VERSION ""

NS_ :

BS_:

BU_: HS_TESTER CPM AHU MFD IPC DSP _delete

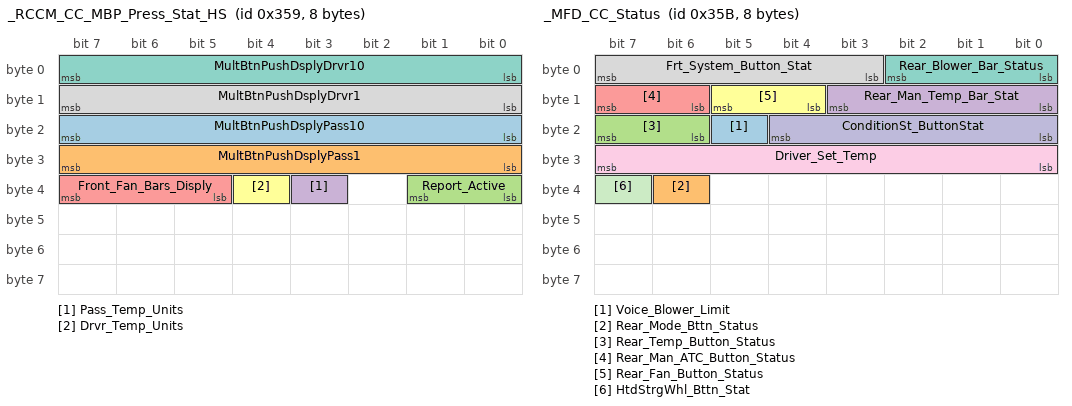
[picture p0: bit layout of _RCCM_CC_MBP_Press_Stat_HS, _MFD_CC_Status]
BO_ 857 _RCCM_CC_MBP_Press_Stat_HS: 8 IPC
 SG_ MultBtnPushDsplyPass10 : 23|8@0+ (1,0) [0|255] ""  MFD
 SG_ MultBtnPushDsplyPass1 : 31|8@0+ (1,0) [0|255] ""  MFD
 SG_ Report_Active : 33|2@0+ (1,0) [0|0] ""  MFD
 SG_ Pass_Temp_Units : 35|1@0+ (1,0) [0|0] ""  MFD
 SG_ Front_Fan_Bars_Disply : 39|3@0+ (1,0) [0|0] ""  MFD
 SG_ Drvr_Temp_Units : 36|1@0+ (1,0) [0|0] ""  MFD
 SG_ MultBtnPushDsplyDrvr10 : 7|8@0+ (1,0) [0|255] ""  MFD
 SG_ MultBtnPushDsplyDrvr1 : 15|8@0+ (1,0) [0|255] ""  MFD

BO_ 859 _MFD_CC_Status: 8 CPM
 SG_ Voice_Blower_Limit : 21|1@0+ (1,0) [0|0] "" Vector__XXX
 SG_ Rear_Mode_Bttn_Status : 38|1@0+ (1,0) [0|0] "unitless"  IPC
 SG_ Rear_Temp_Button_Status : 23|2@0+ (1,0) [0|0] "" Vector__XXX
 SG_ Rear_Man_Temp_Bar_Stat : 11|4@0+ (1,0) [0|0] "" Vector__XXX
 SG_ Rear_Man_ATC_Button_Status : 15|2@0+ (1,0) [0|0] "" Vector__XXX
 SG_ Rear_Fan_Button_Status : 13|2@0+ (1,0) [0|0] "" Vector__XXX
 SG_ Rear_Blower_Bar_Status : 2|3@0+ (1,0) [0|7] "" Vector__XXX
 SG_ Frt_System_Button_Stat : 7|5@0+ (1,0) [0|0] ""  IPC
 SG_ Driver_Set_Temp : 31|8@0+ (0.5,0) [16|90] "Degrees"  IPC
 SG_ ConditionSt_ButtonStat : 20|5@0+ (1,0) [0|0] "SED" Vector__XXX
 SG_ HtdStrgWhl_Bttn_Stat : 39|1@0+ (1,0) [0|0] "" Vector__XXX

BO_ 858 _IPC_CC_Request: 8 IPC
 SG_ Left_Front_Temp_Setpt : 7|8@0+ (1,0) [0|0] "Mixed"  MFD
 SG_ Front_Blower_Request : 15|5@0+ (1,0) [0|31] ""  MFD

BO_ 293 _ClmtCtrlSeatSetStat_v2_HS: 8 IPC
 SG_ ClmtCtrlSeat_SetStat_Psgr : 15|8@0+ (1,0) [0|254] "" Vector__XXX
 SG_ ClmtCtrlSeat_SetStat_Dvr : 7|8@0+ (1,0) [0|254] "" Vector__XXX

BO_ 1068 _Battery_Mgmt_2: 8 IPC
 SG_ BSBattSOC_UB : 56|1@0+ (1,0) [0|0] "" Vector__XXX
 SG_ BSBattSOC : 63|7@0+ (1,0) [0|127] "%" Vector__XXX
 SG_ Shed_T_Eng_Off_B_UB : 31|1@0+ (1,0) [0|1] "SED" Vector__XXX
 SG_ Shed_Drain_Eng_Off_B_UB : 22|1@0+ (1,0) [0|1] "SED" Vector__XXX
 SG_ PwPckTqRdy_B_Dsply_UB : 20|1@0+ (1,0) [0|1] "SED" Vector__XXX
 SG_ BattTracWarnLamp_B_Rq_UB : 15|1@0+ (1,0) [0|1] "SED" Vector__XXX
 SG_ BattTracWarnLamp_B_Rq : 1|1@0+ (1,0) [0|0] "SED" Vector__XXX
 SG_ BattTracSrvcRqd_B_Rq_UB : 14|1@0+ (1,0) [0|1] "SED" Vector__XXX
 SG_ BattTracSrvcRqd_B_Rq : 0|1@0+ (1,0) [0|0] "SED" Vector__XXX
 SG_ BattTracSoc_Pc_Dsply_UB : 52|1@0+ (1,0) [0|1] "SED" Vector__XXX
 SG_ BattTracSoc_Pc_Dsply : 39|8@0+ (0.5,0) [0|127.5] "%" Vector__XXX
 SG_ HtrnWarnLamp_B_Dsply_UB : 28|1@0+ (1,0) [0|1] "SED" Vector__XXX
 SG_ HtrnWarnLamp_B_Dsply : 19|1@0+ (1,0) [0|0] "SED" Vector__XXX
 SG_ HtrnSrvcRqd_B_Dsply_UB : 29|1@0+ (1,0) [0|1] "SED" Vector__XXX
 SG_ HtrnSrvcRqd_B_Dsply : 30|1@0+ (1,0) [0|0] "SED" Vector__XXX
 SG_ HtrnOvrTeLamp_B_Dsply_UB : 26|1@0+ (1,0) [0|1] "SED" Vector__XXX
 SG_ HtrnOvrTeLamp_B_Dsply : 27|1@0+ (1,0) [0|0] "SED" Vector__XXX
 SG_ PwPckTqRdy_B_Dsply : 21|1@0+ (1,0) [0|0] "SED" Vector__XXX
 SG_ Shed_T_Eng_Off_B : 17|1@0+ (1,0) [0|0] ""  MFD
 SG_ Shed_Level_Req : 55|3@0+ (1,0) [0|0] "SED"  MFD
 SG_ Shed_Drain_Eng_Off_B : 16|1@0+ (1,0) [0|0] ""  MFD
 SG_ Batt_Lo_SoC_B : 25|1@0+ (1,0) [0|0] "SED"  MFD
 SG_ Batt_Crit_SoC_B : 24|1@0+ (1,0) [0|0] "SED"  MFD
 SG_ VehDynamicsSOS : 51|1@0+ (1,0) [0|1] "SED" Vector__XXX
 SG_ VehDynamicsSOS_UB : 50|1@0+ (1,0) [0|1] "SED" Vector__XXX
 SG_ ObjectEntrapped_UB : 2|1@0+ (1,0) [0|1] "SED" Vector__XXX
 SG_ Batt_Lo_SoC_B_UB : 13|1@0+ (1,0) [0|1] "SED" Vector__XXX
 SG_ ObjectEntrapped : 3|1@0+ (1,0) [0|1] "SED" Vector__XXX
 SG_ Shed_Level_Req_UB : 18|1@0+ (1,0) [0|1] "SED" Vector__XXX
 SG_ PwSysULoFalt_D_Stat_UB : 23|1@0+ (1,0) [0|1] "SED" Vector__XXX
 SG_ PwSysULoFalt_D_Stat : 11|4@0+ (1,0) [0|15] "SED" Vector__XXX
 SG_ CcStat_D_Actl_UB : 4|1@0+ (1,0) [0|1] "SED" Vector__XXX
 SG_ CcStat_D_Actl : 7|3@0+ (1,0) [0|7] "SED" Vector__XXX
 SG_ Batt_Crit_SoC_B_UB : 12|1@0+ (1,0) [0|1] "SED" Vector__XXX
 SG_ TrlrAidEnbl_D_Stat_UB : 49|1@0+ (1,0) [0|0] "" Vector__XXX
 SG_ TrlrAidMsgTxt_D_Rq_UB : 48|1@0+ (1,0) [0|0] "" Vector__XXX
 SG_ TrlrAidEnbl_D_Stat : 42|3@0+ (1,0) [0|0] "SED" Vector__XXX
 SG_ TrlrAidMsgTxt_D_Rq : 47|5@0+ (1,0) [0|0] "SED" Vector__XXX

BO_ 1931 TesterPhysicalResDSP: 8 DSP
 SG_ TesterPhysicalResDSP : 7|64@0+ (1,0) [0|1.84467440737096E+019] "unitless"  IPC

BO_ 757 ACU_Send_Signals_13: 8 AHU
 SG_ ACU_AutoStoreResult_St : 1|2@0+ (1,0) [0|0] "unitless"  MFD
 SG_ ACU_DirectTune_St : 3|2@0+ (1,0) [0|0] "unitless"  CPM,MFD,IPC
 SG_ ACU_RadioSeekMode2_St : 15|5@0+ (1,0) [0|0] "unitless"  MFD,IPC
 SG_ ACU_CurrTUBand_St : 7|4@0+ (1,0) [0|0] "unitless"  CPM,MFD,DSP,IPC

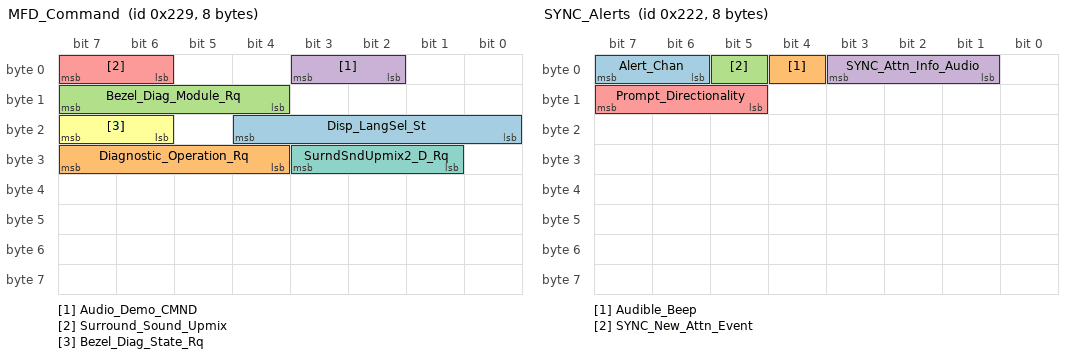
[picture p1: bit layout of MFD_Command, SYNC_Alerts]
BO_ 553 MFD_Command: 8 MFD
 SG_ Disp_LangSel_St : 20|5@0+ (1,0) [0|0] "unitless"  CPM,IPC
 SG_ Diagnostic_Operation_Rq : 31|4@0+ (1,0) [0|0] ""  DSP,AHU
 SG_ Bezel_Diag_Module_Rq : 15|4@0+ (1,0) [0|0] ""  DSP,AHU
 SG_ Audio_Demo_CMND : 3|2@0+ (1,0) [0|0] ""  DSP,AHU
 SG_ Surround_Sound_Upmix : 7|2@0+ (1,0) [0|0] ""  DSP
 SG_ Bezel_Diag_State_Rq : 23|2@0+ (1,0) [0|0] ""  DSP,AHU
 SG_ SurndSndUpmix2_D_Rq : 27|3@0+ (1,0) [0|0] ""  DSP

BO_ 257 MFD_Request_Signals1: 8 MFD
 SG_ MFD_SetTagMode : 39|2@0+ (1,0) [0|0] ""  AHU
 SG_ MFD_SetRBDSMode : 47|2@0+ (1,0) [0|0] ""  AHU
 SG_ MFD_SetHDModeRq : 31|2@0+ (1,0) [0|0] ""  AHU
 SG_ MFD_GetTagInfo : 7|4@0+ (1,0) [0|0] ""  AHU

BO_ 546 SYNC_Alerts: 8 CPM
 SG_ Alert_Chan : 7|2@0+ (1,0) [0|0] ""  DSP,AHU
 SG_ Audible_Beep : 4|1@0+ (1,0) [0|0] ""  DSP,AHU
 SG_ SYNC_New_Attn_Event : 5|1@0+ (1,0) [0|0] "SED"  DSP,AHU
 SG_ SYNC_Attn_Info_Audio : 3|3@0+ (1,0) [0|0] "SED"  DSP,AHU
 SG_ Prompt_Directionality : 15|3@0+ (1,0) [0|0] ""  DSP,AHU

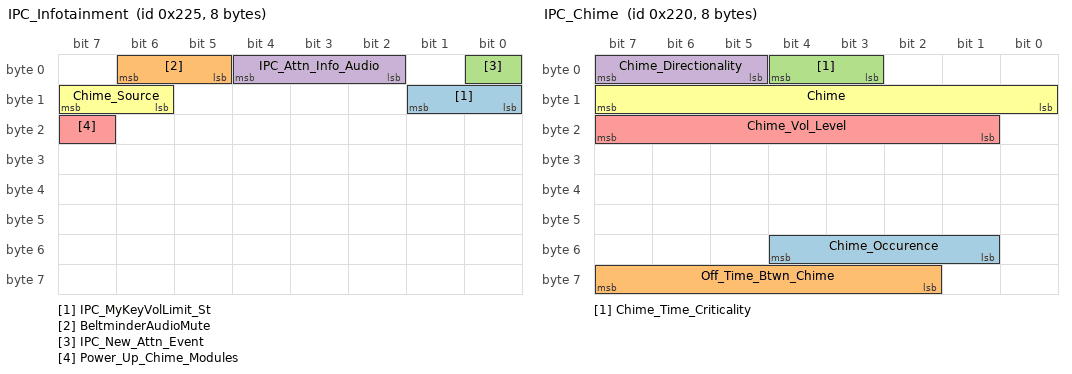
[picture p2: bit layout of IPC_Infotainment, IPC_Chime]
BO_ 549 IPC_Infotainment: 8 IPC
 SG_ IPC_MyKeyVolLimit_St : 9|2@0+ (1,0) [0|0] ""  DSP,AHU
 SG_ BeltminderAudioMute : 6|2@0+ (1,0) [0|0] "unitless"  DSP,AHU
 SG_ IPC_New_Attn_Event : 0|1@0+ (1,0) [0|0] ""  DSP,AHU
 SG_ IPC_Attn_Info_Audio : 4|3@0+ (1,0) [0|0] "SED"  DSP,AHU
 SG_ Power_Up_Chime_Modules : 23|1@0+ (1,0) [0|0] "unitless"  DSP,AHU
 SG_ Chime_Source : 15|2@0+ (1,0) [0|0] "unitless"  DSP,AHU

BO_ 544 IPC_Chime: 8 IPC
 SG_ Chime_Occurence : 52|4@0+ (1,0) [0|0] "unitless"  AHU,DSP
 SG_ Off_Time_Btwn_Chime : 63|6@0+ (1,0) [0|52] "unitless"  AHU,DSP
 SG_ Chime_Time_Criticality : 4|2@0+ (1,0) [0|0] "unitless"  AHU,DSP
 SG_ Chime_Directionality : 7|3@0+ (1,0) [0|0] "unitless"  AHU,DSP
 SG_ Chime_Vol_Level : 23|7@0+ (1,0) [0|127] "unitless"  AHU,DSP
 SG_ Chime : 15|8@0+ (1,0) [0|255] "unitless"  AHU,DSP

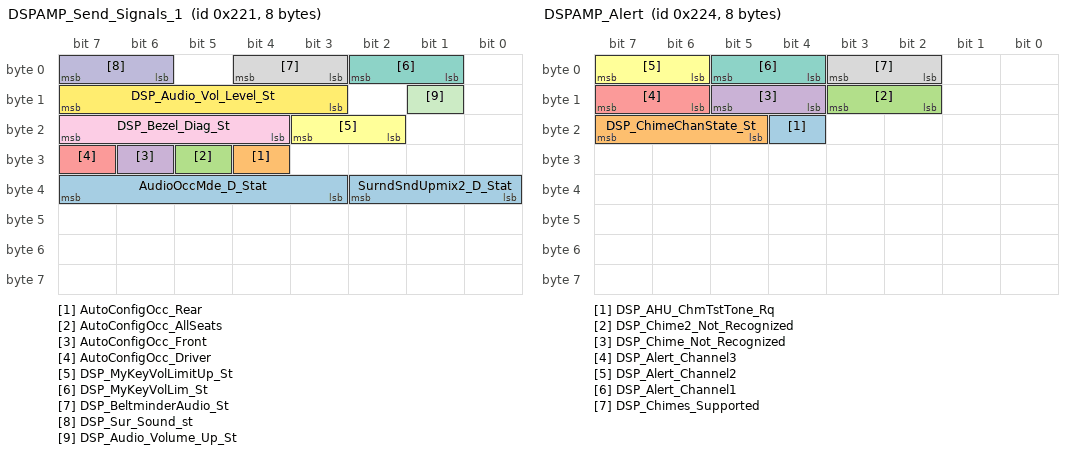
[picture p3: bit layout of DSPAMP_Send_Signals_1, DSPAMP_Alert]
BO_ 545 DSPAMP_Send_Signals_1: 8 DSP
 SG_ AudioOccMde_D_Stat : 39|5@0+ (1,0) [0|0] "" Vector__XXX
 SG_ AutoConfigOcc_Rear : 28|1@0+ (1,0) [0|0] "" Vector__XXX
 SG_ AutoConfigOcc_AllSeats : 29|1@0+ (1,0) [0|0] "" Vector__XXX
 SG_ AutoConfigOcc_Front : 30|1@0+ (1,0) [0|0] "" Vector__XXX
 SG_ AutoConfigOcc_Driver : 31|1@0+ (1,0) [0|0] "" Vector__XXX
 SG_ DSP_MyKeyVolLimitUp_St : 19|2@0+ (1,0) [0|0] ""  MFD
 SG_ DSP_MyKeyVolLim_St : 2|2@0+ (1,0) [0|0] ""  MFD
 SG_ DSP_BeltminderAudio_St : 4|2@0+ (1,0) [0|0] ""  MFD
 SG_ DSP_Bezel_Diag_St : 23|4@0+ (1,0) [0|0] ""  MFD
 SG_ DSP_Sur_Sound_st : 7|2@0+ (1,0) [0|0] ""  MFD
 SG_ DSP_Audio_Volume_Up_St : 9|1@0+ (1,0) [0|0] ""  MFD
 SG_ DSP_Audio_Vol_Level_St : 15|5@0+ (1,0) [0|31] "percent"  MFD
 SG_ SurndSndUpmix2_D_Stat : 34|3@0+ (1,0) [0|0] "" Vector__XXX

BO_ 552 DSPAMP_Send_Signals: 8 DSP
 SG_ DSP_Midrange_St : 51|4@0+ (1,-7) [-7|8] ""  MFD
 SG_ DSP_VoiceFBVolume_Up : 35|1@0+ (1,0) [0|0] ""  MFD
 SG_ DSP_VoiceFBVolume_St : 63|5@0+ (1,0) [0|30] ""  MFD
 SG_ DSP_Treble_St : 55|4@0+ (1,-7) [-7|8] ""  MFD
 SG_ DSP_TAVolume_Up : 34|1@0+ (1,0) [0|0] ""  MFD
 SG_ DSP_TAVolume_St : 44|5@0+ (1,0) [0|30] ""  MFD
 SG_ DSP_PhoneVolume_Up : 25|1@0+ (1,0) [0|0] ""  MFD
 SG_ DSP_PhoneVolume_St : 33|5@0+ (1,0) [0|30] ""  MFD
 SG_ DSP_NavCmdVolume_Up : 7|1@0+ (1,0) [0|0] ""  MFD
 SG_ DSP_NavCmdVolume_St : 24|5@0+ (1,0) [0|30] ""  MFD
 SG_ DSP_Fader_St : 20|4@0+ (1,-7) [-7|8] ""  MFD
 SG_ DSP_DSPProgram_St : 15|3@0+ (1,0) [0|0] ""  MFD
 SG_ DSP_DSP_St : 16|5@0+ (1,0) [0|0] ""  MFD
 SG_ DSP_Bass_St : 12|4@0+ (1,-7) [-7|8] ""  MFD
 SG_ DSP_Balance_St : 8|4@0+ (1,-7) [-7|8] ""  MFD
 SG_ DSP_AVC_St : 6|3@0+ (1,0) [0|0] ""  MFD
 SG_ DSP_Shaker_St : 1|1@0+ (1,0) [0|0] ""  MFD
 SG_ Audio_Demo_Status : 0|1@0+ (1,0) [0|0] ""  MFD

BO_ 548 DSPAMP_Alert: 8 DSP
 SG_ DSP_AHU_ChmTstTone_Rq : 20|1@0+ (1,0) [0|0] ""  AHU
 SG_ DSP_ChimeChanState_St : 23|3@0+ (1,0) [0|0] ""  AHU
 SG_ DSP_Chime2_Not_Recognized : 11|2@0+ (1,0) [0|0] "unitless"  IPC
 SG_ DSP_Chime_Not_Recognized : 13|2@0+ (1,0) [0|0] "unitless"  IPC
 SG_ DSP_Alert_Channel3 : 15|2@0+ (1,0) [0|0] "unitless"  IPC
 SG_ DSP_Alert_Channel2 : 7|2@0+ (1,0) [0|0] "unitless"  IPC,AHU
 SG_ DSP_Alert_Channel1 : 5|2@0+ (1,0) [0|0] ""  AHU
 SG_ DSP_Chimes_Supported : 3|2@0+ (1,0) [0|0] "unitless"  AHU,IPC

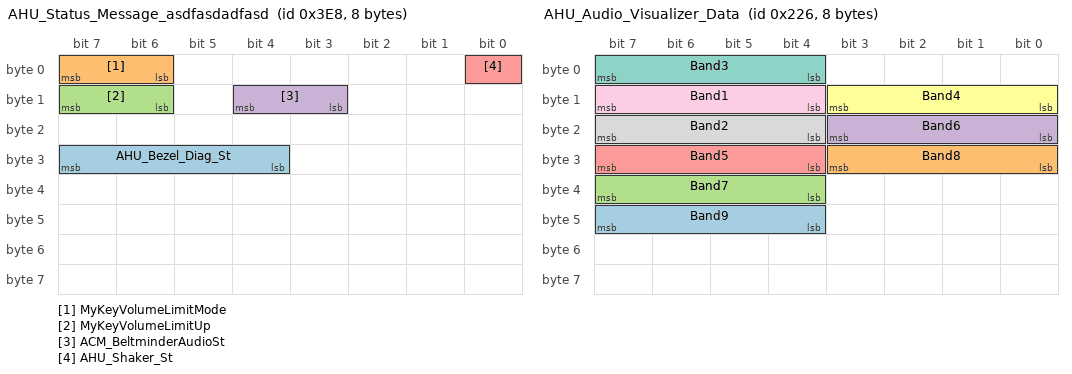
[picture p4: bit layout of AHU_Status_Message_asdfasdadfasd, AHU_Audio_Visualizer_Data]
BO_ 1000 AHU_Status_Message_asdfasdadfasd: 8 AHU
 SG_ AHU_Bezel_Diag_St : 31|4@0+ (1,0) [0|0] ""  MFD
 SG_ MyKeyVolumeLimitMode : 7|2@0+ (1,0) [0|0] ""  MFD
 SG_ MyKeyVolumeLimitUp : 15|2@0+ (1,0) [0|0] ""  MFD
 SG_ ACM_BeltminderAudioSt : 12|2@0+ (1,0) [0|0] ""  MFD
 SG_ AHU_Shaker_St : 0|1@0+ (1,0) [0|0] ""  MFD

BO_ 1478 DSP_AutoSar_Network_Mgmt: 8 DSP
 SG_ DSP_AutoSar_Network_Mgmt : 7|64@0+ (1,0) [0|1.8446744074E+019] "unitless" Vector__XXX

BO_ 1506 APIM_AutoSar_Network_Mgmt: 8 CPM
 SG_ APIM_AutoSar_Network_Mgmt : 7|64@0+ (1,0) [0|1.8446744074E+019] "unitless" Vector__XXX

BO_ 1034 _GGCC_Config_Mgmt_ID_1: 8 IPC
 SG_ VehicleGGCCData : 7|64@0+ (1,0) [0|1.84467E+019] "mixed"  CPM,AHU

BO_ 405 LBClient1_Request_Signals: 8 IPC
 SG_ LBC1_StartItemInd : 55|16@0+ (1,0) [0|65535] "unitless" Vector__XXX
 SG_ LBC1_SetListServ : 47|8@0+ (1,0) [0|255] "unitless" Vector__XXX
 SG_ LBC1_Opcode : 39|2@0+ (1,0) [0|3] "unitless" Vector__XXX
 SG_ LBC1_NbrOfItems : 37|6@0+ (1,0) [0|63] "unitless" Vector__XXX
 SG_ LBC1_ItemIndex : 23|16@0+ (1,0) [0|65535] "unitless" Vector__XXX
 SG_ LBC1_ActiveListID : 7|16@0+ (1,0) [0|65535] "unitless" Vector__XXX

BO_ 550 AHU_Audio_Visualizer_Data: 8 AHU
 SG_ Band9 : 47|4@0+ (1,0) [0|0] "" Vector__XXX
 SG_ Band8 : 27|4@0+ (1,0) [0|0] "" Vector__XXX
 SG_ Band7 : 39|4@0+ (1,0) [0|0] "" Vector__XXX
 SG_ Band6 : 19|4@0+ (1,0) [0|0] "" Vector__XXX
 SG_ Band5 : 31|4@0+ (1,0) [0|0] "" Vector__XXX
 SG_ Band4 : 11|4@0+ (1,0) [0|0] "" Vector__XXX
 SG_ Band3 : 7|4@0+ (1,0) [0|0] "" Vector__XXX
 SG_ Band2 : 23|4@0+ (1,0) [0|0] "" Vector__XXX
 SG_ Band1 : 15|4@0+ (1,0) [0|0] "" Vector__XXX

BO_ 755 ACU_Send_Signals_11: 8 AHU
 SG_ ACU_AudioMixRatio_St : 4|5@0+ (1,0) [0|20] "decibel"  MFD

BO_ 692 AUDIO_RDISP_WORD_Tx: 8 AHU
 SG_ AUDIO_RDISP_WORD_Tx : 7|64@0+ (1,0) [0|1.84467440737096E+019] "unitless"  MFD

BO_ 700 AUDIO_RDISP_WORD_Rx: 8 MFD
 SG_ AUDIO_RDISP_WORD_Rx : 7|64@0+ (1,0) [0|1.84467440737096E+019] "unitless"  AHU

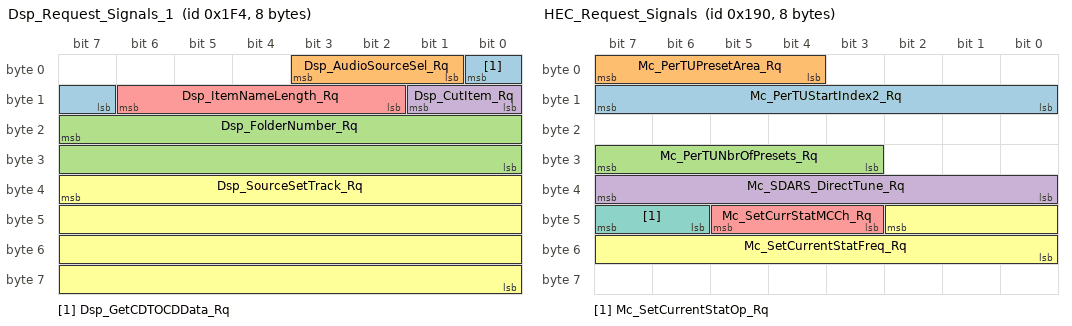
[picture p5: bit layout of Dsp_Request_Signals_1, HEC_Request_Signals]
BO_ 500 Dsp_Request_Signals_1: 8 MFD
 SG_ Dsp_GetCDTOCDData_Rq : 0|2@0+ (1,0) [0|0] ""  AHU
 SG_ Dsp_AudioSourceSel_Rq : 3|3@0+ (1,0) [0|0] ""  AHU
 SG_ Dsp_FolderNumber_Rq : 23|16@0+ (1,0) [0|65535] ""  AHU
 SG_ Dsp_CutItem_Rq : 9|2@0+ (1,0) [0|0] ""  AHU
 SG_ Dsp_ItemNameLength_Rq : 14|5@0+ (1,0) [0|20] ""  AHU
 SG_ Dsp_SourceSetTrack_Rq : 39|32@0+ (1,0) [0|4294967295] ""  AHU

BO_ 501 Dsp_Request_Signals_2: 8 MFD
 SG_ Dsp_FreezeFMSL_Rq : 57|2@0+ (1,0) [0|0] ""  AHU
 SG_ Dsp_SetCurrFMSLPr_Rq : 15|8@0+ (1,0) [0|254] ""  AHU
 SG_ Dsp_SetRadSeekMode_Rq : 61|4@0+ (1,0) [0|0] ""  AHU
 SG_ Dsp_SetCurrPreset2_Rq : 4|5@0+ (1,0) [0|30] ""  AHU

BO_ 503 Dsp_Request_Signals_4: 8 MFD
 SG_ Dsp_AudioSourceSel3_Rq : 55|3@0+ (1,0) [0|0] ""  AHU
 SG_ Dsp_PlayFrstTrInFldr_Rq : 39|16@0+ (1,0) [0|65535] ""  AHU

BO_ 698 CONMP_RDISP_WORD_Rx: 8 MFD
 SG_ CONMP_RDISP_WORD_Rx : 7|64@0+ (1,0) [0|1.84467440737096E+019] "unitless" Vector__XXX

BO_ 702 PHONE_MC_WORD_Rx: 8 IPC
 SG_ PHONE_MC_WORD_Rx : 7|64@0+ (1,0) [0|1.84467440737096E+019] "unitless" Vector__XXX

BO_ 699 PHONE_RDSP_WORD_Rx: 8 MFD
 SG_ PHONE_RDSP_WORD_Rx : 7|64@0+ (1,0) [0|1.84467440737096E+019] "unitless"  CPM

BO_ 691 PHONE_RDSP_WORD_Tx: 8 CPM
 SG_ PHONE_RDSP_WORD_Tx : 7|64@0+ (1,0) [0|1.84467440737096E+019] "unitless"  MFD

BO_ 689 AUDIO_MC_WORD_Tx: 8 AHU
 SG_ AUDIO_MC_WORD_Tx : 7|64@0+ (1,0) [0|1.84467440737096E+019] "unitless"  IPC

BO_ 401 MFD_Request_Signals4: 8 MFD
 SG_ Disp_VehUnitTripCoUsrSel : 3|2@0+ (1,0) [0|0] "unitless"  IPC
 SG_ Disp_VehUnitTempUsrSel : 5|2@0+ (1,0) [0|0] "unitless"  IPC
 SG_ Disp_LangSel_Rq : 15|5@0+ (1,0) [0|0] "unitless"  IPC

BO_ 400 HEC_Request_Signals: 8 IPC
 SG_ Mc_PerTUStartIndex2_Rq : 15|8@0+ (1,0) [0|255] "unitless" Vector__XXX
 SG_ Mc_PerTUPresetArea_Rq : 7|4@0+ (1,0) [0|0] "unitless" Vector__XXX
 SG_ Mc_PerTUNbrOfPresets_Rq : 31|5@0+ (1,0) [0|30] "unitless" Vector__XXX
 SG_ Mc_SDARS_DirectTune_Rq : 39|8@0+ (1,0) [0|255] "unitless"  AHU
 SG_ Mc_SetCurrStatMCCh_Rq : 45|3@0+ (1,0) [0|0] "unitless"  AHU
 SG_ Mc_SetCurrentStatFreq_Rq : 42|11@0+ (1,0) [0|1557] "unitless"  AHU
 SG_ Mc_SetCurrentStatOp_Rq : 47|2@0+ (1,0) [0|0] "unitless"  AHU

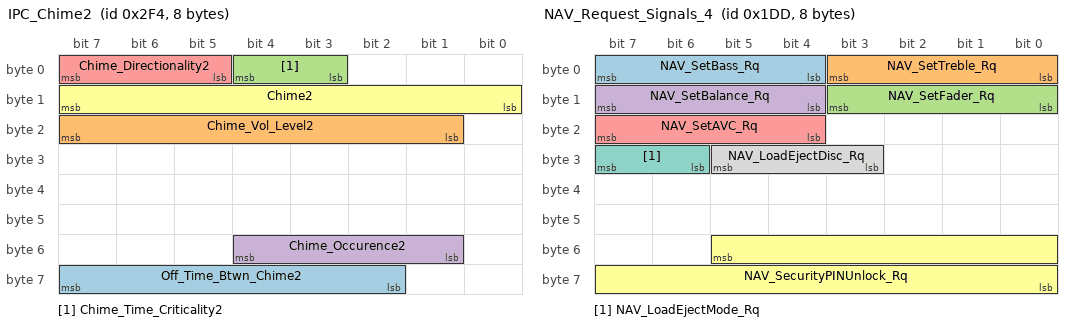
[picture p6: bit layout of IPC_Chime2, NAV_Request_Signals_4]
BO_ 756 IPC_Chime2: 8 IPC
 SG_ Off_Time_Btwn_Chime2 : 63|6@0+ (1,0) [0|52] "unitless"  AHU,DSP
 SG_ Chime_Vol_Level2 : 23|7@0+ (1,0) [0|127] "unitless"  DSP,AHU
 SG_ Chime_Time_Criticality2 : 4|2@0+ (1,0) [0|0] "unitless"  AHU,DSP
 SG_ Chime_Occurence2 : 52|4@0+ (1,0) [0|0] "unitless"  AHU,DSP
 SG_ Chime_Directionality2 : 7|3@0+ (1,0) [0|0] "unitless"  AHU,DSP
 SG_ Chime2 : 15|8@0+ (1,0) [0|255] "unitless"  AHU,DSP

BO_ 1425 IPC_AutoSar_Network_Mgmt: 8 IPC
 SG_ IPC_AutoSar_Network_Mgmt : 7|64@0+ (1,0) [0|1.8446744074E+019] "unitless" Vector__XXX

BO_ 477 NAV_Request_Signals_4: 8 MFD
 SG_ NAV_SetBass_Rq : 7|4@0+ (1,-7) [-7|8] ""  AHU,DSP
 SG_ NAV_SetTreble_Rq : 3|4@0+ (1,-7) [-7|8] ""  AHU,DSP
 SG_ NAV_SetFader_Rq : 11|4@0+ (1,-7) [-7|8] ""  AHU,DSP
 SG_ NAV_SetBalance_Rq : 15|4@0+ (1,-7) [-7|8] ""  AHU,DSP
 SG_ NAV_SetAVC_Rq : 23|4@0+ (1,0) [0|15] ""  AHU,DSP
 SG_ NAV_SecurityPINUnlock_Rq : 53|14@0+ (1,0) [0|16383] ""  AHU
 SG_ NAV_LoadEjectMode_Rq : 31|2@0+ (1,0) [0|0] ""  AHU
 SG_ NAV_LoadEjectDisc_Rq : 29|3@0+ (1,0) [0|0] ""  AHU

BO_ 476 NAV_Request_Signals_3: 8 MFD
 SG_ NAV_SetDSPProgram_Rq : 13|3@0+ (1,0) [0|0] ""  AHU,DSP
 SG_ NAV_SkipCatalouge_Rq : 7|2@0+ (1,0) [0|0] ""  AHU
 SG_ NAV_SetOperationMode_Rq : 26|3@0+ (1,0) [0|0] ""  AHU
 SG_ Nav_SetAudioMixRatio_Rq : 31|5@0+ (1,0) [0|20] "decibel"  AHU

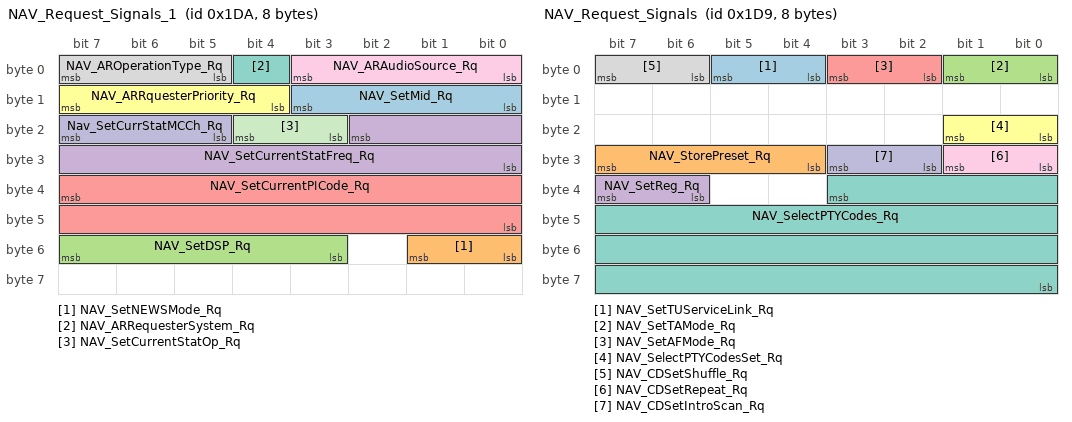
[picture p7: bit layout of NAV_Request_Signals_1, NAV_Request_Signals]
BO_ 474 NAV_Request_Signals_1: 8 MFD
 SG_ NAV_SetMid_Rq : 11|4@0+ (1,-7) [-7|8] ""  AHU,DSP
 SG_ NAV_SetNEWSMode_Rq : 49|2@0+ (1,0) [0|0] ""  AHU
 SG_ NAV_SetDSP_Rq : 55|5@0+ (1,0) [0|0] ""  AHU
 SG_ NAV_SetCurrentStatFreq_Rq : 18|11@0+ (1,0) [0|1557] ""  AHU
 SG_ NAV_SetCurrentPICode_Rq : 39|16@0+ (1,0) [0|65535] ""  AHU
 SG_ NAV_ARRquesterPriority_Rq : 15|4@0+ (1,0) [0|0] ""  DSP,AHU
 SG_ NAV_ARRequesterSystem_Rq : 4|1@0+ (1,0) [0|0] ""  DSP,AHU
 SG_ NAV_AROperationType_Rq : 7|3@0+ (1,0) [0|0] ""  DSP,AHU
 SG_ NAV_ARAudioSource_Rq : 3|4@0+ (1,0) [0|0] ""  DSP,AHU
 SG_ Nav_SetCurrStatMCCh_Rq : 23|3@0+ (1,0) [0|0] ""  AHU
 SG_ NAV_SetCurrentStatOp_Rq : 20|2@0+ (1,0) [0|0] ""  AHU

BO_ 473 NAV_Request_Signals: 8 MFD
 SG_ NAV_SetTUServiceLink_Rq : 5|2@0+ (1,0) [0|0] ""  AHU
 SG_ NAV_StorePreset_Rq : 31|4@0+ (1,0) [0|0] ""  AHU
 SG_ NAV_SetTAMode_Rq : 1|2@0+ (1,0) [0|0] ""  AHU
 SG_ NAV_SetReg_Rq : 39|2@0+ (1,0) [0|0] ""  AHU
 SG_ NAV_SetAFMode_Rq : 3|2@0+ (1,0) [0|0] ""  AHU
 SG_ NAV_SelectPTYCodesSet_Rq : 17|2@0+ (1,0) [0|0] ""  AHU
 SG_ NAV_SelectPTYCodes_Rq : 35|28@0+ (1,0) [0|268435455] ""  AHU
 SG_ NAV_CDSetShuffle_Rq : 7|2@0+ (1,0) [0|0] ""  AHU
 SG_ NAV_CDSetRepeat_Rq : 25|2@0+ (1,0) [0|0] ""  AHU
 SG_ NAV_CDSetIntroScan_Rq : 27|2@0+ (1,0) [0|0] ""  AHU

BO_ 479 DISP_Request_Signals: 8 MFD
 SG_ DISP_SetVol_Source_Rq : 19|4@0+ (1,0) [0|0] ""  DSP,AHU
 SG_ DISP_SetVol_Level_Rq : 13|6@0+ (1,0) [0|63] ""  DSP,AHU
 SG_ DISP_SetVolume_Rq : 5|6@0+ (1,-30) [-30|30] ""  AHU,DSP

BO_ 726 ACU_Send_Signals_8: 8 AHU
 SG_ ACU_AFJump_St : 51|2@0+ (1,0) [0|0] ""  MFD
 SG_ ACU_NEWSMode_St : 55|2@0+ (1,0) [0|0] ""  MFD
 SG_ ACU_SelectedPTYCodes_St : 4|29@0+ (1,0) [0|536870911] ""  MFD
 SG_ ACU_TAMode_St : 53|2@0+ (1,0) [0|0] ""  MFD

BO_ 727 ACU_Send_Signals_2: 8 AHU
 SG_ ACU_LoadEjectDisc_St : 2|3@0+ (1,0) [0|0] ""  MFD
 SG_ ACU_LoadEjectMode_St : 7|4@0+ (1,0) [0|0] ""  MFD

BO_ 119 BrakeSnData_3_HS3: 8 IPC
 SG_ BpedDrvAppl_D_Actl_UB : 55|1@0+ (1,0) [0|1] "SED" Vector__XXX
 SG_ BpedDrvAppl_D_Actl : 21|2@0+ (1,0) [0|0] "SED" Vector__XXX
 SG_ HsaStat_D_Actl_UB : 48|1@0+ (1,0) [0|1] "SED" Vector__XXX
 SG_ HsaStat_D_Actl : 51|3@0+ (1,0) [0|7] "SED" Vector__XXX
 SG_ EPAS_Failure : 53|2@0+ (1,0) [0|3] "SED" Vector__XXX
 SG_ EPAS_Failure_UB : 5|1@0+ (1,0) [0|1] "SED" Vector__XXX
 SG_ SAPPStatusCoding_UB : 54|1@0+ (1,0) [0|1] "SED"  MFD
 SG_ SAPPStatusCoding : 63|8@0+ (1,0) [0|255] "unitless"  MFD
 SG_ CcOvrrdActv_B_Actl_UB : 40|1@0+ (1,0) [0|1] "SED" Vector__XXX
 SG_ CcOvrrdActv_B_Actl : 41|1@0+ (1,0) [0|1] "SED" Vector__XXX
 SG_ EngPullUpPullDown_D_Rq_UB : 42|1@0+ (1,0) [0|1] "SED" Vector__XXX
 SG_ EngPullUpPullDown_D_Rq : 46|4@0+ (1,0) [0|15] "SED" Vector__XXX
 SG_ VehYawComp_W_Actl_UB : 6|1@0+ (1,0) [0|1] "SED" Vector__XXX
 SG_ Veh_V_DsplyCcSet : 39|8@0+ (1,0) [0|253] "Unitless" Vector__XXX
 SG_ VehYawComp_W_Actl : 3|12@0+ (0.03663,-75) [-75|74.92659] "deg/s" Vector__XXX
 SG_ VehYaw_W_Rq : 19|12@0+ (0.03663,-75) [-75|74.92659] "deg/s" Vector__XXX
 SG_ Veh_V_DsplyCcSet_UB : 4|1@0+ (1,0) [0|1] "SED" Vector__XXX
 SG_ VehYaw_W_Rq_UB : 7|1@0+ (1,0) [0|1] "SED" Vector__XXX

BO_ 2015 TesterFunctionalReq_H3: 8 AHU
 SG_ TesterFunctionalReq : 7|64@0+ (1,0) [0|0] ""  AHU,CPM,DSP,MFD,IPC

BO_ 1839 TesterPhysicalResACM: 8 AHU
 SG_ TesterPhysicalResACM : 7|64@0+ (1,0) [0|1.84467440737096E+019] "unitless"  MFD

BO_ 1831 TesterPhysicalReqACM: 8 MFD
 SG_ TesterPhysicalReqACM : 7|64@0+ (1,0) [0|1.84467440737096E+019] "unitless"  AHU

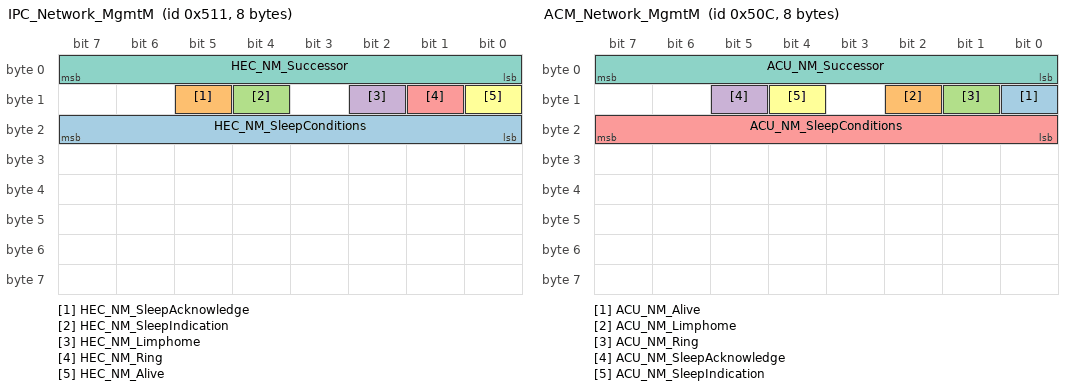
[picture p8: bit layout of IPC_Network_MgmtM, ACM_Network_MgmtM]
BO_ 1297 IPC_Network_MgmtM: 8 IPC
 SG_ HEC_NM_SleepConditions : 23|8@0+ (1,0) [0|0] "" Vector__XXX
 SG_ HEC_NM_SleepAcknowledge : 13|1@0+ (1,0) [0|0] "" Vector__XXX
 SG_ HEC_NM_SleepIndication : 12|1@0+ (1,0) [0|0] "" Vector__XXX
 SG_ HEC_NM_Limphome : 10|1@0+ (1,0) [0|0] "" Vector__XXX
 SG_ HEC_NM_Ring : 9|1@0+ (1,0) [0|0] "" Vector__XXX
 SG_ HEC_NM_Alive : 8|1@0+ (1,0) [0|0] "" Vector__XXX
 SG_ HEC_NM_Successor : 7|8@0+ (1,0) [0|0] "" Vector__XXX

BO_ 1292 ACM_Network_MgmtM: 8 AHU
 SG_ ACU_NM_Alive : 8|1@0+ (1,0) [0|0] "" Vector__XXX
 SG_ ACU_NM_Limphome : 10|1@0+ (1,0) [0|0] "" Vector__XXX
 SG_ ACU_NM_Ring : 9|1@0+ (1,0) [0|0] "" Vector__XXX
 SG_ ACU_NM_SleepAcknowledge : 13|1@0+ (1,0) [0|0] "" Vector__XXX
 SG_ ACU_NM_SleepConditions : 23|8@0+ (1,0) [0|0] "" Vector__XXX
 SG_ ACU_NM_SleepIndication : 12|1@0+ (1,0) [0|0] "" Vector__XXX
 SG_ ACU_NM_Successor : 7|8@0+ (1,0) [0|0] "" Vector__XXX

BO_ 1241 EATC_MCM: 8 IPC
 SG_ EATC_TempRangeOffset : 31|8@0+ (0.5,0) [0|127] "degC"  MFD
 SG_ EATC_TempRangeStart : 23|8@0+ (0.5,0) [0|127] "degC"  MFD
 SG_ EATC_BlowerSpeedMAX : 15|4@0+ (1,0) [0|14] ""  MFD
 SG_ EATC_BlowerSpeedMIN : 3|4@0+ (1,0) [0|14] ""  MFD

BO_ 1239 HEC_MCM: 8 IPC
 SG_ HEC_NbrOfItems_St : 27|5@0+ (1,0) [0|31] "" Vector__XXX
 SG_ HEC_ItemNameLength_St : 17|6@0+ (1,0) [0|63] "" Vector__XXX
 SG_ HEC_CutItem_St : 19|2@0+ (1,0) [0|0] "" Vector__XXX
 SG_ HEC_VehicleConfig : 23|2@0+ (1,0) [0|0] ""  MFD

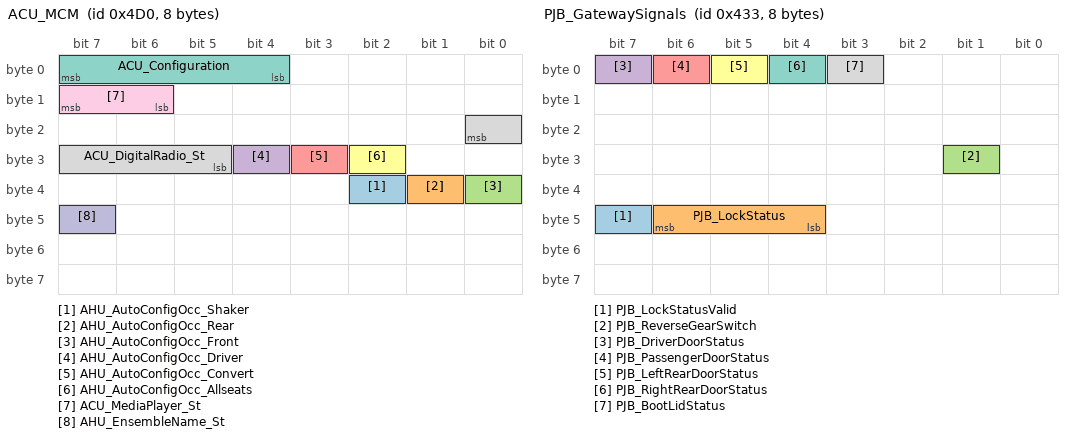
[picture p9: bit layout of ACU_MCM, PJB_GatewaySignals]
BO_ 1232 ACU_MCM: 8 AHU
 SG_ AHU_AutoConfigOcc_Shaker : 34|1@0+ (1,0) [0|0] ""  MFD
 SG_ AHU_AutoConfigOcc_Rear : 33|1@0+ (1,0) [0|0] ""  MFD
 SG_ AHU_AutoConfigOcc_Front : 32|1@0+ (1,0) [0|0] ""  MFD
 SG_ AHU_AutoConfigOcc_Driver : 28|1@0+ (1,0) [0|0] ""  MFD
 SG_ AHU_AutoConfigOcc_Convert : 27|1@0+ (1,0) [0|0] ""  MFD
 SG_ AHU_AutoConfigOcc_Allseats : 26|1@0+ (1,0) [0|0] ""  MFD
 SG_ ACU_Configuration : 7|4@0+ (1,0) [0|0] ""  MFD,IPC
 SG_ ACU_DigitalRadio_St : 16|4@0+ (1,0) [0|0] ""  MFD
 SG_ ACU_MediaPlayer_St : 15|2@0+ (1,0) [0|0] ""  MFD,IPC
 SG_ AHU_EnsembleName_St : 47|1@0+ (1,0) [0|0] ""  MFD

BO_ 1075 PJB_GatewaySignals: 8 IPC
 SG_ PJB_LockStatusValid : 47|1@0+ (1,0) [0|0] ""  MFD
 SG_ PJB_LockStatus : 46|3@0+ (1,0) [0|0] ""  MFD
 SG_ PJB_ReverseGearSwitch : 25|1@0+ (1,0) [0|0] "" Vector__XXX
 SG_ PJB_DriverDoorStatus : 7|1@0+ (1,0) [0|0] ""  CPM,MFD
 SG_ PJB_PassengerDoorStatus : 6|1@0+ (1,0) [0|0] ""  MFD
 SG_ PJB_LeftRearDoorStatus : 5|1@0+ (1,0) [0|0] ""  MFD
 SG_ PJB_RightRearDoorStatus : 4|1@0+ (1,0) [0|0] ""  MFD
 SG_ PJB_BootLidStatus : 3|1@0+ (1,0) [0|0] ""  MFD

BO_ 1029 VehicleInfo: 8 IPC
 SG_ VehicleInfoSignal : 7|64@0+ (1,0) [0|0] ""  MFD,AHU

BO_ 1024 CarConfig: 8 IPC
 SG_ CarConfigSignal : 7|64@0+ (1,0) [0|0] ""  AHU,MFD

BO_ 739 HMI_Send_Signals_7: 8 MFD
 SG_ HMI_HMIMode_St : 2|3@0+ (1,0) [0|0] "unitless"  AHU,DSP,IPC

BO_ 736 VRM_Send_Signals_3: 8 CPM
 SG_ TextMessage_Rsp : 31|2@0+ (1,0) [0|0] "unitless"  IPC
 SG_ VRM_CallDuration_St : 7|16@0+ (1,0) [0|65534] "second"  MFD,IPC
 SG_ BTInCallOptions_St : 28|3@0+ (1,0) [0|0] "unitless"  IPC

BO_ 732 ACU_Send_Signals_7: 8 AHU
 SG_ ACU_FunctionStatus_St : 7|3@0+ (1,0) [0|0] "SED"  CPM,IPC,MFD
 SG_ ACU_CurrFMSLPreset_St : 15|8@0+ (1,0) [0|255] ""  IPC,MFD
 SG_ ACU_CurrPreset2_St : 4|5@0+ (1,0) [0|31] "unitless"  CPM,IPC,MFD
 SG_ ACU_StorePreset_St : 23|5@0+ (1,0) [0|31] ""  IPC,MFD

BO_ 731 ACU_Send_Signals_6: 8 AHU
 SG_ ACU_NumberofTracks_St : 55|16@0+ (1,0) [0|65535] "unitless"  CPM,IPC,MFD
 SG_ ACU_TotalPlayTime_St : 7|16@0+ (1,-100) [-100|65434] "second"  IPC,MFD
 SG_ ACU_TrackPlaytime_St : 23|16@0+ (1,-100) [-100|65434] "second"  IPC,MFD

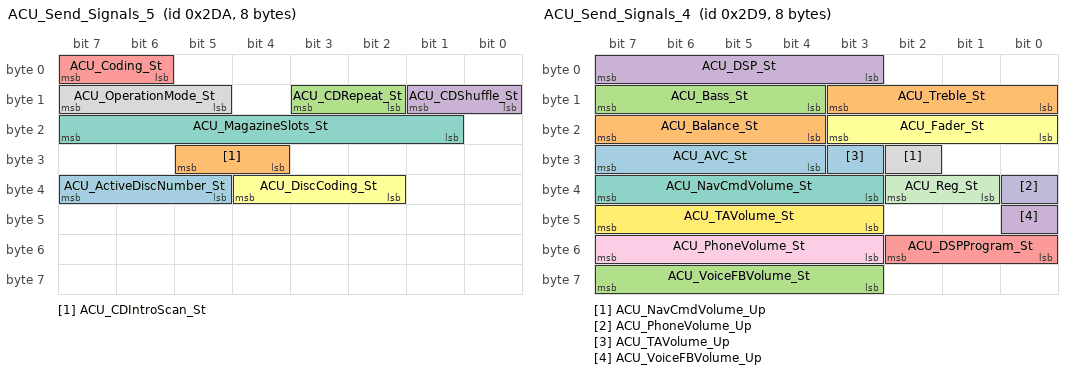
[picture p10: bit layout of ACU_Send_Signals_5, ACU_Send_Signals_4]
BO_ 730 ACU_Send_Signals_5: 8 AHU
 SG_ ACU_ActiveDiscNumber_St : 39|3@0+ (1,0) [0|6] "unitless"  IPC,MFD
 SG_ ACU_CDIntroScan_St : 29|2@0+ (1,0) [0|0] "unitless"  IPC,MFD
 SG_ ACU_CDRepeat_St : 11|2@0+ (1,0) [0|0] "unitless"  CPM,IPC,MFD
 SG_ ACU_CDShuffle_St : 9|2@0+ (1,0) [0|0] "unitless"  CPM,IPC,MFD
 SG_ ACU_Coding_St : 7|2@0+ (1,0) [0|0] "unitless"  CPM,MFD,IPC
 SG_ ACU_DiscCoding_St : 36|3@0+ (1,0) [0|0] "unitless"  CPM,MFD,IPC
 SG_ ACU_MagazineSlots_St : 23|7@0+ (1,0) [0|127] "unitless"  IPC,MFD
 SG_ ACU_OperationMode_St : 15|3@0+ (1,0) [0|0] "unitless"  CPM,IPC,MFD

BO_ 729 ACU_Send_Signals_4: 8 AHU
 SG_ ACU_AVC_St : 31|4@0+ (1,0) [0|7] ""  MFD
 SG_ ACU_Balance_St : 23|4@0+ (1,-7) [-7|8] ""  MFD
 SG_ ACU_Bass_St : 15|4@0+ (1,-7) [-7|8] ""  MFD
 SG_ ACU_DSP_St : 7|5@0+ (1,0) [0|0] ""  MFD
 SG_ ACU_DSPProgram_St : 50|3@0+ (1,0) [0|0] ""  MFD
 SG_ ACU_Fader_St : 19|4@0+ (1,-7) [-7|8] ""  MFD
 SG_ ACU_NavCmdVolume_St : 39|5@0+ (1,0) [0|30] ""  IPC,MFD
 SG_ ACU_NavCmdVolume_Up : 26|1@0+ (1,0) [0|0] ""  IPC,MFD
 SG_ ACU_PhoneVolume_St : 55|5@0+ (1,0) [0|30] ""  CPM,IPC,MFD
 SG_ ACU_PhoneVolume_Up : 32|1@0+ (1,0) [0|0] ""  CPM,IPC,MFD
 SG_ ACU_Reg_St : 34|2@0+ (1,0) [0|0] ""  MFD
 SG_ ACU_TAVolume_St : 47|5@0+ (1,0) [0|30] ""  IPC,MFD
 SG_ ACU_TAVolume_Up : 27|1@0+ (1,0) [0|0] ""  IPC,MFD
 SG_ ACU_Treble_St : 11|4@0+ (1,-7) [-7|8] ""  MFD
 SG_ ACU_VoiceFBVolume_St : 63|5@0+ (1,0) [0|30] ""  IPC,MFD
 SG_ ACU_VoiceFBVolume_Up : 40|1@0+ (1,0) [0|0] ""  IPC,MFD

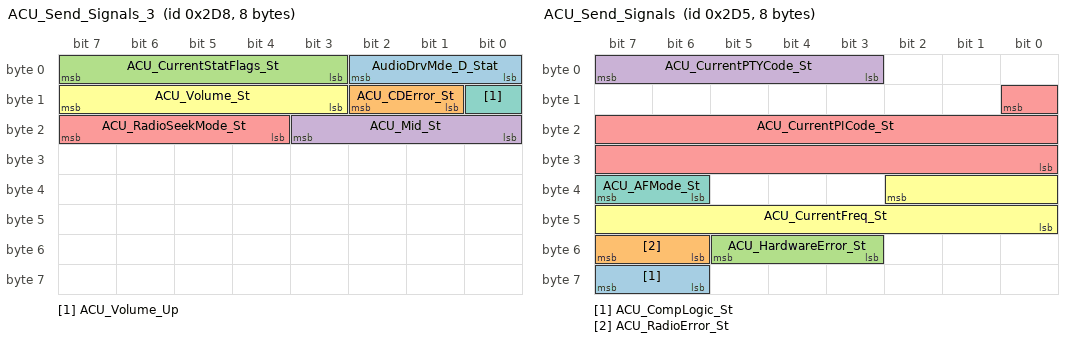
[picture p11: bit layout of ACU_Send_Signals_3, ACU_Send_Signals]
BO_ 728 ACU_Send_Signals_3: 8 AHU
 SG_ AudioDrvMde_D_Stat : 2|3@0+ (1,0) [0|7] "SED"  IPC
 SG_ ACU_CDError_St : 10|2@0+ (1,0) [0|0] ""  CPM,IPC,MFD
 SG_ ACU_CurrentStatFlags_St : 7|5@0+ (1,0) [0|31] "unitless"  MFD,IPC
 SG_ ACU_Mid_St : 19|4@0+ (1,-7) [-7|8] ""  MFD
 SG_ ACU_RadioSeekMode_St : 23|4@0+ (1,0) [0|0] ""  IPC,MFD
 SG_ ACU_Volume_St : 15|5@0+ (1,0) [0|30] "unitless"  MFD,IPC
 SG_ ACU_Volume_Up : 8|1@0+ (1,0) [0|0] "unitless"  MFD,IPC

BO_ 725 ACU_Send_Signals: 8 AHU
 SG_ ACU_CompLogic_St : 63|2@0+ (1,0) [0|0] "" Vector__XXX
 SG_ ACU_RadioError_St : 55|2@0+ (1,0) [0|0] ""  CPM,MFD,IPC
 SG_ ACU_HardwareError_St : 53|3@0+ (1,0) [0|0] ""  MFD,IPC
 SG_ ACU_CurrentPTYCode_St : 7|5@0+ (1,0) [0|31] "unitless"  MFD,IPC
 SG_ ACU_CurrentPICode_St : 8|17@0+ (1,0) [0|65535] ""  MFD
 SG_ ACU_CurrentFreq_St : 34|11@0+ (1,0) [0|1557] "unitless"  CPM,DSP,MFD,IPC
 SG_ ACU_AFMode_St : 39|2@0+ (1,0) [0|0] ""  MFD

BO_ 661 EATC_HeatersRequest: 8 IPC
 SG_ EATC_DISPupdate_Defrost : 61|1@0+ (1,0) [0|0] ""  MFD
 SG_ EATC_DISPupdate_MAXAC : 62|1@0+ (1,0) [0|0] ""  MFD
 SG_ EATC_MAXACMode : 63|1@0+ (1,0) [0|0] ""  MFD
 SG_ EATC_DISPupdate_AutoMode : 43|1@0+ (1,0) [0|0] ""  MFD
 SG_ EATC_DISPupdate_ACMode : 45|1@0+ (1,0) [0|0] ""  MFD
 SG_ EATC_DISPupdate_AirMode : 46|1@0+ (1,0) [0|0] ""  MFD
 SG_ EATC_DISPupdate_BlowerSpd : 47|1@0+ (1,0) [0|0] ""  MFD
 SG_ EATC_DISPupdate_TempCoDr : 8|1@0+ (1,0) [0|0] ""  MFD
 SG_ EATC_DISPupdate_TempDr : 9|1@0+ (1,0) [0|0] ""  MFD
 SG_ EATC_DISPupdate_SysMode : 3|1@0+ (1,0) [0|0] ""  MFD
 SG_ EATC_BlowerSpeed : 39|4@0+ (1,0) [0|14] ""  MFD
 SG_ EATC_HeatingStatus : 35|3@0+ (1,0) [0|0] ""  MFD
 SG_ EATC_TempCoDriverSet : 31|8@0+ (0.5,0) [0|127] "degC"  MFD
 SG_ EATC_TempDriverSet : 23|8@0+ (0.5,0) [0|127] "degC"  MFD
 SG_ EATC_SystemMode : 15|1@0+ (1,0) [0|0] ""  MFD
 SG_ EATC_ECOMode : 14|1@0+ (1,0) [0|0] ""  MFD
 SG_ EATC_AirToScreenMode : 13|1@0+ (1,0) [0|0] ""  MFD
 SG_ EATC_AirToPanelMode : 12|1@0+ (1,0) [0|0] ""  MFD
 SG_ EATC_AirToFloorMode : 11|1@0+ (1,0) [0|0] ""  MFD
 SG_ EATC_MonoMode : 10|1@0+ (1,0) [0|0] ""  MFD
 SG_ EATC_AutoMode : 2|1@0+ (1,0) [0|0] ""  MFD
 SG_ EATC_DefrostMode : 1|1@0+ (1,0) [0|0] ""  MFD
 SG_ EATC_RecircMode : 0|1@0+ (1,0) [0|0] ""  MFD
 SG_ EATC_DISPupdate_MonoMode : 44|1@0+ (1,0) [0|0] ""  MFD

BO_ 649 HEC_BezDimm: 8 IPC
 SG_ Ill_BEZ_HLA : 33|10@0+ (1,0) [0|1023] ""  MFD
 SG_ Ill_BEZ_NAV : 17|10@0+ (1,0) [0|1023] ""  MFD
 SG_ Ill_BEZ_ACU : 1|10@0+ (1,0) [0|1023] ""  MFD

BO_ 498 HEC_Request_Signals_3: 8 IPC
 SG_ HEC_ARRquesterPriority_Rq : 11|4@0+ (1,0) [0|0] "unitless"  AHU
 SG_ HEC_AROperationType_Rq : 7|3@0+ (1,0) [0|0] "unitless"  AHU
 SG_ HEC_ARRequesterSystem_Rq : 4|1@0+ (1,0) [0|0] "unitless"  AHU
 SG_ HEC_ARAudioSource_Rq : 3|4@0+ (1,0) [0|0] "unitless"  AHU

BO_ 490 HMI_Request_Signals_2: 8 MFD
 SG_ HMI_SkipTrack_Rq : 35|2@0+ (1,0) [0|0] ""  AHU

BO_ 489 ACU_Send_Signals_1: 8 AHU
 SG_ ACU_CurrentPSName_St : 7|64@0+ (1,0) [0|1.8446744074E+019] "unitless"  MFD,IPC

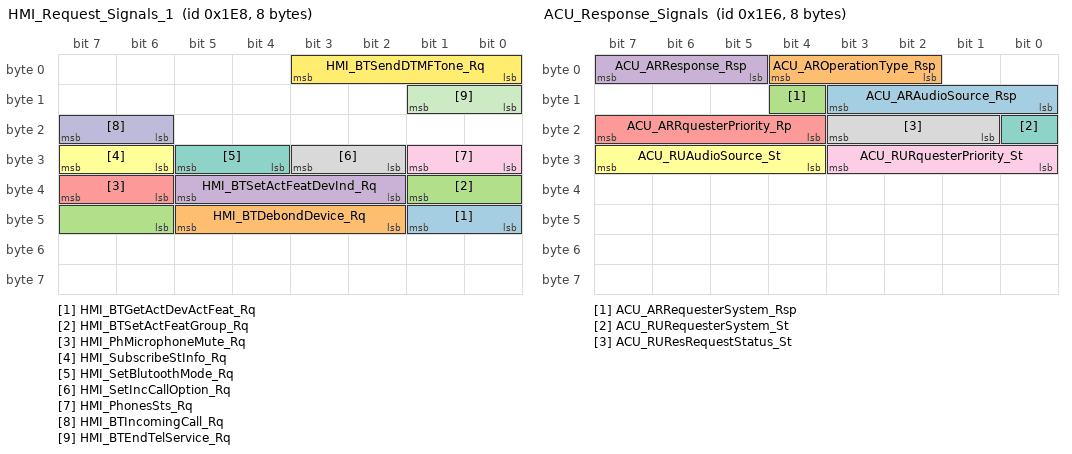
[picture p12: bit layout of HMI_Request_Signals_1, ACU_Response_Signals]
BO_ 488 HMI_Request_Signals_1: 8 MFD
 SG_ HMI_BTGetActDevActFeat_Rq : 41|2@0+ (1,0) [0|0] "" Vector__XXX
 SG_ HMI_BTDebondDevice_Rq : 45|4@0+ (1,0) [0|0] "" Vector__XXX
 SG_ HMI_BTSetActFeatGroup_Rq : 33|4@0+ (1,0) [0|0] "" Vector__XXX
 SG_ HMI_BTSetActFeatDevInd_Rq : 37|4@0+ (1,0) [0|0] "" Vector__XXX
 SG_ HMI_PhMicrophoneMute_Rq : 39|2@0+ (1,0) [0|0] "" Vector__XXX
 SG_ HMI_SubscribeStInfo_Rq : 31|2@0+ (1,0) [0|0] "" Vector__XXX
 SG_ HMI_SetBlutoothMode_Rq : 29|2@0+ (1,0) [0|0] "" Vector__XXX
 SG_ HMI_SetIncCallOption_Rq : 27|2@0+ (1,0) [0|0] "" Vector__XXX
 SG_ HMI_PhonesSts_Rq : 25|2@0+ (1,0) [0|0] "" Vector__XXX
 SG_ HMI_BTIncomingCall_Rq : 23|2@0+ (1,0) [0|0] "" Vector__XXX
 SG_ HMI_BTEndTelService_Rq : 9|2@0+ (1,0) [0|0] "" Vector__XXX
 SG_ HMI_BTSendDTMFTone_Rq : 3|4@0+ (1,0) [0|0] "" Vector__XXX

BO_ 486 ACU_Response_Signals: 8 AHU
 SG_ ACU_ARAudioSource_Rsp : 11|4@0+ (1,0) [0|0] "unitless"  CPM,MFD,DSP,IPC
 SG_ ACU_AROperationType_Rsp : 4|3@0+ (1,0) [0|0] "unitless"  CPM,MFD,DSP,IPC
 SG_ ACU_ARRequesterSystem_Rsp : 12|1@0+ (1,0) [0|0] "unitless"  CPM,MFD,DSP,IPC
 SG_ ACU_ARResponse_Rsp : 7|3@0+ (1,0) [0|0] "unitless"  CPM,MFD,DSP,IPC
 SG_ ACU_ARRquesterPriority_Rp : 23|4@0+ (1,0) [0|0] "unitless"  CPM,MFD,DSP,IPC
 SG_ ACU_RUAudioSource_St : 31|4@0+ (1,0) [0|0] "unitless"  CPM,DSP,MFD,IPC
 SG_ ACU_RURequesterSystem_St : 16|1@0+ (1,0) [0|0] "unitless"  CPM,DSP,MFD,IPC
 SG_ ACU_RUResRequestStatus_St : 19|3@0+ (1,0) [0|0] "unitless"  CPM,DSP,MFD,IPC
 SG_ ACU_RURquesterPriority_St : 27|4@0+ (1,0) [0|0] "unitless"  CPM,DSP,MFD,IPC

BO_ 469 VRM_Request_Signals: 8 CPM
 SG_ VRM_ARRquesterPriority_Rq : 15|4@0+ (1,0) [0|0] ""  AHU
 SG_ VRM_AROperationType_Rq : 7|3@0+ (1,0) [0|0] ""  AHU
 SG_ VRM_ARRequesterSystem_Rq : 4|1@0+ (1,0) [0|0] ""  AHU
 SG_ VRM_ARAudioSource_Rq : 3|4@0+ (1,0) [0|0] ""  AHU

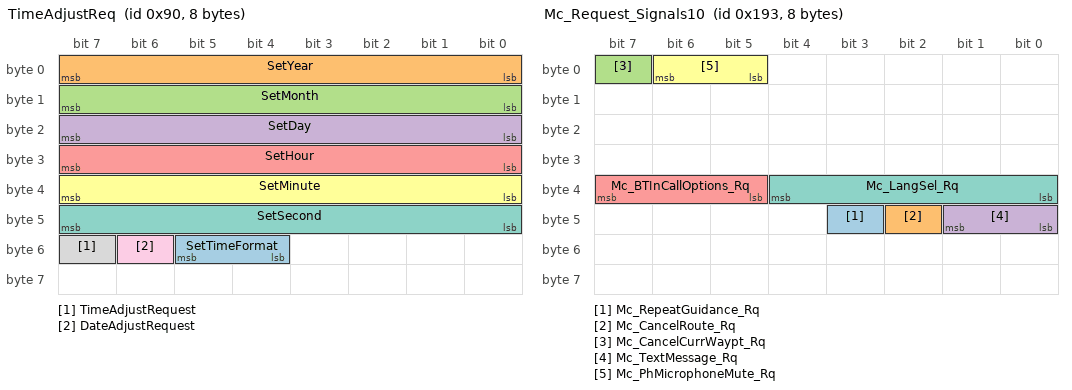
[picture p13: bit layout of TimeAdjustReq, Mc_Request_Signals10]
BO_ 144 TimeAdjustReq: 8 MFD
 SG_ SetTimeFormat : 53|2@0+ (1,0) [0|0] "unitless"  IPC
 SG_ SetYear : 7|8@0+ (1,2000) [2000|2254] "year"  IPC
 SG_ SetMonth : 15|8@0+ (1,0) [0|12] "month"  IPC
 SG_ SetDay : 23|8@0+ (1,0) [0|31] "day"  IPC
 SG_ SetHour : 31|8@0+ (1,0) [0|23] "hour"  IPC
 SG_ SetMinute : 39|8@0+ (1,0) [0|59] "minute"  IPC
 SG_ SetSecond : 47|8@0+ (1,0) [0|59] "second"  IPC
 SG_ TimeAdjustRequest : 55|1@0+ (1,0) [0|0] "unitless"  IPC
 SG_ DateAdjustRequest : 54|1@0+ (1,0) [0|0] "unitless"  IPC

BO_ 128 HEC_DateTime: 8 IPC
 SG_ HEC_Second : 47|8@0+ (1,0) [0|59] "second"  MFD
 SG_ HEC_Minute : 39|8@0+ (1,0) [0|59] "minute"  MFD
 SG_ HEC_Hour : 31|8@0+ (1,0) [0|23] "hour"  MFD
 SG_ HEC_Day : 23|8@0+ (1,0) [0|31] "day"  MFD
 SG_ HEC_Month : 15|8@0+ (1,0) [0|12] "month"  MFD
 SG_ HEC_Year : 7|8@0+ (1,2000) [2000|2254] "year"  MFD

BO_ 403 Mc_Request_Signals10: 8 IPC
 SG_ Mc_RepeatGuidance_Rq : 43|1@0+ (1,0) [0|0] "unitless" Vector__XXX
 SG_ Mc_CancelRoute_Rq : 42|1@0+ (1,0) [0|0] "unitless" Vector__XXX
 SG_ Mc_CancelCurrWaypt_Rq : 7|1@0+ (1,0) [0|0] "unitless" Vector__XXX
 SG_ Mc_TextMessage_Rq : 41|2@0+ (1,0) [0|0] "unitless" Vector__XXX
 SG_ Mc_BTInCallOptions_Rq : 39|3@0+ (1,0) [0|0] "unitless" Vector__XXX
 SG_ Mc_PhMicrophoneMute_Rq : 6|2@0+ (1,0) [0|0] "unitless" Vector__XXX
 SG_ Mc_LangSel_Rq : 36|5@0+ (1,0) [0|0] "unitless"  MFD

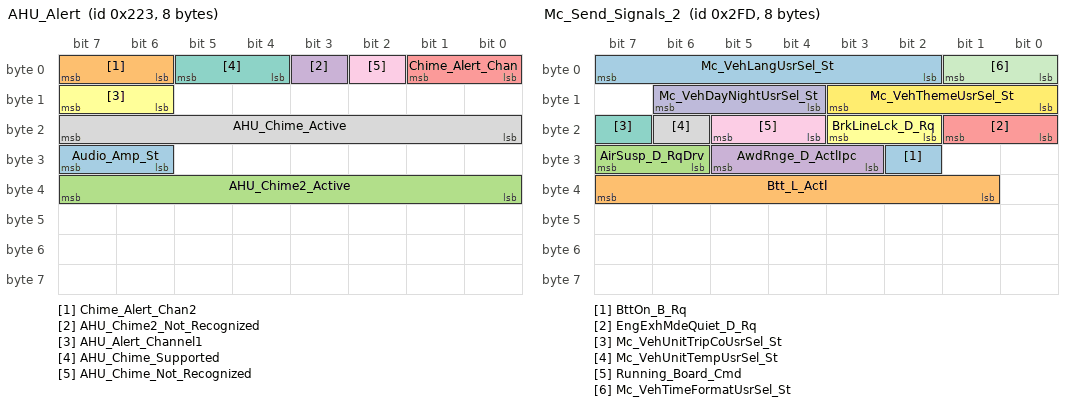
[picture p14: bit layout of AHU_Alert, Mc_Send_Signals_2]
BO_ 547 AHU_Alert: 8 AHU
 SG_ Audio_Amp_St : 31|2@0+ (1,0) [0|0] "" Vector__XXX
 SG_ Chime_Alert_Chan2 : 7|2@0+ (1,0) [0|0] "unitless"  DSP
 SG_ AHU_Chime2_Active : 39|8@0+ (1,0) [0|255] "unitless"  DSP,IPC
 SG_ AHU_Chime2_Not_Recognized : 3|1@0+ (1,0) [0|0] "unitless"  IPC
 SG_ Chime_Alert_Chan : 1|2@0+ (1,0) [0|0] "unitless"  DSP
 SG_ AHU_Alert_Channel1 : 15|2@0+ (1,0) [0|0] "unitless"  CPM
 SG_ AHU_Chime_Supported : 5|2@0+ (1,0) [0|0] "unitless"  IPC
 SG_ AHU_Chime_Active : 23|8@0+ (1,0) [0|255] "unitless"  DSP,IPC
 SG_ AHU_Chime_Not_Recognized : 2|1@0+ (1,0) [0|0] "unitless"  IPC

BO_ 765 Mc_Send_Signals_2: 8 IPC
 SG_ BttOn_B_Rq : 26|1@0+ (1,0) [0|1] "SED" Vector__XXX
 SG_ Btt_L_Actl : 39|7@0+ (0.1,0) [0|12.5] "meter" Vector__XXX
 SG_ AirSusp_D_RqDrv : 31|2@0+ (1,0) [0|3] "SED" Vector__XXX
 SG_ AwdRnge_D_ActlIpc : 29|3@0+ (1,0) [0|7] "SED" Vector__XXX
 SG_ EngExhMdeQuiet_D_Rq : 17|2@0+ (1,0) [0|3] "SED" Vector__XXX
 SG_ BrkLineLck_D_Rq : 19|2@0+ (1,0) [0|3] "SED" Vector__XXX
 SG_ Mc_VehUnitTripCoUsrSel_St : 23|1@0+ (1,0) [0|0] "unitless"  MFD
 SG_ Mc_VehUnitTempUsrSel_St : 22|1@0+ (1,0) [0|0] "unitless"  MFD
 SG_ Running_Board_Cmd : 21|2@0+ (1,0) [0|3] "SED" Vector__XXX
 SG_ Mc_VehDayNightUsrSel_St : 14|3@0+ (1,0) [0|0] "unitless"  AHU,MFD
 SG_ Mc_VehTimeFormatUsrSel_St : 1|2@0+ (1,0) [0|0] "unitless"  MFD
 SG_ Mc_VehThemeUsrSel_St : 11|4@0+ (1,0) [0|0] "unitless"  MFD
 SG_ Mc_VehLangUsrSel_St : 7|6@0+ (1,0) [0|0] "unitless"  MFD

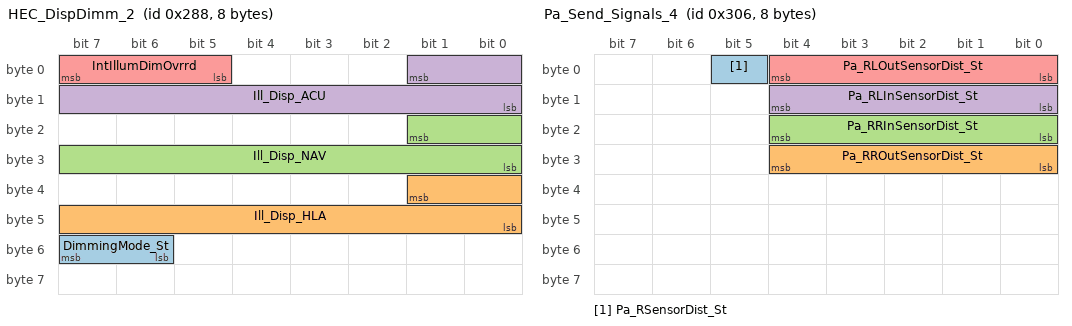
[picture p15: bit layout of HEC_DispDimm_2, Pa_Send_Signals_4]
BO_ 648 HEC_DispDimm_2: 8 IPC
 SG_ DimmingMode_St : 55|2@0+ (1,0) [0|0] ""  MFD
 SG_ Ill_Disp_HLA : 33|10@0+ (1,0) [0|1023] ""  MFD
 SG_ Ill_Disp_NAV : 17|10@0+ (1,0) [0|1023] ""  MFD
 SG_ Ill_Disp_ACU : 1|10@0+ (1,0) [0|1023] ""  MFD
 SG_ IntIllumDimOvrrd : 7|3@0+ (1,0) [0|0] ""  MFD

BO_ 774 Pa_Send_Signals_4: 8 IPC
 SG_ Pa_RSensorDist_St : 5|1@0+ (1,0) [0|0] ""  MFD
 SG_ Pa_RROutSensorDist_St : 28|5@0+ (1,0) [0|31] ""  MFD
 SG_ Pa_RRInSensorDist_St : 20|5@0+ (1,0) [0|31] ""  MFD
 SG_ Pa_RLInSensorDist_St : 12|5@0+ (1,0) [0|31] ""  MFD
 SG_ Pa_RLOutSensorDist_St : 4|5@0+ (1,0) [0|31] ""  MFD

BO_ 775 Pa_Send_Signals_3: 8 IPC
 SG_ SAPP_Status_St : 7|8@0+ (1,0) [0|0] ""  MFD

BO_ 48 GW_Send_Signal_1: 8 IPC
 SG_ WheelSpeedReL : 22|15@0+ (0.01,0) [0|327.66] "rad/s" Vector__XXX
 SG_ WheelSpeedReR : 6|15@0+ (0.01,0) [0|327.66] "rad/s" Vector__XXX

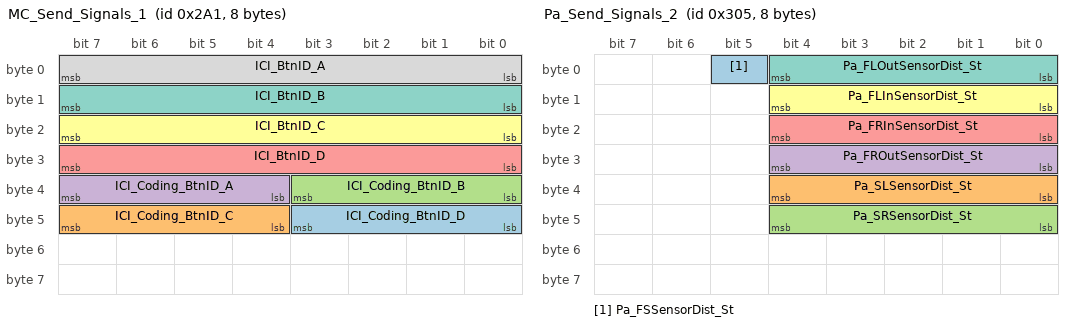
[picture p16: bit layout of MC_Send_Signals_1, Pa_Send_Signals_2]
BO_ 673 MC_Send_Signals_1: 8 IPC
 SG_ ICI_Coding_BtnID_D : 43|4@0+ (1,0) [0|0] "SED"  MFD
 SG_ ICI_Coding_BtnID_C : 47|4@0+ (1,0) [0|0] "SED"  MFD
 SG_ ICI_Coding_BtnID_B : 35|4@0+ (1,0) [0|0] "SED"  MFD
 SG_ ICI_Coding_BtnID_A : 39|4@0+ (1,0) [0|0] "SED"  MFD
 SG_ ICI_BtnID_D : 31|8@0+ (1,0) [0|255] "unitless"  MFD
 SG_ ICI_BtnID_C : 23|8@0+ (1,0) [0|255] "unitless"  MFD
 SG_ ICI_BtnID_B : 15|8@0+ (1,0) [0|255] "unitless"  MFD
 SG_ ICI_BtnID_A : 7|8@0+ (1,0) [0|255] "unitless"  MFD

BO_ 483 Dsp_Request_Signals_9: 8 MFD
 SG_ Dsp_PACCamSelect_Rq : 11|4@0+ (1,0) [0|0] ""  IPC
 SG_ Dsp_PACDistanceBars_Rq : 13|2@0+ (1,0) [0|0] ""  IPC
 SG_ Dsp_PACGuidelines_Rq : 2|3@0+ (1,0) [0|0] ""  IPC
 SG_ Dsp_PACTowBarZoom_Rq : 15|2@0+ (1,0) [0|0] ""  IPC
 SG_ Dsp_PACSystemAct_Rq : 7|2@0+ (1,0) [0|0] ""  IPC

BO_ 777 TRM_Send_Signals_1: 8 IPC
 SG_ TrailerConnection_St : 7|2@0+ (1,0) [0|0] ""  MFD

BO_ 773 Pa_Send_Signals_2: 8 IPC
 SG_ Pa_FSSensorDist_St : 5|1@0+ (1,0) [0|0] ""  MFD
 SG_ Pa_SLSensorDist_St : 36|5@0+ (1,0) [0|31] ""  MFD
 SG_ Pa_SRSensorDist_St : 44|5@0+ (1,0) [0|31] ""  MFD
 SG_ Pa_FROutSensorDist_St : 28|5@0+ (1,0) [0|31] ""  MFD
 SG_ Pa_FRInSensorDist_St : 20|5@0+ (1,0) [0|31] ""  MFD
 SG_ Pa_FLInSensorDist_St : 12|5@0+ (1,0) [0|31] ""  MFD
 SG_ Pa_FLOutSensorDist_St : 4|5@0+ (1,0) [0|31] ""  MFD

BO_ 769 Pa_Send_Signals_1: 8 IPC
 SG_ Pa_SensorAct_St : 7|5@0+ (1,0) [0|0] "SED"  MFD

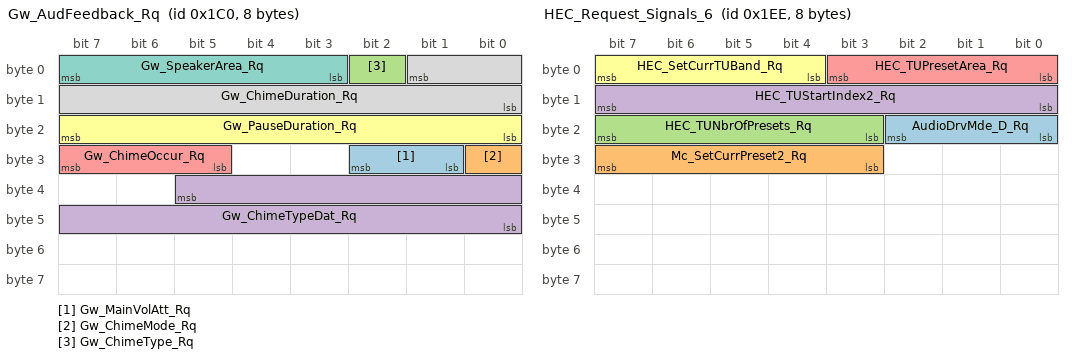
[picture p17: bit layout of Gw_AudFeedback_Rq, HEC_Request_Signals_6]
BO_ 448 Gw_AudFeedback_Rq: 8 IPC
 SG_ Gw_MainVolAtt_Rq : 26|2@0+ (1,0) [0|0] ""  AHU,DSP
 SG_ Gw_ChimeMode_Rq : 24|1@0+ (1,0) [0|0] ""  AHU,DSP
 SG_ Gw_ChimeType_Rq : 2|1@0+ (1,0) [0|0] ""  AHU,DSP
 SG_ Gw_ChimeTypeDat_Rq : 37|14@0+ (1,0) [0|16383] ""  AHU,DSP
 SG_ Gw_ChimeOccur_Rq : 31|3@0+ (1,0) [0|0] ""  DSP,AHU
 SG_ Gw_PauseDuration_Rq : 23|8@0+ (10,0) [0|2500] "ms"  AHU
 SG_ Gw_SpeakerArea_Rq : 7|5@0+ (1,0) [0|0] ""  AHU,DSP
 SG_ Gw_ChimeDuration_Rq : 1|10@0+ (10,0) [0|10000] "ms"  AHU

BO_ 1957 TesterPhysicalReqFCDIM: 8 IPC
 SG_ TesterPhysicalReqFCDIM : 7|64@0+ (1,0) [0|1.84467440737096E+019] "unitless"  MFD

BO_ 1965 TesterPhysicalResFCDIM: 8 MFD
 SG_ TesterPhysicalResFCDIM : 7|64@0+ (1,0) [0|1.84467440737096E+019] "unitless"  IPC

BO_ 511 Dsp_Request_Signals_8: 8 MFD
 SG_ Dsp_TUNbrOfPresets_Rq : 23|5@0+ (1,0) [0|30] ""  AHU
 SG_ Dsp_TUStartIndex2_Rq : 15|8@0+ (1,0) [0|255] ""  AHU
 SG_ Dsp_TUPresetArea_Rq : 3|4@0+ (1,0) [0|0] ""  AHU
 SG_ Dsp_SetCurrTUBand_Rq : 7|4@0+ (1,0) [0|0] ""  AHU
 SG_ Dsp_SetCurrTUPreset_Rq : 31|5@0+ (1,0) [0|0] "SED"  AHU

BO_ 771 PAC_Send_Signals: 8 IPC
 SG_ TrlrLampCnnct_B_Actl : 32|1@0+ (1,0) [0|0] "SED" Vector__XXX
 SG_ ApaMde_D_Stat : 55|3@0+ (1,0) [0|0] "SED" Vector__XXX
 SG_ ApaMde_D_Avail : 45|4@0+ (1,0) [0|0] "SED" Vector__XXX
 SG_ ApaActvSd_D_Actl : 41|2@0+ (1,0) [0|0] "SED" Vector__XXX
 SG_ RearDiffLckLamp_D_Rq : 39|2@0+ (1,0) [0|0] "SED" Vector__XXX
 SG_ CamraFrntStat_D_Stat : 37|2@0+ (1,0) [0|0] "SED" Vector__XXX
 SG_ AwdRnge_D_Actl : 35|3@0+ (1,0) [0|0] "SED" Vector__XXX
 SG_ AwdOffRoadMode_D_Stats : 47|2@0+ (1,0) [0|0] "SED" Vector__XXX
 SG_ CamPDCGuidStat : 31|2@0+ (1,0) [0|0] "SED"  MFD
 SG_ PAC_CamLensObs_St : 5|4@0+ (1,0) [0|0] ""  MFD
 SG_ PAC_CamSysFail_St : 10|3@0+ (1,0) [0|0] ""  MFD
 SG_ PAC_TowBarZoom_St : 15|2@0+ (1,0) [0|0] ""  MFD
 SG_ PAC_Guidelines_St : 13|3@0+ (1,0) [0|0] ""  MFD
 SG_ PAC_DistanceBars_St : 1|2@0+ (1,0) [0|0] ""  MFD
 SG_ PAC_Activation_St : 23|3@0+ (1,0) [0|0] ""  MFD
 SG_ CamraOvrlTow_D_Actl : 25|2@0+ (1,0) [0|0] "SE"  MFD
 SG_ CamraOvrlStat_D_Actl : 27|2@0+ (1,0) [0|0] "SED"  MFD
 SG_ CamZoomActiveState : 29|2@0+ (1,0) [0|0] "SED"  MFD
 SG_ CamraZoomMan_D_Actl : 18|3@0+ (1,0) [0|0] "SED"  MFD
 SG_ CamraOvrlDyn_D_Actl : 20|2@0+ (1,0) [0|0] "SED"  MFD

BO_ 494 HEC_Request_Signals_6: 8 IPC
 SG_ AudioDrvMde_D_Rq : 18|3@0+ (1,0) [0|7] "SED"  AHU
 SG_ Mc_SetCurrPreset2_Rq : 31|5@0+ (1,0) [0|30] "unitless"  AHU
 SG_ HEC_TUNbrOfPresets_Rq : 23|5@0+ (1,0) [0|30] "unitless"  AHU
 SG_ HEC_TUStartIndex2_Rq : 15|8@0+ (1,0) [0|255] "unitless"  AHU
 SG_ HEC_TUPresetArea_Rq : 3|4@0+ (1,0) [0|0] "unitless"  AHU
 SG_ HEC_SetCurrTUBand_Rq : 7|4@0+ (1,0) [0|0] "unitless"  AHU

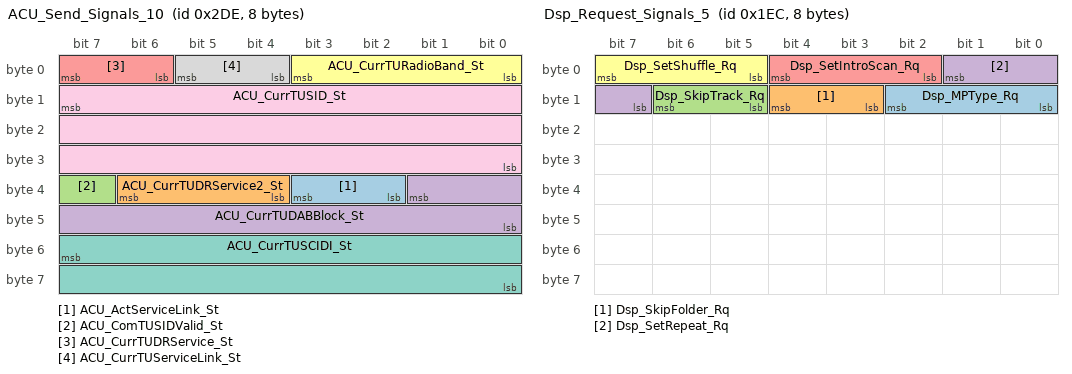
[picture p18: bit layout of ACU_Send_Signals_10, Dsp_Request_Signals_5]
BO_ 734 ACU_Send_Signals_10: 8 AHU
 SG_ ACU_ActServiceLink_St : 35|2@0+ (1,0) [0|0] ""  MFD
 SG_ ACU_CurrTUDRService2_St : 38|3@0+ (1,0) [0|0] ""  MFD
 SG_ ACU_ComTUSIDValid_St : 39|1@0+ (1,0) [0|0] ""  MFD
 SG_ ACU_CurrTUDABBlock_St : 33|10@0+ (1,0) [0|0] "SED"  MFD
 SG_ ACU_CurrTUDRService_St : 7|2@0+ (1,0) [0|0] ""  MFD
 SG_ ACU_CurrTURadioBand_St : 3|4@0+ (1,0) [0|0] ""  MFD
 SG_ ACU_CurrTUSCIDI_St : 55|16@0+ (1,0) [0|65535] ""  MFD
 SG_ ACU_CurrTUServiceLink_St : 5|2@0+ (1,0) [0|0] ""  MFD
 SG_ ACU_CurrTUSID_St : 15|24@0+ (1,0) [0|16777215] ""  MFD

BO_ 492 Dsp_Request_Signals_5: 8 MFD
 SG_ Dsp_MPType_Rq : 10|3@0+ (1,0) [0|0] "" Vector__XXX
 SG_ Dsp_SkipFolder_Rq : 12|2@0+ (1,0) [0|0] "" Vector__XXX
 SG_ Dsp_SkipTrack_Rq : 14|2@0+ (1,0) [0|0] "" Vector__XXX
 SG_ Dsp_SetRepeat_Rq : 1|3@0+ (1,0) [0|0] "" Vector__XXX
 SG_ Dsp_SetIntroScan_Rq : 4|3@0+ (1,0) [0|0] "" Vector__XXX
 SG_ Dsp_SetShuffle_Rq : 7|3@0+ (1,0) [0|0] "" Vector__XXX

BO_ 495 HEC_Request_Signals_5: 8 IPC
 SG_ HEC_BTIncomingCall2_Rq : 3|2@0+ (1,0) [0|0] "" Vector__XXX
 SG_ HEC_BTEndTelService2_Rq : 5|2@0+ (1,0) [0|0] "" Vector__XXX
 SG_ HEC_BTGetActDevActFeat_Rq : 7|2@0+ (1,0) [0|0] "" Vector__XXX

BO_ 701 BTMP_RDISP_WORD_Rx: 8 MFD
 SG_ BTMP_RDISP_WORD_Rx : 7|64@0+ (1,0) [0|1.84467440737096E+019] "unitless" Vector__XXX

BO_ 696 NAV_RDISP_WORD_Rx: 8 MFD
 SG_ NAV_RDISP_WORD_Rx : 7|64@0+ (1,0) [0|1.84467440737096E+019] "unitless" Vector__XXX

BO_ 509 Dsp_Request_Signals_6: 8 MFD
 SG_ Dsp_DB1SetTrkItemIndex_Rq : 55|16@0+ (1,0) [0|65535] "" Vector__XXX
 SG_ Dsp_DB1SetTrkSetConf_Rq : 38|5@0+ (1,0) [0|0] "" Vector__XXX
 SG_ Dsp_DB1SetTrkSetFilt3_Rq : 33|10@0+ (1,0) [0|1023] "" Vector__XXX
 SG_ Dsp_DB1SetTrkSetFilt2_Rq : 23|16@0+ (1,0) [0|65535] "" Vector__XXX
 SG_ Dsp_DB1SetTrkSetFilt1_Rq : 7|16@0+ (1,0) [0|65535] "" Vector__XXX

BO_ 742 ACU_SendSignals_9: 8 AHU
 SG_ ACU_ActiveTrackNum1_St : 7|32@0+ (1,0) [0|4294967295] "unitless"  CPM,IPC,MFD

BO_ 72 HEC_OMMInfo: 8 IPC
 SG_ PowerMode_UB : 53|1@0+ (1,0) [0|0] ""  AHU,DSP,MFD,CPM
 SG_ CarMode : 51|4@0+ (1,0) [0|0] ""  AHU,DSP,CPM,MFD
 SG_ PowerModeQF : 55|2@0+ (1,0) [0|0] ""  AHU,DSP,MFD,CPM
 SG_ PowerMode : 36|5@0+ (1,0) [0|0] ""  AHU,DSP,MFD,CPM

BO_ 466 Dsp_Request_Signals: 8 MFD
 SG_ Dsp_BTAud_SetOpMode_Rq : 15|3@0+ (1,0) [0|0] "" Vector__XXX
 SG_ Dsp_iPod_SetOpMode_Rq : 4|3@0+ (1,0) [0|0] "" Vector__XXX
 SG_ Dsp_USB_SetOpMode_Rq : 7|3@0+ (1,0) [0|0] "" Vector__XXX

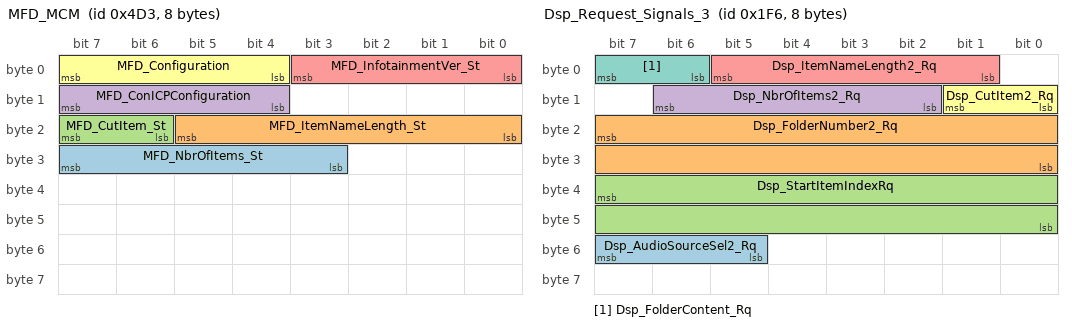
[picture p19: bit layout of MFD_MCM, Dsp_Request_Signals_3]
BO_ 1235 MFD_MCM: 8 MFD
 SG_ MFD_NbrOfItems_St : 31|5@0+ (1,0) [0|31] "" Vector__XXX
 SG_ MFD_ItemNameLength_St : 21|6@0+ (1,0) [0|63] "" Vector__XXX
 SG_ MFD_CutItem_St : 23|2@0+ (1,0) [0|0] "" Vector__XXX
 SG_ MFD_ConICPConfiguration : 15|4@0+ (1,0) [0|0] ""  AHU
 SG_ MFD_InfotainmentVer_St : 3|4@0+ (1,0) [0|0] ""  AHU
 SG_ MFD_Configuration : 7|4@0+ (1,0) [0|0] "" Vector__XXX

BO_ 502 Dsp_Request_Signals_3: 8 MFD
 SG_ Dsp_AudioSourceSel2_Rq : 55|3@0+ (1,0) [0|0] ""  AHU
 SG_ Dsp_FolderNumber2_Rq : 23|16@0+ (1,0) [0|65535] ""  AHU
 SG_ Dsp_StartItemIndexRq : 39|16@0+ (1,0) [0|65535] ""  AHU
 SG_ Dsp_NbrOfItems2_Rq : 14|5@0+ (1,0) [0|20] ""  AHU
 SG_ Dsp_ItemNameLength2_Rq : 5|5@0+ (1,0) [0|20] ""  AHU
 SG_ Dsp_CutItem2_Rq : 9|2@0+ (1,0) [0|0] ""  AHU
 SG_ Dsp_FolderContent_Rq : 7|2@0+ (1,0) [0|0] ""  AHU

CM_ BO_ 859 "Application should not write to the message/signals faster than 60 ms";
CM_ SG_ 859 Voice_Blower_Limit "Object: VoiceBlowerLimit_Rq";
CM_ SG_ 859 Driver_Set_Temp "Msg.#19, Climate Control Grammer v7.xls
Driver or Driver/Passenger Set Temp";
CM_ SG_ 858 Left_Front_Temp_Setpt "Off Value shall never be set

Setpoint_C Range 0.5 (0x01) - 40.0 (0x50)

Setpoint_F Range  40.5 (0x51) - 90.0 (0xB4)

Detents Range 1 (0xB5) - 31 (0xD4)
";
CM_ SG_ 1068 BattTracWarnLamp_B_Rq "Request from the Traction (HV) Battery system to illuminate the Hazard Lamp (red triangle tellltale).

GSDB ID: 1652";
CM_ SG_ 1068 BattTracSrvcRqd_B_Rq "Request from the Traction (HV) Battery system to illuminate the Powertrain Malfunction Lamp (wrench tellltale).

GSDB ID: 1653";
CM_ SG_ 1068 BattTracSoc_Pc_Dsply "Object Remote Alerts.CustomerStateOfCharge_St";
CM_ SG_ 1068 HtrnWarnLamp_B_Dsply "Request from the hybrid transmission system to illuminate the Hazard Lamp (red triangle tellltale).

GSDB ID: 1924";
CM_ SG_ 1068 HtrnSrvcRqd_B_Dsply "Request from the hybrid transmission system to illuminate the Powertrain Malfunction Lamp (wrench tellltale).

GSDB ID: 1923";
CM_ SG_ 1068 HtrnOvrTeLamp_B_Dsply "Request to illuminate the powersplit transaxle over-temperature telltale.

GSDB ID: 1926";
CM_ SG_ 1068 PwPckTqRdy_B_Dsply "Request from the hybrid transmission system to illuminate the Ready Lamp (green car tellltale). Used primarily on HEV, BEV, and other vehicles with electrified powertrains.

GSDB ID: 1925";
CM_ SG_ 1068 Shed_T_Eng_Off_B "Object:PowerManagement._Battery_Mgmt_2.Shed_T_Eng_Off_B";
CM_ SG_ 1068 Shed_Level_Req "Object:PowerManagement._Battery_Mgmt_2 .Shed_Level_Req";
CM_ SG_ 1068 Shed_Drain_Eng_Off_B "Object:PowerManagement._Battery_Mgmt_2 .Shed_Drain_Eng_Off_B";
CM_ SG_ 1068 Batt_Lo_SoC_B "Object:PowerManagement._Battery_Mgmt_2 ";
CM_ SG_ 1068 Batt_Crit_SoC_B "Object:PowerManagement._Battery_Mgmt_2 ";
CM_ SG_ 1068 CcStat_D_Actl "ABSGenSigTimeoutTime=1000";
CM_ SG_ 757 ACU_AutoStoreResult_St "Object Tuner. RadioSeekModeResult";
CM_ SG_ 757 ACU_DirectTune_St "Object.Tuner.DirectTune";
CM_ SG_ 757 ACU_RadioSeekMode2_St "Object Tuner.RadioSeekMode2";
CM_ SG_ 757 ACU_CurrTUBand_St "Object.Tuner.CurrentTUBand";
CM_ SG_ 553 Disp_LangSel_St "Object.VehicleSettings.Disp_LangSel.St.Language";
CM_ SG_ 553 Diagnostic_Operation_Rq "Object:BezelDiagnostics.MFD_Bezel_Diagnostic.St";
CM_ SG_ 553 Bezel_Diag_Module_Rq "Object:BezelDiagnostics.MFD_Bezel_Diagnostic.St";
CM_ SG_ 553 Audio_Demo_CMND "Object. AudioSettings.Audio Demo_CMND";
CM_ SG_ 553 Surround_Sound_Upmix "Object.AudioSettings.Surround_Sound_Upmix

";
CM_ SG_ 553 Bezel_Diag_State_Rq "Object:BezelDiagnostics.MFD_Bezel_Diagnostic.Rq";
CM_ SG_ 553 SurndSndUpmix2_D_Rq "Object:Surround_Sound_Upmix2_Rq";
CM_ SG_ 257 MFD_SetTagMode "Object.AMFMSlave.SetTagMode.Rq.Mode";
CM_ SG_ 257 MFD_SetRBDSMode "Object.AmFmSlave.SetRBDSMode.Rq.Request";
CM_ SG_ 257 MFD_SetHDModeRq "Object.AMFMSlave.SetHDMode.Rq.Request";
CM_ SG_ 257 MFD_GetTagInfo "Object.AMFMSlave.GetTagInfo.Rq.Info";
CM_ SG_ 546 Alert_Chan "Object.AlertMethod. SYNC_Alerts
";
CM_ SG_ 546 Audible_Beep "Object.AlertMethod. SYNC_Alerts";
CM_ SG_ 546 SYNC_New_Attn_Event "Object.AlertMethod. SYNC_Alerts";
CM_ SG_ 546 SYNC_Attn_Info_Audio "Object.AlertMethod. SYNC_Alerts";
CM_ SG_ 546 Prompt_Directionality "Object.AlertMethod. SYNC_Alerts

";
CM_ BO_ 549 "Method IPC _Infotainment";
CM_ SG_ 549 IPC_MyKeyVolLimit_St "Object.MyKey.MyKeyVolumeLimit_St.Mode";
CM_ SG_ 549 BeltminderAudioMute "Object.MyKey.BeltMinderAudioMute.St";
CM_ SG_ 549 IPC_Attn_Info_Audio "Object.AlertMethod.Attn_Info_Audio ";
CM_ SG_ 549 Power_Up_Chime_Modules "Object.AlertMethod.IPC _Infotainment";
CM_ SG_ 549 Chime_Source "Object.AlertMethod.IPC_infotainment";
CM_ SG_ 544 Chime_Occurence "Object.AlertMethod. IPC_Chime";
CM_ SG_ 544 Off_Time_Btwn_Chime "Object.AlertMethod.IPC_Chime
0x0 Inactive
0x1 Continuously (repeat continuously) 
0x2 5 msec
0x3 10 msec
0x4 15 msec
0x5 20 msec
0x6 40 msec
0x7 60 msec (increment is 20 msec steps until 800 msec)
cont....Refer SPSS for rest of the encodings.
";
CM_ SG_ 544 Chime_Time_Criticality "Object.AlertMethod. IPC_Chime";
CM_ SG_ 544 Chime_Directionality "Object.AlertMethod. IPC_Chime";
CM_ SG_ 544 Chime_Vol_Level "Object.AlertMethod. IPC_Chime
0x0 Inactive (no change to stored chime volume - 100% of stored chime volume)
0x1 99% (of stored chime volume)
....
0x63 1% (of stored chime volume)
0x64 Reserved";
CM_ SG_ 544 Chime "Object.AlertMethod. IPC_Chime";
CM_ SG_ 545 AudioOccMde_D_Stat "Object: Occupancy_Mode.St";
CM_ SG_ 545 DSP_MyKeyVolLimitUp_St "Method MykeyvolumeIsLimited";
CM_ SG_ 545 DSP_MyKeyVolLim_St "Method MykeyvolumeIsLimited";
CM_ SG_ 545 DSP_BeltminderAudio_St "Object.MyKey.BeltminderAudioIsMuted";
CM_ SG_ 545 DSP_Bezel_Diag_St "Object: Bezel Diagnostics. DSP_Bezel_Diag.St";
CM_ SG_ 545 DSP_Sur_Sound_st "Method DSP_Sur_Sound_Upmix";
CM_ SG_ 545 DSP_Audio_Volume_Up_St "Object.VolumeControl.DSP_Audio_Vol_updated
";
CM_ SG_ 545 DSP_Audio_Vol_Level_St "Object.VolumeControl.DSP_Audio_Vol_Level.St

0x0 No Volume
0x1 Vol_Step1
0x2 Vol_Step2
0x3 Vol_Step3
Cont.
0x1E Vol_Step30";
CM_ SG_ 545 SurndSndUpmix2_D_Stat "Object:Surround_Sound_Upmix2_St";
CM_ SG_ 552 DSP_Midrange_St "Object Audio.Bass

Level -7..0..7";
CM_ SG_ 552 DSP_VoiceFBVolume_Up "Object AudioControl.DSP_VR_Vol_updated";
CM_ SG_ 552 DSP_VoiceFBVolume_St "Object.VolumeControl.DSP_VR_Vol_Level.St 
0x0 No Volume
0x1 Vol_Step1
0x2 Vol_Step2
0x3 Vol_Step3
Cont.
0x1E Vol_Step30";
CM_ SG_ 552 DSP_Treble_St "Object Audio.Treble

Level -7..0..7";
CM_ SG_ 552 DSP_TAVolume_Up "Object Audio.DSP_TA_Vol_Updated
Indicate user value recalls if the value is set to lower/upper border ";
CM_ SG_ 552 DSP_TAVolume_St "Object.VolumeControl.DSP_TA_Vol_Level.St

0x0 No Volume
0x1 Vol_Step1
0x2 Vol_Step2
0x3 Vol_Step3
Cont.
0x1E Vol_Step30";
CM_ SG_ 552 DSP_PhoneVolume_Up "Object.VolumeControl.DSP_Phone_Vol_Updated
";
CM_ SG_ 552 DSP_PhoneVolume_St "Object.VolumeControl.DSP_Phone_Vol_Level.St

0x0 No Volume
0x1 Vol_Step1
0x2 Vol_Step2
0x3 Vol_Step3
Cont.
0x1E Vol_Step30";
CM_ SG_ 552 DSP_NavCmdVolume_Up "Object Audio.NavCmdVolume_UP. DSP_Prompt_Vol_Updated
";
CM_ SG_ 552 DSP_NavCmdVolume_St "Object Audio.NavCmdVolume. DSP_Prompt_Vol_Level.St

0x0 No Volume
0x1 Vol_Step1
0x2 Vol_Step2
0x3 Vol_Step3
Cont.
0x1E Vol_Step30";
CM_ SG_ 552 DSP_Fader_St "Object Audio.Fader

Level -7..0..7";
CM_ SG_ 552 DSP_DSPProgram_St "Object Audio.DSPProgram
";
CM_ SG_ 552 DSP_DSP_St "Object Audio.DSP

";
CM_ SG_ 552 DSP_Bass_St "Object Audio.Bass

Level -7..0..7";
CM_ SG_ 552 DSP_Balance_St "Object Audio.Balance

Level -7..0..7";
CM_ SG_ 552 DSP_AVC_St "Object Audio.AVC
Off, Level 1 .. Level 7

Object.AudioSettings.DSP_Speed_Comp_Vol.St 
";
CM_ SG_ 552 DSP_Shaker_St "Method DSP_Shaker.St";
CM_ SG_ 552 Audio_Demo_Status "Object.AudioSettings.Audio_Demo_Status";
CM_ SG_ 548 DSP_ChimeChanState_St "Object BodyInterface.StdChimeIF.ChimeChannelState.St";
CM_ SG_ 548 DSP_Chime2_Not_Recognized "Object.ChimeAudioSource.DSP_Chime_Not_Recognized ";
CM_ SG_ 548 DSP_Chime_Not_Recognized "Object.ChimeAudioSource.DSP_Chime_Not_Recognized ";
CM_ SG_ 548 DSP_Alert_Channel3 "Object.AlertMethod.DSP_AMP_Alert

";
CM_ SG_ 548 DSP_Alert_Channel2 "Object.AlertMethod.DSP_AMP_Alert

";
CM_ SG_ 548 DSP_Alert_Channel1 "Object.AlertMethod.DSP_AMP_Alert

";
CM_ SG_ 548 DSP_Chimes_Supported "Object.AlertMethod.DSP_AMP_Alert

";
CM_ SG_ 1000 AHU_Bezel_Diag_St "Object:BezelDiagnostics.AHU_Bezel_Diag.St";
CM_ SG_ 1000 MyKeyVolumeLimitMode "Method MykeyvolumeIsLimited: Mode";
CM_ SG_ 1000 MyKeyVolumeLimitUp "Method MykeyvolumeIsLimited:VolumeUpdate";
CM_ SG_ 1000 ACM_BeltminderAudioSt "Method: BeltminderAudioIsMuted";
CM_ SG_ 1000 AHU_Shaker_St "Object:AudioSettings.AHU_Shaker ";
CM_ SG_ 405 LBC1_StartItemInd "Object. ListBrowser.ItemInf.Rq.StartItemInd
0x0000:Inactive
0x0001:1
0xFFFE:65634
0xFFFF:Reserved";
CM_ SG_ 405 LBC1_SetListServ "Object. ListBrowser.ItemInf.Rq.SetListServ
0x00:Inactive
0x01:ServerID_1
0xFF:ALL";
CM_ SG_ 405 LBC1_Opcode "Object. ListBrowser.ItemInf.Rq.Opcode";
CM_ SG_ 405 LBC1_NbrOfItems "Object. ListBrowser.ItemInf.Rq.NbrOfItems
0x00:Inactive
0x01:1Item
0x3F:63Items";
CM_ SG_ 405 LBC1_ItemIndex "Object. ListBrowser.ItemInf.Rq.ItemIndex
0x0000:BrowseActiveListID
0x0001:EntryIndex_1
0xFFFF:ParentOfActiveListID";
CM_ SG_ 405 LBC1_ActiveListID "Object. ListBrowser.ItemInf.Rq.ActiveListID
0x0000:Root
0xFFFF:Reserved";
CM_ SG_ 550 Band9 "Object:AudioSettings.AHU_Audio_Visualizer_Data";
CM_ SG_ 550 Band8 "Object:AudioSettings.AHU_Audio_Visualizer_Data";
CM_ SG_ 550 Band7 "Object:AudioSettings.AHU_Audio_Visualizer_Data";
CM_ SG_ 550 Band6 "Object:AudioSettings.AHU_Audio_Visualizer_Data";
CM_ SG_ 550 Band5 "Object:AudioSettings.AHU_Audio_Visualizer_Data";
CM_ SG_ 550 Band4 "Object:AudioSettings.AHU_Audio_Visualizer_Data";
CM_ SG_ 550 Band3 "Object:AudioSettings.AHU_Audio_Visualizer_Data";
CM_ SG_ 550 Band2 "Object:AudioSettings.AHU_Audio_Visualizer_Data";
CM_ SG_ 550 Band1 "Object:AudioSettings.AHU_Audio_Visualizer_Data";
CM_ SG_ 755 ACU_AudioMixRatio_St "Object AudioSettings.AudioMixingRatio

Ratio 0-20dB";
CM_ SG_ 692 AUDIO_RDISP_WORD_Tx "MM ISO 15765-2 Message Catalogue
Section AUDIO - RDISP";
CM_ SG_ 700 AUDIO_RDISP_WORD_Rx "MM ISO 15765-2 Message Catalogue
Section RDISP - Audio
";
CM_ SG_ 500 Dsp_GetCDTOCDData_Rq "GetCDTOCData";
CM_ SG_ 500 Dsp_AudioSourceSel_Rq "Object Media Player 
{ BTAudio.GetFolderName, 
SDCard.GetFolderName,
USB.GetFolderName,
BTAudio.SetTrack,
SD Card.SetTrack}.AudioSource
USB.SetTrack.AudioSource
Object Single CD.GetFolderName.AudioSource
Object Single CD.SetTrack.AudioSource";
CM_ SG_ 500 Dsp_FolderNumber_Rq "Object Media Player BTAudio.GetFolderName.FolderNumber
Object Media Player USB.GetFolderName.FolderNumber
Object Single CD.GetFolderName.FolderNumber";
CM_ SG_ 500 Dsp_CutItem_Rq "Object Media Player BTAudio.GetFolderName.CutItemName
Object Media Player USB.GetFolderName.CutItemName
Object Single CD.GetFolderName.CutItemName

Note: value table entry for value $2 was truncated from:
OneQuarterFromTheBeginningThreeQuarterFromTheEnd";
CM_ SG_ 500 Dsp_ItemNameLength_Rq "Object Media Player BTAudio.GetFolderName.ItemNameLength
Object Media Player USB.GetFolderName.ItemNameLength
Object Single CD.GetFolderName.ItemNameLength";
CM_ SG_ 500 Dsp_SourceSetTrack_Rq "Object Media Player BTAudio.SetTrack
Object Media Player USB.SetTrack
Object Single CD.SetTrack.AudioSource
";
CM_ SG_ 501 Dsp_FreezeFMSL_Rq "Object Tuner.FreezeFMStationList
Method:FreezeStationList";
CM_ SG_ 501 Dsp_SetCurrFMSLPr_Rq "Object.AMFMSlave.SetCurrentSLStation.Rq.Index
0x01 : Index 1
0x02 : Index 2
0x03 : Index 3
...
...
0xFE : Index 254";
CM_ SG_ 501 Dsp_SetRadSeekMode_Rq "Object Tuner.SetRadioSeekMode";
CM_ SG_ 501 Dsp_SetCurrPreset2_Rq "Object Tuner.SetCurrentPreset2

$1-$1E: Preset 1 to 30
$0: Inactive
";
CM_ SG_ 503 Dsp_AudioSourceSel3_Rq "Objects Media Player  {BTAudio, USB}.GetDetailedMPInfo.AudioSource

Objects Media Player {Single CD, BTAudio, USB}.PlayFirstTrackInFolder.AudioSource";
CM_ SG_ 503 Dsp_PlayFrstTrInFldr_Rq "Object Single CD.PlayFirstTrackInFolder
Object Media Player BTAudio.PlayFirstTrackInFolder.FolderNumber
Object Media Player USB.PlayFirstTrackInFolder.FolderNumber

$FFFF: Inactive";
CM_ SG_ 698 CONMP_RDISP_WORD_Rx "MM ISO 15765-2 Message Catalogue
Section RDISP - CONMP";
CM_ SG_ 702 PHONE_MC_WORD_Rx "MM ISO 15765-2 Message Catalogue
Section MC - PHONE";
CM_ SG_ 699 PHONE_RDSP_WORD_Rx "MM ISO 15765-2 Message Catalogue
Section RDISP - PHONE";
CM_ SG_ 691 PHONE_RDSP_WORD_Tx "MM ISO 15765-2 Message Catalogue
Section PHONE - RDISP";
CM_ SG_ 689 AUDIO_MC_WORD_Tx "MM ISO 15765-2 Message Catalogue
Section Audio - MC";
CM_ SG_ 401 Disp_VehUnitTripCoUsrSel "Obect.VehicleSettings.Disp_Miles_Kilometers.Rq.Mode";
CM_ SG_ 401 Disp_VehUnitTempUsrSel "Obect.VehicleSettings.Disp_Temperature.Rq.Mode";
CM_ SG_ 401 Disp_LangSel_Rq "Object.VehicleSettings.Disp_LangSel.Rq.Language";
CM_ SG_ 400 Mc_PerTUStartIndex2_Rq "Object Personalization. DAB.GetTUPresetInfo.StartIndex2

$1-$FF: Preset 1 to 255";
CM_ SG_ 400 Mc_PerTUPresetArea_Rq "Object Personalization.DAB.GetTUPresetInfo.PresetArea

$5: Get AMAST (MW) Preset Data
$6: Get AM (LW) Preset Data";
CM_ SG_ 400 Mc_PerTUNbrOfPresets_Rq "Object Personalization. DAB.GetTUPresetInfo.NumberOfPresets

$1-$1E: Preset 1 to 30";
CM_ SG_ 400 Mc_SDARS_DirectTune_Rq "Object Tuner.SDARS Tuner.DirectTune
$0: Channel_0
$1: Channel_1
$2: Channel_2
$FE: Channel_254
$FF: Inactive";
CM_ SG_ 400 Mc_SetCurrStatMCCh_Rq "Object Tuner.SetCurrentStation.MCChannel";
CM_ SG_ 400 Mc_SetCurrentStatFreq_Rq "Object Tuner.SetCurrentStat.Request.Frequency

AM: Freq = 153+ Offset kHz.
Offset 0..1557

FM: Freq = 76+ Offset*0.05 MHz. Offset 0..640
Selected tuned band determine frequency (kHz or MHz).";
CM_ SG_ 400 Mc_SetCurrentStatOp_Rq "Object Tuner.SetCurrentStat.Request.Operation";
CM_ SG_ 756 Off_Time_Btwn_Chime2 "Object.AlertMethod.IPC_Chime
0x0 Inactive
0x1 Continuously (repeat continuously) 
0x2 5 msec
0x3 10 msec
0x4 15 msec
0x5 20 msec
0x6 40 msec
0x7 60 msec (increment is 20 msec steps until 800 msec)
cont....Refer SPSS for rest of encodings";
CM_ SG_ 756 Chime_Vol_Level2 "Object.AlertMethod. IPC_Chime
0x0 Inactive (no change to stored chime volume - 100% of stored chime volume)
0x1 99% (of stored chime volume)
....
0x63 1% (of stored chime volume)
0x64 Reserved";
CM_ SG_ 756 Chime_Time_Criticality2 "Object.AlertMethod. IPC_Chime";
CM_ SG_ 756 Chime_Occurence2 "Object.AlertMethod. IPC_Chime";
CM_ SG_ 756 Chime_Directionality2 "Object.AlertMethod. IPC_Chime";
CM_ SG_ 756 Chime2 "Object.AlertMethod. IPC_Chime";
CM_ SG_ 477 NAV_SetBass_Rq "Object Audio.SetBass

Level -7..0..7
$F: Inactive";
CM_ SG_ 477 NAV_SetTreble_Rq "Object Audio.SetTreble

Level -7..0..7
$F: Inactive";
CM_ SG_ 477 NAV_SetFader_Rq "Object Audio.SetFader

Level -7..0..7
$F: Inactive";
CM_ SG_ 477 NAV_SetBalance_Rq "Object Audio.SetBalance

Level -7..0..7
$F: Inactive";
CM_ SG_ 477 NAV_SetAVC_Rq "Object Audio.SetAVC
Object. Audio.SetSpeed_Comp_Vol.Rq

$F: Inactive";
CM_ SG_ 477 NAV_SecurityPINUnlock_Rq "Object ACU System Master.SecurityPINUnlock
PIN: from 0000 - 9999
$3FFF: Inactive";
CM_ SG_ 477 NAV_LoadEjectMode_Rq "Object Single CD.LoadEject.Mode";
CM_ SG_ 477 NAV_LoadEjectDisc_Rq "Object Indash CD Changer.LoadEject(Disc Number)
Object Single CD.LoadEject(Action)
";
CM_ SG_ 476 NAV_SetDSPProgram_Rq "Object Audio.SetDSPProgram
";
CM_ SG_ 476 NAV_SkipCatalouge_Rq "Object Single CD.SkipFolder";
CM_ SG_ 476 NAV_SetOperationMode_Rq "Object Rear CD Changer.SetOperationMode
Object Indash CD Changer.SetOperationMode
Object Single CD.SetOperationMode";
CM_ SG_ 476 Nav_SetAudioMixRatio_Rq "Object AudioSettings.SetAudioMixingRatio

Ratio 0-20dB

$1F: inactice";
CM_ SG_ 474 NAV_SetMid_Rq "Object Audio Settings.SetMid

Level -7..0..7
$F: Inactive

Method: SetMidRange";
CM_ SG_ 474 NAV_SetNEWSMode_Rq "Object Tuner.SetNEWSMode";
CM_ SG_ 474 NAV_SetDSP_Rq "Object Audio.SetDSP

Object.AudioSettings.SetOccupancy_Mode.Rq";
CM_ SG_ 474 NAV_SetCurrentStatFreq_Rq "Object Tuner.SetCurrentStat.Request.Frequency

AM: Freq = 153+ Offset kHz.
Offset 0..1557

FM: Freq = 76+ Offset*0.05 MHz. Offset 0..640
Selected tuned band determine frequency (kHz or MHz).";
CM_ SG_ 474 NAV_SetCurrentPICode_Rq "Object Tuner.SetCurrentStat.Request.PI Code

16 bit hex coded PI Code

";
CM_ SG_ 474 NAV_ARRquesterPriority_Rq "Object Audio Management AudioClient.AudioRequest.Requester Priority";
CM_ SG_ 474 NAV_ARRequesterSystem_Rq "Object Audio Management AudioClient.AudioRequest.Requester System";
CM_ SG_ 474 NAV_AROperationType_Rq "Object Audio Management Audio Client.AudioRequest.Operation Type";
CM_ SG_ 474 NAV_ARAudioSource_Rq "Object Audio Management Audio Client.AudioRequest.Requested Audio Source

$8 interpreted as APIM or Navigation";
CM_ SG_ 474 Nav_SetCurrStatMCCh_Rq "Object Tuner.SetCurrentStation.MCChannel";
CM_ SG_ 474 NAV_SetCurrentStatOp_Rq "Object Tuner.SetCurrentStat.Request.Operation";
CM_ SG_ 473 NAV_SetTUServiceLink_Rq "Object Tuner.NAV_SetTUServiceLink_Rq";
CM_ SG_ 473 NAV_StorePreset_Rq "Object Tuner.StorePreset

NOTE: If used on CANalyzer/CANoe for the older DENSO HighNav System, wrong values will be shown!";
CM_ SG_ 473 NAV_SetTAMode_Rq "Object Tuner.SetTAMode";
CM_ SG_ 473 NAV_SetReg_Rq "Object Tuner.SetREG";
CM_ SG_ 473 NAV_SetAFMode_Rq "Object Tuner.SetAFMode";
CM_ SG_ 473 NAV_SelectPTYCodesSet_Rq "Object Tuner.SelectPTYCodes

Set PTY code with the follow bit encoding";
CM_ SG_ 473 NAV_SelectPTYCodes_Rq "Object Tuner.SelectPTYCodes

28 bit bitfield where each PTY code can be set separately:
Bit 0:  0:  PTY Code 2 not selected; 1:  PTY Code 2 selected
...
Bit 27: PTY Code 29 not selected; 1:  PTY Code 29 selected";
CM_ SG_ 473 NAV_CDSetShuffle_Rq "Object Single CD.SetShuffle";
CM_ SG_ 473 NAV_CDSetRepeat_Rq "Object Single CD.SetRepeat";
CM_ SG_ 473 NAV_CDSetIntroScan_Rq "Object Single CD.SetIntroScan";
CM_ SG_ 479 DISP_SetVol_Source_Rq "Object.VolumeControl.MFD_SetVol_Source.Rq";
CM_ SG_ 479 DISP_SetVol_Level_Rq "Object.VolumeControl.MFD_SetVol_Level.Rq 

0x0 Inactive/NoChange
0x1 No Volume
0x2 Vol_Step1
0x3 Vol_Step2
0x4 Vol_Step3
Cont.
0x1F Vol_Step30";
CM_ SG_ 479 DISP_SetVolume_Rq "Method: MFD_SetVolume
0x0 -30 Steps
0x1 -29 Steps
0x2 -28 Steps
...contd
0x1C - 2 Steps
0x1D - 1 Steps
0x1E NotPressed/Inactive
0x1F +1 Steps
0x20 +2 Steps
0x21 +3 Steps
...contd
0x3C +30";
CM_ SG_ 726 ACU_AFJump_St "Object Tuner.AFJump.St";
CM_ SG_ 726 ACU_NEWSMode_St "Object Tuner.NEWSMode";
CM_ SG_ 726 ACU_SelectedPTYCodes_St "Object Tuner.SelectedPTYCodes

Bit 0: 0: invalid, 1: valid
Bit 1: 0: PTY code 2 not selected; 1: PTY code 2 selected
...
Bit 28: 0: PTY code 29 not selected; 1: PTY code 29 selected";
CM_ SG_ 726 ACU_TAMode_St "Object Tuner.TAMode";
CM_ SG_ 727 ACU_LoadEjectDisc_St "Object Indash CD Changer.LoadEject(Disc Number)";
CM_ SG_ 727 ACU_LoadEjectMode_St "Object Indash CD Changer.LoadEject(Action)";
CM_ SG_ 2015 TesterFunctionalReq " ";
CM_ SG_ 1839 TesterPhysicalResACM " ";
CM_ SG_ 1831 TesterPhysicalReqACM " ";
CM_ SG_ 1241 EATC_TempRangeOffset "Object EATC Repeater.EATC_MCM_TempRangeOffset

Range of EATC Temperature. Highest EATC Temperature  is calculated by equation: TempHighValue = TempRangeStart + TempRangeOffset";
CM_ SG_ 1241 EATC_TempRangeStart "Object EATC Repeater.EATC_MCM_TempRangeStart

TempRangeStart Value. 

Status signal as feedback for the Driver Temp Setting. Temperature range is LO (15.5 °C) to HI (28.5 °C).  Value $00 means inactive.";
CM_ SG_ 1241 EATC_BlowerSpeedMAX "Object EATC Repeater.EATC_MCM_BlowerSpeedMAX

EATC_BlowerMAX describes the maximum blower speed that will be indicated to the user on the NAV display. Possible range is 0 -14.";
CM_ SG_ 1241 EATC_BlowerSpeedMIN "Object EATC Repeater.EATC_MCM_BlowerSpeedMIN

EATC_BlowerMIN describes the minimum Blower speed that will be indicated to the user on the NAV display. Possible range is 0 -14.";
CM_ SG_ 1239 HEC_NbrOfItems_St "Object HEC Configuration Control._NbrOfItems";
CM_ SG_ 1239 HEC_ItemNameLength_St "Object HEC Configuration Control.ItemNameLength";
CM_ SG_ 1239 HEC_CutItem_St "Object HEC Configuration Control.CutItem";
CM_ SG_ 1239 HEC_VehicleConfig "This signal indicates the car configuration LHD/RHD";
CM_ SG_ 1232 AHU_AutoConfigOcc_Shaker "Object: AudioSettings.AHU_AutoConFigOcc_Shaker";
CM_ SG_ 1232 AHU_AutoConfigOcc_Rear "Object:AudioSettings.AHU_AutoConfigOcc_Rear";
CM_ SG_ 1232 AHU_AutoConfigOcc_Front "Object: AudioSettings. AHU_AutoConfigOcc_Front";
CM_ SG_ 1232 AHU_AutoConfigOcc_Driver "Object:AudioSettings.AHU_AutoConfigOcc_Driver";
CM_ SG_ 1232 AHU_AutoConfigOcc_Convert "AHU_AutoConfigOcc_Convertible ";
CM_ SG_ 1232 AHU_AutoConfigOcc_Allseats "Object: AudioSettings. AHU_AutoConfigOcc_AllSeats";
CM_ SG_ 1232 ACU_Configuration "Object Configuration Management.ACU_Configuration";
CM_ SG_ 1232 ACU_DigitalRadio_St "Object Configuration Management.ACU_DigitalRadio";
CM_ SG_ 1232 ACU_MediaPlayer_St "Object Configuration Management.ACU_MediaPlayer

$1: MusicCassettePlayer is handled as Medialess in MFD setup";
CM_ SG_ 1232 AHU_EnsembleName_St "Object Configuration Management.EnsembleName_St";
CM_ SG_ 1075 PJB_LockStatusValid "Validity of signal PJB_LockStatus
Provided by CD34x

Object BodySystemInterface.LockStatus.Validation";
CM_ SG_ 1075 PJB_LockStatus "Object: Power Management Interface. Lock_Status
Object BodySystemInterface.LockStatus

Information from the PJB if the car is locked.

";
CM_ SG_ 1075 PJB_ReverseGearSwitch "The reverse gear is hardwired to the PJB or transmitted by the TCM via gateway to the PJB and the PJB sends the PJB_ReverseGearSwitch signal out.";
CM_ SG_ 1075 PJB_DriverDoorStatus "Information from the PJB if the driver door is open or closed.
Provided by CD34x";
CM_ SG_ 1075 PJB_PassengerDoorStatus "Information from the PJB if the passenger door is open or closed. Provided by CD34x";
CM_ SG_ 1075 PJB_LeftRearDoorStatus "not supported in CD34x";
CM_ SG_ 1075 PJB_RightRearDoorStatus "not supported in CD34x";
CM_ SG_ 1075 PJB_BootLidStatus "not supported in CD34x";
CM_ SG_ 739 HMI_HMIMode_St "Object ACU System Master.HMIMode
OR
Object NAV System Master.HMIMode

Refer Method HMIAudioMode in the SPSS";
CM_ SG_ 736 TextMessage_Rsp "Object.BTPhoneServer.TextMessage.Rsp.ResponseCode";
CM_ SG_ 736 VRM_CallDuration_St "Object Bluetooth Phone.CallDuration";
CM_ SG_ 736 BTInCallOptions_St "Object.BTPhoneServer.BTInCallOptions.Rsp.Result";
CM_ SG_ 732 ACU_FunctionStatus_St "Object Indash CD Changer.FunctionStatus
Object Single CD.FunctionStatus";
CM_ SG_ 732 ACU_CurrFMSLPreset_St "Object Tuner.CurrentFMSLPreset

Not applicable for LLA, HLA
CurrentSLIndex";
CM_ SG_ 732 ACU_CurrPreset2_St "Object Tuner.CurrentPreset2";
CM_ SG_ 732 ACU_StorePreset_St "Object Tuner.StorePreset";
CM_ SG_ 731 ACU_NumberofTracks_St "Object Indash CD Changer.NumberofTracks
Object Single CD.NumberofTracks
Mp3 CD: Tracks in folder";
CM_ SG_ 731 ACU_TotalPlayTime_St "Object Indash CD Player.TotalPlayTime
Object Single CD.TotalPlayTime
Corresponds to logical signal Total Playtime. Signal must only be updated every 250ms when in Fast For or Re.";
CM_ SG_ 731 ACU_TrackPlaytime_St "Object Indash CD Playerr.TrackPlayTime
Object Single CD.TrackPlayTime
Corresponds to logical signal Track Playtime. Signal must only be updated every 250ms when in Fast For or Re.";
CM_ SG_ 730 ACU_ActiveDiscNumber_St "Object Indash CD Changer.ActiveDiscNumber";
CM_ SG_ 730 ACU_CDIntroScan_St "Object Single CD.IntroScan";
CM_ SG_ 730 ACU_CDRepeat_St "Object Single CD.Repeat";
CM_ SG_ 730 ACU_CDShuffle_St "Object Single CD.CDShuffle";
CM_ SG_ 730 ACU_Coding_St "Object Indash CD Changer.Coding
Object Single CD.Coding";
CM_ SG_ 730 ACU_DiscCoding_St "Object Single CD.DiscCoding
Object DVD.DiscCoding";
CM_ SG_ 730 ACU_MagazineSlots_St "Object CD Changer.Magazineslots

Bit 0:  0: invalid, 1: valid
Bit 1:  0 = No disc in slot 1; 
      1 = Disc in slot 1
                 …
Bit 6:  0 = No disc in slot 6; 
      1 = Disc in slot 6";
CM_ SG_ 730 ACU_OperationMode_St "Object Indash CD Changer.OperationMode
Object Single CD.OperationMode";
CM_ SG_ 729 ACU_AVC_St "Object Audio.AVC
Off, Level 1 .. Level 7

Method: AHU_Speed_Comp_Vol";
CM_ SG_ 729 ACU_Balance_St "Object Audio.Balance

Level -7..0..7
Method: AHU_Balance";
CM_ SG_ 729 ACU_Bass_St "Object Audio.Bass

Level -7..0..7
Method: AHU_Bass";
CM_ SG_ 729 ACU_DSP_St "Object. Audio.DSP
Object: AudioSettings.AHU_Occupancy_Mode.St";
CM_ SG_ 729 ACU_DSPProgram_St "Object Audio.DSPProgram
";
CM_ SG_ 729 ACU_Fader_St "Object Audio.Fader

Level -7..0..7
Method: AHU_Fade";
CM_ SG_ 729 ACU_NavCmdVolume_St "Object Audio.NavCmdVolume. AHU_Prompt_Vol_Level.St()

Refer method table in SPSS for details
0x0 No Volume
0x1 Vol_Step1
0x2 Vol_Step2
0x3 Vol_Step3
Cont.
0x1E Vol_Step30";
CM_ SG_ 729 ACU_NavCmdVolume_Up "Object Audio.NavCmdVolume_UP. AHU_Prompt_Vol_Updated. ";
CM_ SG_ 729 ACU_PhoneVolume_St "Object Audio.PhoneVolume
AHU_Phone_Vol_Level.St
0x0 No Volume
0x1 Vol_Step1
0x2 Vol_Step2
0x3 Vol_Step3
Cont.
0x1E Vol_Step30";
CM_ SG_ 729 ACU_PhoneVolume_Up "Object Audio.PhoneVolume_UP

Object.VolumeControl.AHU_Phone_Vol_Updated";
CM_ SG_ 729 ACU_Reg_St "Object Tuner.REG";
CM_ SG_ 729 ACU_TAVolume_St "Object Audio.TAVolume
Method AHU_TA_Vol_Level.St 

Refer method table in SPSS for details
0x0 No Volume
0x1 Vol_Step1
0x2 Vol_Step2
0x3 Vol_Step3
Cont.
0x1E Vol_Step30";
CM_ SG_ 729 ACU_TAVolume_Up "Object Audio.TAVolume_UP
Indicate user value recalls if the value is set to lower/upper border 
Method AHU_TA_Vol_Updated ";
CM_ SG_ 729 ACU_Treble_St "Object Audio.Treble

Level -7..0..7
Method: AHU_Treble";
CM_ SG_ 729 ACU_VoiceFBVolume_St "Object Audio.VoiceFBVolume
Method AHU_VR_Vol_Level_St()

Refer method table in SPSS for details
0x0 No Volume
0x1 Vol_Step1
0x2 Vol_Step2
0x3 Vol_Step3
Cont.
0x1E Vol_Step30";
CM_ SG_ 729 ACU_VoiceFBVolume_Up "Object Audio.VoiceFBVolume_UP
Object.AHU_VR_Vol_Updated
Indicate user value recalls if the value is set to lower/upper border ";
CM_ SG_ 728 ACU_CDError_St "Object Audio Management Audio Client.AudioError.CDError";
CM_ SG_ 728 ACU_CurrentStatFlags_St "Object Tuner.CurrentStatFlags

Bit 0: Validation
Bit 1: EON not sup; 1: EON sup
Bit 2: TP not sup; 1: TP sup
Bit 3: 0: Mono; 1: Stereo
Bit 4: 0: RDS not sup; 1: RDS sup";
CM_ SG_ 728 ACU_Mid_St "Object Audio.Mid

Level -7..0..7


Method: AHU_Midrange";
CM_ SG_ 728 ACU_RadioSeekMode_St "Object Tuner.RadioSeekMode";
CM_ SG_ 728 ACU_Volume_St "Object Audio.Volume

Level 0..30
Method AHU_Audio_Vol_Level

Refer method table in SPSS for details
0x0 No Volume
0x1 Vol_Step1
0x2 Vol_Step2
0x3 Vol_Step3
Cont.
0x1E Vol_Step30";
CM_ SG_ 728 ACU_Volume_Up "Object Audio.Volume_UP
Indicate user value recalls if the value is set to lower/upper border 
Method AHU_Audio_Vol_Updated";
CM_ SG_ 725 ACU_CompLogic_St "Object.CDCompLogic_St ";
CM_ SG_ 725 ACU_RadioError_St "Object Audio Management Audio Client.AudioError.RadioError";
CM_ SG_ 725 ACU_HardwareError_St "Object Audio Management Audio Client.AudioError.HardwareError";
CM_ SG_ 725 ACU_CurrentPTYCode_St "Object Tuner.CurrentPTYCode

$0: Invalid
$1: PTY 1 (News)
..
$1F: PTY 31 (Alarm)";
CM_ SG_ 725 ACU_CurrentPICode_St "Object Tuner.CurrentPICode";
CM_ SG_ 725 ACU_CurrentFreq_St "Object Tuner.CurrentFreq

AM: Freq = 153+ Offset kHz.
Offset 0..1557 

FM: Freq = 76+ Offset*0.05 MHz. Offset 0..640
Selected tuned band determine frequency (kHz or MHz).";
CM_ SG_ 725 ACU_AFMode_St "Object Tuner.AFMode";
CM_ SG_ 661 EATC_DISPupdate_Defrost "Object EATC Repeater.EATC_DISPupdate_Defrost";
CM_ SG_ 661 EATC_DISPupdate_MAXAC "Object EATC Repeater.EATC_DISPupdate_MAXAC

Indicates a change in signal:
- EATC_MAXACMode";
CM_ SG_ 661 EATC_MAXACMode "Object EATC Repeater.MAXACMode";
CM_ SG_ 661 EATC_DISPupdate_AutoMode "Object EATC Repeater.EATC_DISPupdate_AutoMode

Indicates a change in signal:
- EATC_AutoMode";
CM_ SG_ 661 EATC_DISPupdate_ACMode "Object EATC Repeater.EATC_DISPupdate_ACMode

Indicates a change in signal:
- EATC_ECOMode";
CM_ SG_ 661 EATC_DISPupdate_AirMode "Object EATC Repeater.EATC_DISPupdate_AirMode

Indicates a change in Air Mode signal, which can be:
- EATC_DefrostMode
- EATC_RecircMode
- EATC_AirToScreenMode
- EATC_AirToPanelMode
- EATC_AirToFloorMode";
CM_ SG_ 661 EATC_DISPupdate_BlowerSpd "Object EATC Repeater.EATC_DISPupdate_BlowerSpd

Indicates a change in signal:
- EATC_BlowerSpeed";
CM_ SG_ 661 EATC_DISPupdate_TempCoDr "Object EATC Repeater.EATC_DISPupdate_TempCoDriverSet

Indicates a change in signal:
- EATC_TempCoDriverSet";
CM_ SG_ 661 EATC_DISPupdate_TempDr "Object EATC Repeater.EATC_DISPupdate_TempDriverSet

Indicates a change in signal:
- EATC_TempDriverSet";
CM_ SG_ 661 EATC_DISPupdate_SysMode "Object EATC Repeater.EATC_DISPupdate_SysMode

Indicates a change in signal:
- EATC_SystemMode";
CM_ SG_ 661 EATC_BlowerSpeed "Object EATC Repeater.EATC_BlowerSpeed

Statussignal for Blower Speed setting of EATC. The information of the blower speed stages that will be indicated in the display is included in the EATC configuration message 4D9.";
CM_ SG_ 661 EATC_HeatingStatus "Object EATC Repeater.EATC_HeatingStatus

Internal status of the EATC. 
For HCSV Feature the EATC tells the PJB that the activation of the HeaterCore ShutOff Valve is requested if EATC_HeatingStatus = $1 (max. cooling)";
CM_ SG_ 661 EATC_TempCoDriverSet "Object EATC Repeater.EATC_TempCoDriverSet

Status signal as feedback for the Co-Driver Temp Setting. Temperature range is LO (15.5 °C) to HI (28.5 °C).  Value $00 means inactive.";
CM_ SG_ 661 EATC_TempDriverSet "Object EATC Repeater.EATC_TempDriverSet

Status signal as feedback for the Driver Temp Setting. Temperature range is LO (15.5 °C) to HI (28.5 °C).  Value $00 means inactive.";
CM_ SG_ 661 EATC_SystemMode "Object EATC Repeater.EATC_SystemMode";
CM_ SG_ 661 EATC_ECOMode "Object EATC Repeater.EATC_ECOMode";
CM_ SG_ 661 EATC_AirToScreenMode "Object EATC Repeater.EATC_AirToScreenMode";
CM_ SG_ 661 EATC_AirToPanelMode "Object EATC Repeater.EATC_AirToPanelMode";
CM_ SG_ 661 EATC_AirToFloorMode "Object EATC Repeater.EATC_AirToFloorMode";
CM_ SG_ 661 EATC_MonoMode "Object EATC Repeater.EATC_MonoMode";
CM_ SG_ 661 EATC_AutoMode "Object EATC Repeater.EATC_AutoMode";
CM_ SG_ 661 EATC_DefrostMode "Object EATC Repeater.EATC_DefrostMode";
CM_ SG_ 661 EATC_RecircMode "Object EATC Repeater.EATC_RecircMode";
CM_ SG_ 661 EATC_DISPupdate_MonoMode "Object EATC Repeater.EATC_DISPupdate_MonoMode

Indicates a change in signal:
- EATC_MonoMode";
CM_ SG_ 649 Ill_BEZ_HLA "Object Illumination.IlluminationICP3Status";
CM_ SG_ 649 Ill_BEZ_NAV "Object Illumination.IlluminationICP2Status";
CM_ SG_ 649 Ill_BEZ_ACU "Object Illumination.IlluminationICP1Status";
CM_ SG_ 498 HEC_ARRquesterPriority_Rq "Object Audio Management Audio Client.AudioRequest.Requester Priority";
CM_ SG_ 498 HEC_AROperationType_Rq "Object Audio Management Audio Client.AudioRequest.Operation Type";
CM_ SG_ 498 HEC_ARRequesterSystem_Rq "Object Audio Management Audio Client.AudioRequest.Requester System";
CM_ SG_ 498 HEC_ARAudioSource_Rq "Object Audio Management Audio Client.AudioRequest.Requested Audio Source";
CM_ SG_ 490 HMI_SkipTrack_Rq "Object Rear CD Changer.SkipTrack
Object Indash CD Changer.SkipTrack
Object Single CD.SkipTrack
Object.SDARSClient.SkipTrack";
CM_ SG_ 489 ACU_CurrentPSName_St "Object Tuner.CurrentPSName
Object Tuner.DAB.CurrentServiceName

Text with maximum 8 characters";
CM_ SG_ 488 HMI_BTGetActDevActFeat_Rq "Object BT Device
BTGetActiveDevicesActiveFeatures";
CM_ SG_ 488 HMI_BTDebondDevice_Rq "Object BT Device.BTDebondDevice";
CM_ SG_ 488 HMI_BTSetActFeatGroup_Rq "Object BT Device.BTSetActiveFeature.Group";
CM_ SG_ 488 HMI_BTSetActFeatDevInd_Rq "Object BT Device.BTSetActiveFeature.BTDeviceIndex";
CM_ SG_ 488 HMI_PhMicrophoneMute_Rq "Object Bluetooth Phone.PhMicrophoneMute";
CM_ SG_ 488 HMI_SubscribeStInfo_Rq "Object Bluetooth Phone.SubscribeStatusInfo";
CM_ SG_ 488 HMI_SetBlutoothMode_Rq "Object Bluetooth Phone.SetBluetoothMode";
CM_ SG_ 488 HMI_SetIncCallOption_Rq "Object Bluetooth Phone.SetIncCallOption";
CM_ SG_ 488 HMI_PhonesSts_Rq "Object Bluetooth Phone.PhonesSts
";
CM_ SG_ 488 HMI_BTIncomingCall_Rq "Object Bluetooth Phone.BTIncomingCall";
CM_ SG_ 488 HMI_BTEndTelService_Rq "Object Bluetooth Phone.BTEndTelService";
CM_ SG_ 488 HMI_BTSendDTMFTone_Rq "Object Bluetooth Phone.BTSendDTMFTone";
CM_ SG_ 486 ACU_ARAudioSource_Rsp "Object Audio Management AudioClient.AudioRequest.Requested Audio Source";
CM_ SG_ 486 ACU_AROperationType_Rsp "Object Audio Management AudioClient.AudioRequest.Operation Type";
CM_ SG_ 486 ACU_ARRequesterSystem_Rsp "Object Audio Management AudioClient.AudioRequest.Requester System";
CM_ SG_ 486 ACU_ARResponse_Rsp "Object Audio Management AudioClient.AudioRequest.Response";
CM_ SG_ 486 ACU_ARRquesterPriority_Rp "AR = Audio Request (this signal belongs to the logical signal AudioRequest.Rsp)
Object = AudioClient
Logical Signal = AudioRequest
Parameter = Requester Priority

Disc shall be used for both CD and MC";
CM_ SG_ 486 ACU_RUAudioSource_St "Object Audio Management Audio Client.ResourceUpdate.Requested Audio Source
";
CM_ SG_ 486 ACU_RURequesterSystem_St "Object Audio Management Audio Client.ResourceUpdate.Requester System";
CM_ SG_ 486 ACU_RUResRequestStatus_St "Object Audio Management Audio Client.ResourceUpdate.Resource Request Status";
CM_ SG_ 486 ACU_RURquesterPriority_St "Object Audio Management Audio Client.ResourceUpdate.Requester Priority";
CM_ SG_ 469 VRM_ARRquesterPriority_Rq "Object Audio Management Audio Client.AudioRequest.Requester Priority";
CM_ SG_ 469 VRM_AROperationType_Rq "Object Audio Management Audio Client.AudioRequest.Operation Type";
CM_ SG_ 469 VRM_ARRequesterSystem_Rq "Object Audio Management Audio Client.AudioRequest.Requester System";
CM_ SG_ 469 VRM_ARAudioSource_Rq "Object Audio Management Audio Client.AudioRequest.Requested Audio Source";
CM_ SG_ 144 SetTimeFormat "Object.BodyInterface.Settings.VehicleTimeFormatUserSelection";
CM_ SG_ 144 SetYear "Object Clock.SetYear

Request from the Audio Control Unit to the Cluster in order to adjust the years, with an offset of 2000.";
CM_ SG_ 144 SetMonth "Object Clock.SetMonth

Request from the Audio Control Unit to the Cluster in order to adjust the months.";
CM_ SG_ 144 SetDay "Object Clock.SetDay

Request from the Audio Control Unit to the Cluster in order to adjust the days.";
CM_ SG_ 144 SetHour "Object Clock.SetHour

Request from the Audio Control Unit to the Cluster in order to adjust the hours.";
CM_ SG_ 144 SetMinute "Object Clock.SetMinute

Request from the Audio Control Unit to the Cluster in order to adjust the minutes.";
CM_ SG_ 144 SetSecond "Object Clock.SetSecond

Request from the Audio Control Unit to the Cluster in order to adjust the seconds.";
CM_ SG_ 144 TimeAdjustRequest "Object Clock.TimeAdjustRequest

Request from the Audio Control Unit to the Cluster in order to adjust the time.";
CM_ SG_ 144 DateAdjustRequest "Object Clock.DateAdjustRequest

Request from the Audio Control Unit to the Cluster in order to adjust the date.";
CM_ SG_ 128 HEC_Second "Object Clock.Second

An 8 bit numeric value in seconds.";
CM_ SG_ 128 HEC_Minute "Object Clock.Minute

An 8 bit numeric value in minutes.";
CM_ SG_ 128 HEC_Hour "Object Clock.Hour

An 8 bit numeric value in hours.";
CM_ SG_ 128 HEC_Day "Object Clock.Day

An 8 bit numeric value in days.";
CM_ SG_ 128 HEC_Month "Object Clock.Month

An 8 bit numeric value in months.";
CM_ SG_ 128 HEC_Year "Object Clock.Year

An 8 bit numeric value in years with an offset of 2000.";
CM_ SG_ 403 Mc_RepeatGuidance_Rq "Object.NavigationRepeater.Guidance_Repeat.Rq.RepeatGuidance";
CM_ SG_ 403 Mc_CancelRoute_Rq "Object.NavigationRepater.CancelRoute.Rq.CancelRoute";
CM_ SG_ 403 Mc_CancelCurrWaypt_Rq "Object.NavigationRepeater.CancelCurrentWayPoint.Rq.Cancelwaypoint";
CM_ SG_ 403 Mc_TextMessage_Rq "Object. BTPhoneClient.TextMessage.Rq";
CM_ SG_ 403 Mc_BTInCallOptions_Rq "Object.BTPhoneClient.BTInCallOptions.Rq.SingleParam";
CM_ SG_ 403 Mc_PhMicrophoneMute_Rq "Object Blueetoth Phone.PhMicrophoneMute";
CM_ SG_ 403 Mc_LangSel_Rq "Object.VehicleSettings.Disp_LangSel.Rq.Language";
CM_ SG_ 547 Audio_Amp_St "Object. Audio_Amp_St";
CM_ SG_ 547 Chime_Alert_Chan2 "Object.AlertMethod. AHU_Alerts";
CM_ SG_ 547 AHU_Chime2_Active "Object. AlertMethod. AHU_Alerts

0x0 Inactive
0x1 No_Chime
0x2 Chime_1
0x3 Chime_2
0x4 Chime_3
cont.
0x3F Chime_62";
CM_ SG_ 547 AHU_Chime2_Not_Recognized "Object.AlertMethod. AHU_Alerts";
CM_ SG_ 547 Chime_Alert_Chan "Object.AlertMethod. AHU_Alerts";
CM_ SG_ 547 AHU_Alert_Channel1 "Object.AlertMethod.AHU_Alerts

";
CM_ SG_ 547 AHU_Chime_Supported "Object.AlertMethod. AHU_Alerts";
CM_ SG_ 547 AHU_Chime_Active "Object. AlertMethod. AHU_Alerts

0x0 Inactive
0x1 No_Chime
0x2 Chime_1
0x3 Chime_2
0x4 Chime_3
cont.
0x3F Chime_62";
CM_ SG_ 547 AHU_Chime_Not_Recognized "Object.AlertMethod. AHU_Alerts";
CM_ SG_ 765 Mc_VehUnitTripCoUsrSel_St "Object.VehicleSettings.Disp_Miles_Kilometers.Rq";
CM_ SG_ 765 Mc_VehUnitTempUsrSel_St "Object.VehicleSettings.Disp_Temperature.Rq";
CM_ SG_ 765 Mc_VehDayNightUsrSel_St "Object.BodyInterface.Settings.VehicleDayNightUserSelection
Object.BodyInterface.Status.AMDayNightSensitivity

In a SYNC G2 environment, every value update is published with a delay of 5000ms.";
CM_ SG_ 765 Mc_VehTimeFormatUsrSel_St "Object.BodyInterface.Settings.VehicleTimeFormatUserSelection";
CM_ SG_ 765 Mc_VehThemeUsrSel_St "Object.BodyInterface.Settings.VehicleThemeUserSelection";
CM_ SG_ 765 Mc_VehLangUsrSel_St "Object.BodyInterface.Settings.VehicleLanguageUserSelection
Object Vehicle Settings.Disp_LangSel
";
CM_ SG_ 648 DimmingMode_St "Object Illumination.DimmingMode

This signal is the feedback of the dimming master BCM to the MFD/SYNC about which dimming mode has been stored, based on the HMI_DimmingModeStatus input from the HMI.";
CM_ SG_ 648 Ill_Disp_HLA "Object Illumination.IlluminationDisp3Status";
CM_ SG_ 648 Ill_Disp_NAV "Object Illumination.IlluminationDisp2Status";
CM_ SG_ 648 Ill_Disp_ACU "Object Illumination.IlluminationDisp1Status";
CM_ SG_ 648 IntIllumDimOvrrd "Object Illumination.IntIllumDimOvrideCoding";
CM_ SG_ 774 Pa_RSensorDist_St "Object.BodyInterface.PDC.RSensorDist

Indicates if data provided by other signals in this frame is valid.";
CM_ SG_ 774 Pa_RROutSensorDist_St "Object.BodyInterface.PDC.SensorDistRear.OuterRight

Indicates the distance to an obstacle at the rear of the car.

Distance outer right sensor

";
CM_ SG_ 774 Pa_RRInSensorDist_St "Object.BodyInterface.PDC.SensorDistRear.InnerRight

Indicates the distance to an obstacle at the rear of the car.

Distance inner right sensor

";
CM_ SG_ 774 Pa_RLInSensorDist_St "Object.BodyInterface.PDC.SensorDistRear.InnerLeft

Indicates the distance to an obstacle at the rear of the car.

Distance inner left sensor

";
CM_ SG_ 774 Pa_RLOutSensorDist_St "Object.BodyInterface.PDC.SensorDistRear.OuterLeft

Indicates the distance to an obstacle at the rear of the car.

Distance outer left sensor

";
CM_ SG_ 775 SAPP_Status_St "Object.BodyInterface.SAPP.SAPPStatus";
CM_ BO_ 48 "Message shall be published periodically at 100ms. Corresponding gateway strategy to be considered.";
CM_ SG_ 48 WheelSpeedReL "Physical Range 0 - 32765 0.01  0 rad/s    
$7FFE = Unknown    
$7FFF = Fault ";
CM_ SG_ 48 WheelSpeedReR "Physical Range 0 - 32765 0.01  0 rad/s    
$7FFE = Unknown    
$7FFF = Fault ";
CM_ BO_ 673 "SteeringWheelControl_RQ";
CM_ SG_ 673 ICI_Coding_BtnID_D "Object InputControlInterface ICI ButtonCoding_D
(Parameter2)";
CM_ SG_ 673 ICI_Coding_BtnID_C "Object InputControlInterface ICI ButtonCoding_C
(Parameter2)";
CM_ SG_ 673 ICI_Coding_BtnID_B "Object InputControlInterface ICI ButtonCoding_B
(Parameter2)";
CM_ SG_ 673 ICI_Coding_BtnID_A "Object InputControlInterface ICI ButtonCoding_A
(Parameter2)";
CM_ SG_ 673 ICI_BtnID_D "Object InputControlInterface ICI ButtonID_D
(Parameter1)
for detailed Information refer to ICI Reference document";
CM_ SG_ 673 ICI_BtnID_C "Object InputControlInterface ICI ButtonID_C
(Parameter1)
for detailed Information refer to ICI Reference document";
CM_ SG_ 673 ICI_BtnID_B "Object InputControlInterface ICI ButtonID_B
(Parameter1)
for detailed Information refer to ICI Reference document";
CM_ SG_ 673 ICI_BtnID_A "Object InputControlInterface ICI ButtonID_A
(Parameter1)
for detailed Information refer to ICI Reference document";
CM_ SG_ 483 Dsp_PACCamSelect_Rq "Object.BodyInterface.RVC.SelectCam
";
CM_ SG_ 483 Dsp_PACDistanceBars_Rq "Object.BodyInterface.RVC.SetDistanceBars
";
CM_ SG_ 483 Dsp_PACGuidelines_Rq "Object.BodyInterface.RVC.SetGuidelines
";
CM_ SG_ 483 Dsp_PACTowBarZoom_Rq "Object.BodyInterface.RVC.SetTowBarZoom
";
CM_ SG_ 483 Dsp_PACSystemAct_Rq "Object.BodyInterface.RVC.ActivateCamera
";
CM_ SG_ 777 TrailerConnection_St "Object.BodyInterface.TrailerConnection.TrailerStatus";
CM_ SG_ 773 Pa_FSSensorDist_St "Object.BodyInterface.PDC.FSSensorDist

Indicates if data provided by other signals in this frame is valid.";
CM_ SG_ 773 Pa_SLSensorDist_St "Object.BodyInterface.PDC.SensorDistSide.Left

Indicates the distance to an obstacle in front of the car.

Distance left side sensor

";
CM_ SG_ 773 Pa_SRSensorDist_St "Object.BodyInterface.PDC.SensorDistSide.Right

Indicates the distance to an obstacle in front of the car.

Distance right side sensor

";
CM_ SG_ 773 Pa_FROutSensorDist_St "Object.BodyInterface.PDC.SensorDistFront.OuterRight

Indicates the distance to an obstacle in front of the car.

Distance outer right sensor

";
CM_ SG_ 773 Pa_FRInSensorDist_St "Object.BodyInterface.PDC.SensorDistFront.InnerRight

Indicates the distance to an obstacle in front of the car.

Distance inner right sensor

";
CM_ SG_ 773 Pa_FLInSensorDist_St "Object.BodyInterface.PDC.SensorDistFront.InnerLeft

Indicates the distance to an obstacle in front of the car.

Distance inner left sensor

";
CM_ SG_ 773 Pa_FLOutSensorDist_St "Object.BodyInterface.PDC.SensorDistFront.OuterLeft

Indicates the distance to an obstacle in front of the car.

Distance outer left sensor

";
CM_ SG_ 769 Pa_SensorAct_St "Object.BodyInterface.PDC.ActiveSensors.{Validation, RearSensors, FrontSensors, TrailerConnected, Failure}

Bit meanings: (0=Inactive, 1=Active)

0: Validation
1: Rear Park Sensor
2: Front Park Sensors
3: TrailerConnected
4: Failure";
CM_ SG_ 448 Gw_MainVolAtt_Rq "Object.BodyInterface.StdChimeIF.AttenuateMainVol.Attenuation
";
CM_ SG_ 448 Gw_ChimeMode_Rq "Object.BodyInterface.StdChimeIF.Chime.Mode
";
CM_ SG_ 448 Gw_ChimeType_Rq "Object.BodyInterface.StdChimeIF.Chime.Type
";
CM_ SG_ 448 Gw_ChimeTypeDat_Rq "Object.BodyInterface.StdChimeIF.Chime.TypeData.Rq

ChimeType==Sine: 
Range: 0x01-0x3FF (1Hz - 16383Hz)

ChimeType==Sample: 
Range: 0x01-0x40  (Sample 1 - Sample 63)
Range: 0x41-0x3FFF (Reserved)";
CM_ SG_ 448 Gw_ChimeOccur_Rq "Object.BodyInterface.StdChimeIF.Chime.Occurence
";
CM_ SG_ 448 Gw_PauseDuration_Rq "Object.BodyInterface.StdChimeIF.Chime.PauseDur

0x00: NoPause
Range: 0x01 - 0xFA (10 - 2500 ms)
Range: 0xFB - 0xFF (Reserved)";
CM_ SG_ 448 Gw_SpeakerArea_Rq "Object BodyInterface.StdChimeIF.Chime.Speaker

Value 0: inactive, 1: active
Bit 0:  FrontLeft
Bit 1:  FrontRight
Bit 2:  RearLeftSpeaker
Bit 3:  RearRightSpeaker
Bit 4:  AllSpeaker";
CM_ SG_ 448 Gw_ChimeDuration_Rq "Object.BodyInterface.StdChimeIF.Chime.Duration

0x00: NoDuration
Range: 0x01 - 0x3E8 (10 - 10000 ms)
Range: 0x3E9 - 0x3FE Reserved
0x3FF: Infinite";
CM_ SG_ 1957 TesterPhysicalReqFCDIM " ";
CM_ SG_ 1965 TesterPhysicalResFCDIM " ";
CM_ SG_ 511 Dsp_TUNbrOfPresets_Rq "Object Tuner.GetTUPresetInfo.NumberOfPresets
Object DAB.GetTUPresetInfo.NumberOfPresets
Object SDARS.GetTUPresetInfo.NumberOfPresets

$1-$1E: Preset 1 to 30";
CM_ SG_ 511 Dsp_TUStartIndex2_Rq "Object Tuner.GetTUPresetInfo.StartIndex2
Object DAB.GetTUPresetInfo.StartIndex2
Object SDARS.GetTUPresetInfo.StartIndex2

$1-$FF: Preset 1 to 255";
CM_ SG_ 511 Dsp_TUPresetArea_Rq "Object Tuner.GetTUPresetInfo.PresetArea
Object DAB.GetTUPresetInfo.PresetArea
Object SDARS.GetTUPresetInfo.PresetArea";
CM_ SG_ 511 Dsp_SetCurrTUBand_Rq "Object Tuner.SetCurrTUBand
Object DAB.SetCurrTUBand
Object SDARS.SetCurrTUBand
";
CM_ SG_ 511 Dsp_SetCurrTUPreset_Rq "Object Tuner.GetTUPresetInfo.SetCurrentTUPreset
Object DAB.GetTUPresetInfo.SetCurrentTUPreset
Object SDARS.GetTUPresetInfo.SetCurrentTUPreset

$1-$1E: Preset 1 to 30";
CM_ SG_ 771 TrlrLampCnnct_B_Actl "Not supported on CD4 M1";
CM_ SG_ 771 ApaMde_D_Stat "Object.FAS Parking Aid.ApaMde_D_Stat.Type";
CM_ SG_ 771 ApaMde_D_Avail "Object.FAS Parking Aid.ApaMde_D_Avail.Type";
CM_ SG_ 771 CamPDCGuidStat "Object:DistanceBarStatus ";
CM_ SG_ 771 PAC_CamLensObs_St "Object BodyInterface.RVC.RVCError.Obscuration
";
CM_ SG_ 771 PAC_CamSysFail_St "Object BodyInterface.RVC.RVCError.Failure
";
CM_ SG_ 771 PAC_TowBarZoom_St "Object BodyInterface.RVC.RVCMode.TowBarZoom
";
CM_ SG_ 771 PAC_Guidelines_St "Object BodyInterface.RVC.RVCMode.Guidelines";
CM_ SG_ 771 PAC_DistanceBars_St "Object BodyInterface.RVC.RVCMode.DistanceBars";
CM_ SG_ 771 PAC_Activation_St "Object PACDisplay
";
CM_ SG_ 771 CamraOvrlTow_D_Actl "Object:CamraOvrlTow_D_Actl";
CM_ SG_ 771 CamraOvrlStat_D_Actl "Object:StaticGuidelineStatus";
CM_ SG_ 771 CamZoomActiveState "Object:RVCServer.AutoZoomStatus ";
CM_ SG_ 771 CamraZoomMan_D_Actl "Object:CamraZoomMan_D_Actl";
CM_ SG_ 771 CamraOvrlDyn_D_Actl "Object:DynamicGuidelineStatus";
CM_ SG_ 494 Mc_SetCurrPreset2_Rq "Object Tuner.SetCurrentPreset2
SetCurrentTUPreset.Rq

$1-$1E: Preset 1 to 30
$0: Inactive
";
CM_ SG_ 494 HEC_TUNbrOfPresets_Rq "Object Tuner.GetTUPresetInfo.NumberOfPresets

$1-$1E: Preset 1 to 30";
CM_ SG_ 494 HEC_TUStartIndex2_Rq "Object Tuner.GetTUPresetInfo.StartIndex2

$1-$FF: Preset 1 to 255";
CM_ SG_ 494 HEC_TUPresetArea_Rq "Object Tuner.GetTUPresetInfo.PresetArea

$5: Get AMAST (MW) Preset Data
$6: Get AM (LW) Preset Data";
CM_ SG_ 494 HEC_SetCurrTUBand_Rq "Object Tuner.SetCurrTUBand
$5: AM (LLN, HLN: MW)
$6: AM AST (LLN, HLN: LW)";
CM_ SG_ 734 ACU_ActServiceLink_St "Object DAB.ActServiceLink";
CM_ SG_ 734 ACU_CurrTUDRService2_St "Object DAB.CurrentDRServiceStatus";
CM_ SG_ 734 ACU_ComTUSIDValid_St "Object DAB.CurrentSID.Availability
";
CM_ SG_ 734 ACU_CurrTUDABBlock_St "Object DAB.CurrentDABBlock
Bitfield:
Bit 0..4: L-Band Canada: Numeric value (NV)(1 .. 23); L-Band Europe: NV (A=1 .. W=23); Band III: NV (A=1 .. W=23); 
Bit 5..8: Band III: NV (not used for L-Band; set value to 0h)
Bit 9: 0: Band III, 1: L-Band
";
CM_ SG_ 734 ACU_CurrTUDRService_St "Object DAB.CurrentDRServiceStatus";
CM_ SG_ 734 ACU_CurrTURadioBand_St "Object DAB.CurrentTUBand

Gen3 Values 
$1: reserved
$2: reserved 
$3: reserved
$4: reserved
$5: reserved
$6: reserved";
CM_ SG_ 734 ACU_CurrTUSCIDI_St "Object DAB.CurrentSCIDI";
CM_ SG_ 734 ACU_CurrTUServiceLink_St "Object DAB.CurrentServiceLink";
CM_ SG_ 734 ACU_CurrTUSID_St "Object DAB.CurrentSID.SID

For Digital Radio: 
Byte 1..2: 16 bit hex coded SID
Byte 3:     8 bit hex coded ECC";
CM_ SG_ 492 Dsp_MPType_Rq "Object Media Player SDCard.MPType
Object Media Player BTAudio.MPType
Object Media Player iPod.MPType
Object Media Player USB.MPType";
CM_ SG_ 492 Dsp_SkipFolder_Rq "Object Media Player SDCard.SkipFolder
Object Media Player BTAudio.SkipFolder
Object Media Player iPod.SkipFolder
Object Media Player USB.SkipFolder";
CM_ SG_ 492 Dsp_SkipTrack_Rq "Object Media Player SDCard.SkipTrack
Object Media Player BTAudio.SkipTrack
Object Media Player iPod.SkipTrack
Object Media Player USB.SkipTrack";
CM_ SG_ 492 Dsp_SetRepeat_Rq "Object Media Player SDCard.SetRepeat
Object Media Player BTAudio.SetRepeat
Object Media Player iPod.SetRepeat
Object Media Player USB.SetRepeat";
CM_ SG_ 492 Dsp_SetIntroScan_Rq "Object Media Player SDCard.SetIntroScan
Object Media Player BTAudio.SetIntroScan
Object Media Player iPod.SetIntroScan
Object Media Player USB.SetIntroScan";
CM_ SG_ 492 Dsp_SetShuffle_Rq "Object Media Player SDCard.SetShuffle
Object Media Player BTAudio.SetShuffle
Object Media Player iPod.SetShuffle
Object Media Player USB.SetShuffle";
CM_ SG_ 495 HEC_BTIncomingCall2_Rq "Object Bluetooth Phone.BTIncomingCall";
CM_ SG_ 495 HEC_BTEndTelService2_Rq "Object Bluetooth Phone.BTEndTelService";
CM_ SG_ 495 HEC_BTGetActDevActFeat_Rq "Object BT Device.BTGetActiveDevicesActiveFeatures";
CM_ SG_ 701 BTMP_RDISP_WORD_Rx "MM ISO 15765-2 Message Catalogue
Section RDISP - BTCON";
CM_ SG_ 696 NAV_RDISP_WORD_Rx "MM ISO 15765-2 Message Catalogue
Section RDISP - NAV";
CM_ SG_ 509 Dsp_DB1SetTrkItemIndex_Rq "Object Media Player iPod.MDBSetTrack.MDBItemIndex
";
CM_ SG_ 509 Dsp_DB1SetTrkSetConf_Rq "Object Media Player iPod.MDBSetTrack.MDBSetFilterConf";
CM_ SG_ 509 Dsp_DB1SetTrkSetFilt3_Rq "Object Media Player iPod.MDBSetTrack.MDBSetFilter3";
CM_ SG_ 509 Dsp_DB1SetTrkSetFilt2_Rq "Object Media Player iPod.MDBSetTrack.MDBSetFilter2";
CM_ SG_ 509 Dsp_DB1SetTrkSetFilt1_Rq "Object Media Player iPod.MDBSetTrack.MDBSetFilter1";
CM_ SG_ 742 ACU_ActiveTrackNum1_St "Object Indash CD Changer.ActiveTrackNum
Object Single CD.ActiveTrackNum1
Object Media Player SD Card.ActiveTrackNum1
";
CM_ SG_ 72 PowerMode_UB "For B2yy this bit is always set to \"1\" to tell display use current PowerMode";
CM_ SG_ 72 CarMode "Sub-system: Power Supply
E/E Function: Car Mode

Sub-system: Passive Restraints
E/E Function: Auto Hazard Lights Crash

Provides Car mode (Crash, Transport, Factory, Normal) to each module)";
CM_ SG_ 72 PowerModeQF "Sub-system: Power Supply
E/E Function: Power Mode
Quality Factor for power mode information.

Object.BodySystemInterface.PowerMode.QF
(Parameter2)";
CM_ SG_ 72 PowerMode "Sub-system: Power Supply
E/E Function: Power Mode 
used for Ignition Key Position information

Object.BodySystemInterface.PowerMode.Value
(Parameter1)";
CM_ SG_ 466 Dsp_BTAud_SetOpMode_Rq "Object Media Player BTAudio.SetOperationMode";
CM_ SG_ 466 Dsp_iPod_SetOpMode_Rq "Object Media player iPod.SetOperationMode";
CM_ SG_ 466 Dsp_USB_SetOpMode_Rq "Object Media player USB.SetOperationMode";
CM_ SG_ 1235 MFD_NbrOfItems_St "Object MFD Configuration Control.NbrOfItems";
CM_ SG_ 1235 MFD_ItemNameLength_St "Object MFD Configuration Control.ItemNameLength";
CM_ SG_ 1235 MFD_CutItem_St "Object MFD Configuration Control.CutItem";
CM_ SG_ 1235 MFD_ConICPConfiguration "Object Configuration Management.MFD_ConICPConfiguration";
CM_ SG_ 1235 MFD_InfotainmentVer_St "Object Configuration Management.MFD_InfotainmetVer";
CM_ SG_ 1235 MFD_Configuration "Object Configuration Management.MFD_Configuration";
CM_ SG_ 502 Dsp_AudioSourceSel2_Rq "Object Media Player 
BT Audio.GetMPInfo.AudioSource
SDCard.GetMPInfo.AudioSource
USB.GetMPInfo.AudioSource
SingleCD.GetMPInfo.AudioSource";
CM_ SG_ 502 Dsp_FolderNumber2_Rq "Object Media Player 
BT Audio.GetMPInfo.FolderNumber
USB.GetMPInfo.FolderNumber
SDCard.GetMPInfo.FolderNumber
SingleCD.GetMPInfo.FolderNumber

$FFFF: Inactive";
CM_ SG_ 502 Dsp_StartItemIndexRq "Object Media Player BT SDCard.GetMPInfo.StartItemIndex
USB.GetMPInfo.StartItemIndex
SingleCD.GetMPInfo.StartItemIndex

$FFFF: Inactive";
CM_ SG_ 502 Dsp_NbrOfItems2_Rq "Object Media Player 
BT Audio.GetMPInfo.NbrOfItems
SDCard.GetMPInfo.NbrOfItems
USB.GetMPInfo.NbrOfItems
SingleCD.GetMPInfo.NbrOfItems";
CM_ SG_ 502 Dsp_ItemNameLength2_Rq "Object Media Player 
BT Audio.GetMPInfo.ItemNameLength
SDCard.GetMPInfo.ItemNameLength
USB.GetMPInfo.ItemNameLength
SingleCD.GetMPInfo.ItemNameLength";
CM_ SG_ 502 Dsp_CutItem2_Rq "Object Media Player 
BT Audio.GetMPInfo.CutItemName
SDCard.GetMPInfo.CutItemName
USB.GetMPInfo.CutItemName
SingleCD.GetMPInfo.CutItemName

Note: value table entry for value $2 was truncated from:
OneQuarterFromTheBeginningThreeQuarterFromTheEnd";
CM_ SG_ 502 Dsp_FolderContent_Rq "Object Media Player 
BT Audio.GetMPInfo.FolderContent
SDCard.GetMPInfo.FolderContent
USB.GetMPInfo.FolderContent
SingleCD.GetMPinfo.Foldercontent

Note: Value table entries were truncated from:
$0: ..FolderNumber
$1: ..OfParameterFolderNumber";
BA_DEF_ BO_  "FrameType" INT 0 2;
BA_DEF_ BO_  "TpMessage" ENUM  "No","Yes";
BA_DEF_ BO_  "GenMsgIlSupport" ENUM  "No","Yes";
BA_DEF_ SG_  "GenSigTimeoutTime__delete" INT 0 100000;
BA_DEF_ SG_  "GenSigTimeoutTime_CPM" INT 0 100000;
BA_DEF_ SG_  "GenSigTimeoutTime_DSP" INT 0 100000;
BA_DEF_ SG_  "GenSigTimeoutTime_AHU" INT 0 100000;
BA_DEF_ SG_  "GenSigTimeoutTime_IPC" INT 0 100000;
BA_DEF_ SG_  "GenSigTimeoutTime_MFD" INT 0 100000;
BA_DEF_ BO_  "TpTxIndex" INT 0 10000;
BA_DEF_ BO_  "GenMsgILSupport" ENUM  "No","Yes";
BA_DEF_ BO_  "FrameGatewayNetwork_OLD" ENUM  "None","HS1_CAN","HS2_CAN","HS3_CAN","MS1_CAN";
BA_DEF_ BO_  "FrameGatewayMS1" HEX 0 1407;
BA_DEF_ BO_  "FrameGatewayLC1" HEX 0 1407;
BA_DEF_ BO_  "FrameGatewayHS2" HEX 0 1407;
BA_DEF_ BO_  "FrameGatewayHS1" HEX 0 1407;
BA_DEF_ BO_  "FrameGatewayId" HEX 0 1407;
BA_DEF_ BO_  "NetworkInitialization" ENUM  "No","Yes";
BA_DEF_ BO_  "GenMsgStartDelayTime" INT 0 100000;
BA_DEF_ BO_  "GenMsgNrOfRepetition" INT 0 100;
BA_DEF_ BO_  "GenMsgDelayTime" INT 0 1000;
BA_DEF_ BO_  "GenMsgCycleTimeFast" INT 0 100000;
BA_DEF_ BO_  "GenMsgCycleTime" INT 0 10000;
BA_DEF_ BO_  "GenMsgSendType" ENUM  "FixedPeriodic","Event","EnabledPeriodic","NotUsed","NotUsed","EventPeriodic","NotUsed","NotUsed","NoMsgSendType";
BA_DEF_ BO_  "FrameGateway_nonCGEA" HEX 0 1407;
BA_DEF_ SG_  "WakeupSignal" ENUM  "No","Yes";
BA_DEF_ SG_  "GenSigMissingSourceValue" INT 0 1000000000;
BA_DEF_ SG_  "GenSigSendType" ENUM  "Cyclic","OnWrite","OnWriteWithRepetition","OnChange","OnChangeWithRepetition","IfActive","IfActiveWithRepetition","NoSigSendType";
BA_DEF_ SG_  "EventRateOfChange" INT 10 10000;
BA_DEF_ SG_  "HS3_Category" ENUM  "Standardized","Restricted","Proposed","Prohibited","Duplicated";
BA_DEF_ SG_  "FISI_Comment_Sig" STRING ;
BA_DEF_ SG_  "GenSigEnvVarType" ENUM  "int","float","undef";
BA_DEF_ SG_  "LegacySignalName" STRING ;
BA_DEF_ SG_  "GenSigStartMeaning" STRING ;
BA_DEF_ SG_  "GenSigMissingSourceMeaning" STRING ;
BA_DEF_ SG_  "FMC_SIG_Issue" STRING ;
BA_DEF_ SG_  "FMC_SIG_SSPEC" STRING ;
BA_DEF_ SG_  "VNASignalName" STRING ;
BA_DEF_ SG_  "InvalidHex" STRING ;
BA_DEF_ SG_  "NWM-WakeupAllowed" ENUM  "No","Yes";
BA_DEF_ SG_  "GenSigStartValue" FLOAT 0 100000000000;
BA_DEF_ SG_  "GenSigInactiveValue" INT 0 100000;
BA_DEF_ BO_  "FISI_Comment_Msg" STRING ;
BA_DEF_ BO_  "FMC_MSG_Issue" STRING ;
BA_DEF_ BO_  "CGEA_Message" ENUM  "No","Yes";
BA_DEF_ BO_  "NmAsrMessage" ENUM  "No","Yes";
BA_DEF_ BO_  "VNATransmissionType" ENUM  "periodic","sporadic","immediate";
BA_DEF_ BO_  "NetworkInitializationCommand" ENUM  "No","Yes";
BA_DEF_ BO_  "DiagState" ENUM  "No","Yes";
BA_DEF_ BO_  "DiagRequest" ENUM  "No","Yes";
BA_DEF_ BO_  "DiagResponse" ENUM  "No","Yes";
BA_DEF_ BO_  "NmMessage" ENUM  "No","Yes","vector_leerstring";
BA_DEF_ BO_  "SystemMessageLongSymbol" STRING ;
BA_DEF_DEF_  "FrameType" 2;
BA_DEF_DEF_  "TpMessage" "No";
BA_DEF_DEF_  "GenMsgIlSupport" "Yes";
BA_DEF_DEF_  "GenSigTimeoutTime__delete" 5000;
BA_DEF_DEF_  "GenSigTimeoutTime_CPM" 5000;
BA_DEF_DEF_  "GenSigTimeoutTime_DSP" 5000;
BA_DEF_DEF_  "GenSigTimeoutTime_AHU" 5000;
BA_DEF_DEF_  "GenSigTimeoutTime_IPC" 5000;
BA_DEF_DEF_  "GenSigTimeoutTime_MFD" 5000;
BA_DEF_DEF_  "TpTxIndex" 0;
BA_DEF_DEF_  "GenMsgILSupport" "Yes";
BA_DEF_DEF_  "FrameGatewayNetwork_OLD" "None";
BA_DEF_DEF_  "FrameGatewayMS1" 0;
BA_DEF_DEF_  "FrameGatewayLC1" 0;
BA_DEF_DEF_  "FrameGatewayHS2" 0;
BA_DEF_DEF_  "FrameGatewayHS1" 0;
BA_DEF_DEF_  "FrameGatewayId" 0;
BA_DEF_DEF_  "NetworkInitialization" "No";
BA_DEF_DEF_  "GenMsgStartDelayTime" 0;
BA_DEF_DEF_  "GenMsgNrOfRepetition" 1;
BA_DEF_DEF_  "GenMsgDelayTime" 20;
BA_DEF_DEF_  "GenMsgCycleTimeFast" 0;
BA_DEF_DEF_  "GenMsgCycleTime" 0;
BA_DEF_DEF_  "GenMsgSendType" "NoMsgSendType";
BA_DEF_DEF_  "FrameGateway_nonCGEA" 1407;
BA_DEF_DEF_  "WakeupSignal" "No";
BA_DEF_DEF_  "GenSigMissingSourceValue" 0;
BA_DEF_DEF_  "GenSigSendType" "NoSigSendType";
BA_DEF_DEF_  "EventRateOfChange" 10000;
BA_DEF_DEF_  "HS3_Category" "Standardized";
BA_DEF_DEF_  "FISI_Comment_Sig" "";
BA_DEF_DEF_  "GenSigEnvVarType" "undef";
BA_DEF_DEF_  "LegacySignalName" "";
BA_DEF_DEF_  "GenSigStartMeaning" "Unknown";
BA_DEF_DEF_  "GenSigMissingSourceMeaning" "Unknown";
BA_DEF_DEF_  "FMC_SIG_Issue" "Unknown";
BA_DEF_DEF_  "FMC_SIG_SSPEC" "Unknown";
BA_DEF_DEF_  "VNASignalName" "";
BA_DEF_DEF_  "InvalidHex" "";
BA_DEF_DEF_  "NWM-WakeupAllowed" "No";
BA_DEF_DEF_  "GenSigStartValue" 0;
BA_DEF_DEF_  "GenSigInactiveValue" 0;
BA_DEF_DEF_  "FISI_Comment_Msg" "";
BA_DEF_DEF_  "FMC_MSG_Issue" "Unknown";
BA_DEF_DEF_  "CGEA_Message" "No";
BA_DEF_DEF_  "NmAsrMessage" "No";
BA_DEF_DEF_  "VNATransmissionType" "periodic";
BA_DEF_DEF_  "NetworkInitializationCommand" "No";
BA_DEF_DEF_  "DiagState" "No";
BA_DEF_DEF_  "DiagRequest" "No";
BA_DEF_DEF_  "DiagResponse" "No";
BA_DEF_DEF_  "NmMessage" "No";
BA_DEF_DEF_  "SystemMessageLongSymbol" "";
BA_ "VNATransmissionType" BO_ 857 1;
BA_ "FrameGateway_nonCGEA" BO_ 857 857;
BA_ "GenMsgSendType" BO_ 857 5;
BA_ "GenMsgCycleTime" BO_ 857 1000;
BA_ "VNATransmissionType" BO_ 859 1;
BA_ "GenMsgSendType" BO_ 859 5;
BA_ "GenMsgCycleTime" BO_ 859 1000;
BA_ "GenMsgDelayTime" BO_ 859 60;
BA_ "VNATransmissionType" BO_ 858 1;
BA_ "GenMsgSendType" BO_ 858 1;
BA_ "VNATransmissionType" BO_ 293 1;
BA_ "FrameGateway_nonCGEA" BO_ 293 293;
BA_ "GenMsgSendType" BO_ 293 5;
BA_ "GenMsgCycleTime" BO_ 293 1000;
BA_ "VNATransmissionType" BO_ 1068 1;
BA_ "CGEA_Message" BO_ 1068 1;
BA_ "GenMsgSendType" BO_ 1068 5;
BA_ "GenMsgCycleTime" BO_ 1068 1000;
BA_ "DiagResponse" BO_ 1931 1;
BA_ "VNATransmissionType" BO_ 1931 2;
BA_ "GenMsgSendType" BO_ 1931 1;
BA_ "GenMsgDelayTime" BO_ 1931 0;
BA_ "GenMsgILSupport" BO_ 1931 0;
BA_ "TpMessage" BO_ 1931 1;
BA_ "GenMsgIlSupport" BO_ 1931 0;
BA_ "VNATransmissionType" BO_ 757 1;
BA_ "GenMsgSendType" BO_ 757 5;
BA_ "GenMsgCycleTime" BO_ 757 1000;
BA_ "VNATransmissionType" BO_ 553 1;
BA_ "GenMsgSendType" BO_ 553 5;
BA_ "GenMsgCycleTime" BO_ 553 1000;
BA_ "VNATransmissionType" BO_ 257 1;
BA_ "GenMsgSendType" BO_ 257 1;
BA_ "VNATransmissionType" BO_ 546 1;
BA_ "GenMsgSendType" BO_ 546 5;
BA_ "GenMsgCycleTime" BO_ 546 1000;
BA_ "VNATransmissionType" BO_ 549 1;
BA_ "GenMsgSendType" BO_ 549 5;
BA_ "GenMsgCycleTime" BO_ 549 1000;
BA_ "VNATransmissionType" BO_ 544 1;
BA_ "GenMsgSendType" BO_ 544 5;
BA_ "GenMsgCycleTime" BO_ 544 1000;
BA_ "VNATransmissionType" BO_ 545 1;
BA_ "GenMsgSendType" BO_ 545 5;
BA_ "GenMsgCycleTime" BO_ 545 1000;
BA_ "GenMsgStartDelayTime" BO_ 545 150;
BA_ "VNATransmissionType" BO_ 552 1;
BA_ "GenMsgSendType" BO_ 552 5;
BA_ "GenMsgCycleTime" BO_ 552 1000;
BA_ "GenMsgStartDelayTime" BO_ 552 150;
BA_ "VNATransmissionType" BO_ 548 1;
BA_ "GenMsgSendType" BO_ 548 5;
BA_ "GenMsgCycleTime" BO_ 548 1000;
BA_ "GenMsgStartDelayTime" BO_ 548 150;
BA_ "VNATransmissionType" BO_ 1000 1;
BA_ "GenMsgSendType" BO_ 1000 5;
BA_ "GenMsgCycleTime" BO_ 1000 1000;
BA_ "SystemMessageLongSymbol" BO_ 1000 "AHU_Status_Message_asdfasdadfasdfasdfasdf";
BA_ "VNATransmissionType" BO_ 1478 2;
BA_ "NmAsrMessage" BO_ 1478 1;
BA_ "GenMsgSendType" BO_ 1478 1;
BA_ "GenMsgILSupport" BO_ 1478 0;
BA_ "VNATransmissionType" BO_ 1506 2;
BA_ "NmAsrMessage" BO_ 1506 1;
BA_ "GenMsgSendType" BO_ 1506 1;
BA_ "GenMsgILSupport" BO_ 1506 0;
BA_ "VNATransmissionType" BO_ 1034 1;
BA_ "GenMsgSendType" BO_ 1034 1;
BA_ "FrameGatewayId" BO_ 1034 1034;
BA_ "FrameGatewayHS1" BO_ 1034 1034;
BA_ "FrameGatewayLC1" BO_ 1034 1034;
BA_ "FrameGatewayNetwork_OLD" BO_ 1034 1;
BA_ "VNATransmissionType" BO_ 405 1;
BA_ "GenMsgSendType" BO_ 405 1;
BA_ "VNATransmissionType" BO_ 550 1;
BA_ "GenMsgSendType" BO_ 550 2;
BA_ "GenMsgCycleTimeFast" BO_ 550 100;
BA_ "VNATransmissionType" BO_ 755 1;
BA_ "GenMsgSendType" BO_ 755 5;
BA_ "GenMsgCycleTime" BO_ 755 1000;
BA_ "VNATransmissionType" BO_ 692 2;
BA_ "TpTxIndex" BO_ 692 15;
BA_ "VNATransmissionType" BO_ 700 2;
BA_ "TpTxIndex" BO_ 700 15;
BA_ "VNATransmissionType" BO_ 500 1;
BA_ "GenMsgSendType" BO_ 500 1;
BA_ "VNATransmissionType" BO_ 501 1;
BA_ "GenMsgSendType" BO_ 501 1;
BA_ "VNATransmissionType" BO_ 503 1;
BA_ "GenMsgSendType" BO_ 503 1;
BA_ "VNATransmissionType" BO_ 698 2;
BA_ "TpTxIndex" BO_ 698 13;
BA_ "VNATransmissionType" BO_ 702 2;
BA_ "TpTxIndex" BO_ 702 17;
BA_ "VNATransmissionType" BO_ 699 2;
BA_ "TpTxIndex" BO_ 699 14;
BA_ "VNATransmissionType" BO_ 691 2;
BA_ "TpTxIndex" BO_ 691 14;
BA_ "VNATransmissionType" BO_ 689 2;
BA_ "TpTxIndex" BO_ 689 12;
BA_ "VNATransmissionType" BO_ 401 1;
BA_ "GenMsgSendType" BO_ 401 1;
BA_ "VNATransmissionType" BO_ 400 1;
BA_ "GenMsgSendType" BO_ 400 1;
BA_ "VNATransmissionType" BO_ 756 1;
BA_ "GenMsgSendType" BO_ 756 5;
BA_ "GenMsgCycleTime" BO_ 756 1000;
BA_ "VNATransmissionType" BO_ 1425 2;
BA_ "NmAsrMessage" BO_ 1425 1;
BA_ "GenMsgSendType" BO_ 1425 1;
BA_ "GenMsgILSupport" BO_ 1425 0;
BA_ "VNATransmissionType" BO_ 477 1;
BA_ "GenMsgSendType" BO_ 477 1;
BA_ "VNATransmissionType" BO_ 476 1;
BA_ "GenMsgSendType" BO_ 476 1;
BA_ "VNATransmissionType" BO_ 474 1;
BA_ "GenMsgSendType" BO_ 474 1;
BA_ "VNATransmissionType" BO_ 473 1;
BA_ "GenMsgSendType" BO_ 473 1;
BA_ "VNATransmissionType" BO_ 479 1;
BA_ "GenMsgSendType" BO_ 479 1;
BA_ "VNATransmissionType" BO_ 726 1;
BA_ "GenMsgSendType" BO_ 726 5;
BA_ "GenMsgCycleTime" BO_ 726 1000;
BA_ "VNATransmissionType" BO_ 727 1;
BA_ "GenMsgSendType" BO_ 727 5;
BA_ "GenMsgCycleTime" BO_ 727 1000;
BA_ "GenMsgSendType" BO_ 119 5;
BA_ "GenMsgCycleTime" BO_ 119 1000;
BA_ "GenMsgDelayTime" BO_ 119 10;
BA_ "DiagState" BO_ 2015 1;
BA_ "VNATransmissionType" BO_ 2015 2;
BA_ "GenMsgSendType" BO_ 2015 1;
BA_ "GenMsgDelayTime" BO_ 2015 0;
BA_ "GenMsgILSupport" BO_ 2015 0;
BA_ "GenMsgIlSupport" BO_ 2015 0;
BA_ "TpMessage" BO_ 2015 1;
BA_ "DiagResponse" BO_ 1839 1;
BA_ "VNATransmissionType" BO_ 1839 2;
BA_ "GenMsgSendType" BO_ 1839 1;
BA_ "GenMsgDelayTime" BO_ 1839 0;
BA_ "GenMsgILSupport" BO_ 1839 0;
BA_ "DiagRequest" BO_ 1831 1;
BA_ "VNATransmissionType" BO_ 1831 2;
BA_ "GenMsgSendType" BO_ 1831 1;
BA_ "GenMsgDelayTime" BO_ 1831 0;
BA_ "GenMsgILSupport" BO_ 1831 0;
BA_ "NmMessage" BO_ 1297 1;
BA_ "VNATransmissionType" BO_ 1297 2;
BA_ "GenMsgILSupport" BO_ 1297 0;
BA_ "GenMsgIlSupport" BO_ 1297 0;
BA_ "NmMessage" BO_ 1292 1;
BA_ "VNATransmissionType" BO_ 1292 2;
BA_ "GenMsgILSupport" BO_ 1292 0;
BA_ "GenMsgSendType" BO_ 1241 0;
BA_ "GenMsgCycleTime" BO_ 1241 1000;
BA_ "GenMsgSendType" BO_ 1239 0;
BA_ "GenMsgCycleTime" BO_ 1239 1000;
BA_ "GenMsgSendType" BO_ 1232 0;
BA_ "GenMsgCycleTime" BO_ 1232 1000;
BA_ "VNATransmissionType" BO_ 1075 1;
BA_ "GenMsgSendType" BO_ 1075 5;
BA_ "GenMsgCycleTime" BO_ 1075 100;
BA_ "VNATransmissionType" BO_ 1029 1;
BA_ "GenMsgSendType" BO_ 1029 1;
BA_ "FrameGateway_nonCGEA" BO_ 1029 1029;
BA_ "VNATransmissionType" BO_ 1024 1;
BA_ "GenMsgSendType" BO_ 1024 1;
BA_ "FrameGateway_nonCGEA" BO_ 1024 1024;
BA_ "VNATransmissionType" BO_ 739 1;
BA_ "GenMsgSendType" BO_ 739 5;
BA_ "GenMsgCycleTime" BO_ 739 1000;
BA_ "VNATransmissionType" BO_ 736 1;
BA_ "GenMsgSendType" BO_ 736 5;
BA_ "GenMsgCycleTime" BO_ 736 1000;
BA_ "VNATransmissionType" BO_ 732 1;
BA_ "GenMsgSendType" BO_ 732 5;
BA_ "GenMsgCycleTime" BO_ 732 1000;
BA_ "VNATransmissionType" BO_ 731 1;
BA_ "GenMsgSendType" BO_ 731 5;
BA_ "GenMsgCycleTime" BO_ 731 1000;
BA_ "VNATransmissionType" BO_ 730 1;
BA_ "GenMsgSendType" BO_ 730 5;
BA_ "GenMsgCycleTime" BO_ 730 1000;
BA_ "VNATransmissionType" BO_ 729 1;
BA_ "GenMsgSendType" BO_ 729 5;
BA_ "GenMsgCycleTime" BO_ 729 1000;
BA_ "VNATransmissionType" BO_ 728 1;
BA_ "GenMsgSendType" BO_ 728 5;
BA_ "GenMsgCycleTime" BO_ 728 1000;
BA_ "VNATransmissionType" BO_ 725 1;
BA_ "GenMsgSendType" BO_ 725 5;
BA_ "GenMsgCycleTime" BO_ 725 1000;
BA_ "VNATransmissionType" BO_ 661 1;
BA_ "GenMsgSendType" BO_ 661 5;
BA_ "GenMsgCycleTime" BO_ 661 200;
BA_ "VNATransmissionType" BO_ 649 1;
BA_ "GenMsgSendType" BO_ 649 5;
BA_ "GenMsgCycleTime" BO_ 649 200;
BA_ "VNATransmissionType" BO_ 498 1;
BA_ "GenMsgSendType" BO_ 498 1;
BA_ "VNATransmissionType" BO_ 490 1;
BA_ "GenMsgSendType" BO_ 490 1;
BA_ "VNATransmissionType" BO_ 489 1;
BA_ "GenMsgSendType" BO_ 489 1;
BA_ "VNATransmissionType" BO_ 488 1;
BA_ "GenMsgSendType" BO_ 488 1;
BA_ "VNATransmissionType" BO_ 486 1;
BA_ "GenMsgSendType" BO_ 486 1;
BA_ "VNATransmissionType" BO_ 469 1;
BA_ "GenMsgSendType" BO_ 469 1;
BA_ "VNATransmissionType" BO_ 144 1;
BA_ "GenMsgSendType" BO_ 144 1;
BA_ "GenMsgDelayTime" BO_ 144 50;
BA_ "VNATransmissionType" BO_ 128 1;
BA_ "GenMsgSendType" BO_ 128 1;
BA_ "VNATransmissionType" BO_ 403 1;
BA_ "GenMsgSendType" BO_ 403 1;
BA_ "VNATransmissionType" BO_ 547 1;
BA_ "GenMsgSendType" BO_ 547 5;
BA_ "GenMsgCycleTime" BO_ 547 1000;
BA_ "VNATransmissionType" BO_ 765 1;
BA_ "GenMsgSendType" BO_ 765 5;
BA_ "GenMsgCycleTime" BO_ 765 1000;
BA_ "VNATransmissionType" BO_ 648 1;
BA_ "GenMsgSendType" BO_ 648 5;
BA_ "GenMsgCycleTime" BO_ 648 200;
BA_ "VNATransmissionType" BO_ 774 1;
BA_ "GenMsgSendType" BO_ 774 5;
BA_ "GenMsgCycleTime" BO_ 774 1000;
BA_ "VNATransmissionType" BO_ 775 1;
BA_ "GenMsgSendType" BO_ 775 5;
BA_ "GenMsgCycleTime" BO_ 775 1000;
BA_ "VNATransmissionType" BO_ 48 1;
BA_ "FISI_Comment_Msg" BO_ 48 "MFD5 needs to receive this message periodically at 100ms. Message need to remain as 'event' due to different gateway strategies.";
BA_ "GenMsgSendType" BO_ 48 1;
BA_ "VNATransmissionType" BO_ 673 1;
BA_ "FISI_Comment_Msg" BO_ 673 "Do not use this Frame for other Cluster Interaction";
BA_ "GenMsgSendType" BO_ 673 5;
BA_ "GenMsgCycleTime" BO_ 673 100;
BA_ "FrameGatewayId" BO_ 673 673;
BA_ "FrameGatewayHS2" BO_ 673 673;
BA_ "FrameGatewayNetwork_OLD" BO_ 673 2;
BA_ "VNATransmissionType" BO_ 483 1;
BA_ "GenMsgSendType" BO_ 483 1;
BA_ "GenMsgDelayTime" BO_ 483 50;
BA_ "VNATransmissionType" BO_ 777 1;
BA_ "GenMsgSendType" BO_ 777 5;
BA_ "GenMsgCycleTime" BO_ 777 1000;
BA_ "VNATransmissionType" BO_ 773 1;
BA_ "GenMsgSendType" BO_ 773 5;
BA_ "GenMsgCycleTime" BO_ 773 1000;
BA_ "VNATransmissionType" BO_ 769 1;
BA_ "GenMsgSendType" BO_ 769 5;
BA_ "GenMsgCycleTime" BO_ 769 1000;
BA_ "VNATransmissionType" BO_ 448 1;
BA_ "GenMsgSendType" BO_ 448 1;
BA_ "DiagRequest" BO_ 1957 1;
BA_ "VNATransmissionType" BO_ 1957 2;
BA_ "GenMsgSendType" BO_ 1957 1;
BA_ "GenMsgDelayTime" BO_ 1957 0;
BA_ "GenMsgILSupport" BO_ 1957 0;
BA_ "GenMsgIlSupport" BO_ 1957 0;
BA_ "TpMessage" BO_ 1957 1;
BA_ "DiagResponse" BO_ 1965 1;
BA_ "VNATransmissionType" BO_ 1965 2;
BA_ "GenMsgSendType" BO_ 1965 1;
BA_ "GenMsgDelayTime" BO_ 1965 0;
BA_ "GenMsgILSupport" BO_ 1965 0;
BA_ "TpMessage" BO_ 1965 1;
BA_ "GenMsgIlSupport" BO_ 1965 0;
BA_ "VNATransmissionType" BO_ 511 1;
BA_ "GenMsgSendType" BO_ 511 1;
BA_ "VNATransmissionType" BO_ 771 1;
BA_ "GenMsgSendType" BO_ 771 5;
BA_ "GenMsgCycleTime" BO_ 771 1000;
BA_ "VNATransmissionType" BO_ 494 1;
BA_ "GenMsgSendType" BO_ 494 1;
BA_ "VNATransmissionType" BO_ 734 1;
BA_ "GenMsgSendType" BO_ 734 5;
BA_ "GenMsgCycleTime" BO_ 734 1000;
BA_ "VNATransmissionType" BO_ 492 1;
BA_ "GenMsgSendType" BO_ 492 1;
BA_ "VNATransmissionType" BO_ 495 1;
BA_ "FISI_Comment_Msg" BO_ 495 "Exclusively used for BTDevices. Keep other CON messages out. ";
BA_ "GenMsgSendType" BO_ 495 1;
BA_ "VNATransmissionType" BO_ 701 2;
BA_ "TpTxIndex" BO_ 701 16;
BA_ "VNATransmissionType" BO_ 696 2;
BA_ "TpTxIndex" BO_ 696 11;
BA_ "VNATransmissionType" BO_ 509 1;
BA_ "GenMsgSendType" BO_ 509 1;
BA_ "VNATransmissionType" BO_ 742 1;
BA_ "GenMsgSendType" BO_ 742 5;
BA_ "GenMsgCycleTime" BO_ 742 1000;
BA_ "VNATransmissionType" BO_ 72 1;
BA_ "GenMsgSendType" BO_ 72 5;
BA_ "GenMsgCycleTime" BO_ 72 100;
BA_ "VNATransmissionType" BO_ 466 1;
BA_ "GenMsgSendType" BO_ 466 1;
BA_ "GenMsgSendType" BO_ 1235 0;
BA_ "GenMsgCycleTime" BO_ 1235 1000;
BA_ "VNATransmissionType" BO_ 502 1;
BA_ "GenMsgSendType" BO_ 502 1;
BA_ "GenSigSendType" SG_ 857 MultBtnPushDsplyPass10 3;
BA_ "GenSigSendType" SG_ 857 MultBtnPushDsplyPass1 3;
BA_ "GenSigSendType" SG_ 857 Report_Active 3;
BA_ "GenSigSendType" SG_ 857 Pass_Temp_Units 3;
BA_ "GenSigSendType" SG_ 857 Front_Fan_Bars_Disply 3;
BA_ "GenSigSendType" SG_ 857 Drvr_Temp_Units 3;
BA_ "GenSigSendType" SG_ 857 MultBtnPushDsplyDrvr10 3;
BA_ "GenSigSendType" SG_ 857 MultBtnPushDsplyDrvr1 3;
BA_ "GenSigSendType" SG_ 859 Voice_Blower_Limit 3;
BA_ "GenSigSendType" SG_ 859 Rear_Mode_Bttn_Status 3;
BA_ "GenSigSendType" SG_ 859 Rear_Temp_Button_Status 3;
BA_ "GenSigSendType" SG_ 859 Rear_Man_Temp_Bar_Stat 3;
BA_ "GenSigSendType" SG_ 859 Rear_Man_ATC_Button_Status 3;
BA_ "GenSigSendType" SG_ 859 Rear_Fan_Button_Status 3;
BA_ "GenSigSendType" SG_ 859 Rear_Blower_Bar_Status 3;
BA_ "GenSigSendType" SG_ 859 Frt_System_Button_Stat 3;
BA_ "GenSigTimeoutTime_IPC" SG_ 859 Frt_System_Button_Stat 2300;
BA_ "GenSigInactiveValue" SG_ 859 Driver_Set_Temp 32;
BA_ "GenSigStartValue" SG_ 859 Driver_Set_Temp 254;
BA_ "GenSigStartMeaning" SG_ 859 Driver_Set_Temp "No_Request";
BA_ "GenSigSendType" SG_ 859 Driver_Set_Temp 3;
BA_ "GenSigTimeoutTime_IPC" SG_ 859 Driver_Set_Temp 2300;
BA_ "GenSigSendType" SG_ 859 ConditionSt_ButtonStat 3;
BA_ "GenSigSendType" SG_ 859 HtdStrgWhl_Bttn_Stat 3;
BA_ "GenSigSendType" SG_ 858 Left_Front_Temp_Setpt 1;
BA_ "GenSigSendType" SG_ 858 Front_Blower_Request 1;
BA_ "GenSigSendType" SG_ 293 ClmtCtrlSeat_SetStat_Psgr 3;
BA_ "GenSigSendType" SG_ 293 ClmtCtrlSeat_SetStat_Dvr 3;
BA_ "FISI_Comment_Sig" SG_ 1068 BSBattSOC_UB "UB";
BA_ "FISI_Comment_Sig" SG_ 1068 BattTracWarnLamp_B_Rq_UB "UB";
BA_ "GenSigSendType" SG_ 1068 BattTracWarnLamp_B_Rq 3;
BA_ "FISI_Comment_Sig" SG_ 1068 BattTracSrvcRqd_B_Rq_UB "UB";
BA_ "GenSigSendType" SG_ 1068 BattTracSrvcRqd_B_Rq 3;
BA_ "FISI_Comment_Sig" SG_ 1068 BattTracSoc_Pc_Dsply_UB "UB";
BA_ "GenSigStartValue" SG_ 1068 BattTracSoc_Pc_Dsply 100;
BA_ "FISI_Comment_Sig" SG_ 1068 HtrnWarnLamp_B_Dsply_UB "UB";
BA_ "GenSigSendType" SG_ 1068 HtrnWarnLamp_B_Dsply 3;
BA_ "FISI_Comment_Sig" SG_ 1068 HtrnSrvcRqd_B_Dsply_UB "UB";
BA_ "GenSigSendType" SG_ 1068 HtrnSrvcRqd_B_Dsply 3;
BA_ "FISI_Comment_Sig" SG_ 1068 HtrnOvrTeLamp_B_Dsply_UB "UB";
BA_ "GenSigSendType" SG_ 1068 Shed_T_Eng_Off_B 3;
BA_ "GenSigSendType" SG_ 1068 Shed_Level_Req 3;
BA_ "WakeupSignal" SG_ 1068 Shed_Level_Req 1;
BA_ "GenSigSendType" SG_ 1068 Shed_Drain_Eng_Off_B 3;
BA_ "GenSigSendType" SG_ 1068 Batt_Lo_SoC_B 3;
BA_ "GenSigSendType" SG_ 1068 Batt_Crit_SoC_B 3;
BA_ "GenSigSendType" SG_ 1068 VehDynamicsSOS 3;
BA_ "FISI_Comment_Sig" SG_ 1068 VehDynamicsSOS_UB "UB";
BA_ "FISI_Comment_Sig" SG_ 1068 ObjectEntrapped_UB "UB";
BA_ "FISI_Comment_Sig" SG_ 1068 Batt_Lo_SoC_B_UB "UB";
BA_ "GenSigSendType" SG_ 1068 ObjectEntrapped 3;
BA_ "FISI_Comment_Sig" SG_ 1068 Shed_Level_Req_UB "UB";
BA_ "FISI_Comment_Sig" SG_ 1068 PwSysULoFalt_D_Stat_UB "UB";
BA_ "GenSigSendType" SG_ 1068 PwSysULoFalt_D_Stat 3;
BA_ "WakeupSignal" SG_ 1068 PwSysULoFalt_D_Stat 1;
BA_ "FISI_Comment_Sig" SG_ 1068 CcStat_D_Actl_UB "UB";
BA_ "GenSigSendType" SG_ 1068 CcStat_D_Actl 3;
BA_ "FISI_Comment_Sig" SG_ 1068 Batt_Crit_SoC_B_UB "UB";
BA_ "FISI_Comment_Sig" SG_ 1068 TrlrAidEnbl_D_Stat_UB "UB";
BA_ "FISI_Comment_Sig" SG_ 1068 TrlrAidMsgTxt_D_Rq_UB "UB";
BA_ "GenSigSendType" SG_ 1068 TrlrAidEnbl_D_Stat 3;
BA_ "GenSigSendType" SG_ 1068 TrlrAidMsgTxt_D_Rq 3;
BA_ "GenSigSendType" SG_ 1931 TesterPhysicalResDSP 3;
BA_ "GenSigSendType" SG_ 757 ACU_AutoStoreResult_St 3;
BA_ "GenSigSendType" SG_ 757 ACU_DirectTune_St 3;
BA_ "GenSigSendType" SG_ 757 ACU_RadioSeekMode2_St 3;
BA_ "GenSigTimeoutTime_MFD" SG_ 757 ACU_RadioSeekMode2_St 10000;
BA_ "GenSigSendType" SG_ 757 ACU_CurrTUBand_St 3;
BA_ "GenSigTimeoutTime_MFD" SG_ 757 ACU_CurrTUBand_St 10000;
BA_ "GenSigSendType" SG_ 553 Disp_LangSel_St 3;
BA_ "GenSigSendType" SG_ 553 Audio_Demo_CMND 3;
BA_ "GenSigSendType" SG_ 553 Surround_Sound_Upmix 3;
BA_ "GenSigSendType" SG_ 553 Bezel_Diag_State_Rq 3;
BA_ "GenSigSendType" SG_ 553 SurndSndUpmix2_D_Rq 3;
BA_ "GenSigSendType" SG_ 257 MFD_SetTagMode 3;
BA_ "GenSigSendType" SG_ 257 MFD_SetRBDSMode 3;
BA_ "GenSigSendType" SG_ 257 MFD_SetHDModeRq 3;
BA_ "GenSigSendType" SG_ 257 MFD_GetTagInfo 3;
BA_ "NWM-WakeupAllowed" SG_ 546 Alert_Chan 1;
BA_ "GenSigSendType" SG_ 546 Alert_Chan 3;
BA_ "GenSigSendType" SG_ 546 Audible_Beep 3;
BA_ "GenSigSendType" SG_ 546 SYNC_New_Attn_Event 3;
BA_ "GenSigSendType" SG_ 546 SYNC_Attn_Info_Audio 3;
BA_ "NWM-WakeupAllowed" SG_ 546 Prompt_Directionality 1;
BA_ "GenSigSendType" SG_ 546 Prompt_Directionality 3;
BA_ "GenSigSendType" SG_ 549 IPC_MyKeyVolLimit_St 3;
BA_ "GenSigSendType" SG_ 549 BeltminderAudioMute 3;
BA_ "GenSigSendType" SG_ 549 IPC_New_Attn_Event 3;
BA_ "GenSigSendType" SG_ 549 IPC_Attn_Info_Audio 3;
BA_ "GenSigSendType" SG_ 549 Power_Up_Chime_Modules 3;
BA_ "WakeupSignal" SG_ 549 Power_Up_Chime_Modules 1;
BA_ "GenSigSendType" SG_ 549 Chime_Source 3;
BA_ "GenSigSendType" SG_ 544 Chime 3;
BA_ "WakeupSignal" SG_ 544 Chime 1;
BA_ "GenSigSendType" SG_ 545 AudioOccMde_D_Stat 3;
BA_ "GenSigSendType" SG_ 545 AutoConfigOcc_Rear 3;
BA_ "GenSigSendType" SG_ 545 AutoConfigOcc_AllSeats 3;
BA_ "GenSigSendType" SG_ 545 AutoConfigOcc_Front 3;
BA_ "GenSigSendType" SG_ 545 AutoConfigOcc_Driver 3;
BA_ "GenSigSendType" SG_ 545 DSP_MyKeyVolLimitUp_St 3;
BA_ "GenSigSendType" SG_ 545 DSP_BeltminderAudio_St 3;
BA_ "GenSigSendType" SG_ 545 DSP_Bezel_Diag_St 3;
BA_ "GenSigSendType" SG_ 545 DSP_Sur_Sound_st 3;
BA_ "GenSigSendType" SG_ 545 DSP_Audio_Volume_Up_St 3;
BA_ "GenSigSendType" SG_ 545 SurndSndUpmix2_D_Stat 3;
BA_ "GenSigStartValue" SG_ 552 DSP_Midrange_St 15;
BA_ "InvalidHex" SG_ 552 DSP_Midrange_St "$F";
BA_ "GenSigSendType" SG_ 552 DSP_Midrange_St 3;
BA_ "GenSigSendType" SG_ 552 DSP_VoiceFBVolume_Up 1;
BA_ "InvalidHex" SG_ 552 DSP_VoiceFBVolume_St "$1F";
BA_ "GenSigStartValue" SG_ 552 DSP_Treble_St 15;
BA_ "InvalidHex" SG_ 552 DSP_Treble_St "$F";
BA_ "GenSigSendType" SG_ 552 DSP_Treble_St 3;
BA_ "GenSigSendType" SG_ 552 DSP_TAVolume_Up 1;
BA_ "InvalidHex" SG_ 552 DSP_TAVolume_St "$1F";
BA_ "GenSigSendType" SG_ 552 DSP_PhoneVolume_Up 1;
BA_ "InvalidHex" SG_ 552 DSP_PhoneVolume_St "$1F";
BA_ "GenSigSendType" SG_ 552 DSP_NavCmdVolume_Up 1;
BA_ "InvalidHex" SG_ 552 DSP_NavCmdVolume_St "$1F";
BA_ "GenSigStartValue" SG_ 552 DSP_Fader_St 15;
BA_ "InvalidHex" SG_ 552 DSP_Fader_St "$F";
BA_ "GenSigSendType" SG_ 552 DSP_Fader_St 3;
BA_ "GenSigSendType" SG_ 552 DSP_DSPProgram_St 3;
BA_ "GenSigSendType" SG_ 552 DSP_DSP_St 3;
BA_ "GenSigStartValue" SG_ 552 DSP_Bass_St 15;
BA_ "InvalidHex" SG_ 552 DSP_Bass_St "$F";
BA_ "GenSigSendType" SG_ 552 DSP_Bass_St 3;
BA_ "GenSigStartValue" SG_ 552 DSP_Balance_St 15;
BA_ "InvalidHex" SG_ 552 DSP_Balance_St "$F";
BA_ "GenSigSendType" SG_ 552 DSP_Balance_St 3;
BA_ "GenSigSendType" SG_ 552 DSP_AVC_St 3;
BA_ "GenSigSendType" SG_ 552 DSP_Shaker_St 3;
BA_ "GenSigSendType" SG_ 552 Audio_Demo_Status 3;
BA_ "GenSigSendType" SG_ 548 DSP_AHU_ChmTstTone_Rq 3;
BA_ "GenSigSendType" SG_ 548 DSP_ChimeChanState_St 3;
BA_ "LegacySignalName" SG_ 548 DSP_Chime2_Not_Recognized "DSP_Chime2_Not_Recognized";
BA_ "GenSigSendType" SG_ 548 DSP_Chime2_Not_Recognized 3;
BA_ "LegacySignalName" SG_ 548 DSP_Chime_Not_Recognized "DSP_Chime_Not_Recognized";
BA_ "GenSigSendType" SG_ 548 DSP_Chime_Not_Recognized 3;
BA_ "NWM-WakeupAllowed" SG_ 548 DSP_Alert_Channel3 1;
BA_ "VNASignalName" SG_ 548 DSP_Alert_Channel3 "*";
BA_ "GenSigSendType" SG_ 548 DSP_Alert_Channel3 3;
BA_ "NWM-WakeupAllowed" SG_ 548 DSP_Alert_Channel2 1;
BA_ "VNASignalName" SG_ 548 DSP_Alert_Channel2 "*";
BA_ "GenSigSendType" SG_ 548 DSP_Alert_Channel2 3;
BA_ "NWM-WakeupAllowed" SG_ 548 DSP_Alert_Channel1 1;
BA_ "VNASignalName" SG_ 548 DSP_Alert_Channel1 "*";
BA_ "GenSigSendType" SG_ 548 DSP_Alert_Channel1 3;
BA_ "NWM-WakeupAllowed" SG_ 548 DSP_Chimes_Supported 1;
BA_ "VNASignalName" SG_ 548 DSP_Chimes_Supported "*";
BA_ "GenSigSendType" SG_ 548 DSP_Chimes_Supported 3;
BA_ "GenSigSendType" SG_ 1000 AHU_Bezel_Diag_St 3;
BA_ "GenSigSendType" SG_ 1000 MyKeyVolumeLimitMode 3;
BA_ "GenSigSendType" SG_ 1000 MyKeyVolumeLimitUp 3;
BA_ "GenSigSendType" SG_ 1000 ACM_BeltminderAudioSt 3;
BA_ "GenSigSendType" SG_ 1000 AHU_Shaker_St 3;
BA_ "GenSigSendType" SG_ 1478 DSP_AutoSar_Network_Mgmt 3;
BA_ "GenSigSendType" SG_ 1506 APIM_AutoSar_Network_Mgmt 3;
BA_ "GenSigSendType" SG_ 1034 VehicleGGCCData 3;
BA_ "InvalidHex" SG_ 405 LBC1_Opcode "$3";
BA_ "GenSigSendType" SG_ 405 LBC1_Opcode 3;
BA_ "GenSigInactiveValue" SG_ 550 Band1 15;
BA_ "GenSigStartValue" SG_ 550 Band1 15;
BA_ "GenSigSendType" SG_ 550 Band1 6;
BA_ "InvalidHex" SG_ 755 ACU_AudioMixRatio_St "$1F";
BA_ "GenSigSendType" SG_ 755 ACU_AudioMixRatio_St 3;
BA_ "GenSigTimeoutTime_MFD" SG_ 755 ACU_AudioMixRatio_St 10000;
BA_ "VNASignalName" SG_ 692 AUDIO_RDISP_WORD_Tx "AUDIO_RDISP_WORD_Tx_I";
BA_ "VNASignalName" SG_ 700 AUDIO_RDISP_WORD_Rx "AUDIO_RDISP_WORD_Rx_I";
BA_ "GenSigSendType" SG_ 500 Dsp_GetCDTOCDData_Rq 3;
BA_ "GenSigSendType" SG_ 500 Dsp_AudioSourceSel_Rq 3;
BA_ "InvalidHex" SG_ 500 Dsp_FolderNumber_Rq "$FFFF";
BA_ "InvalidHex" SG_ 500 Dsp_ItemNameLength_Rq "$0";
BA_ "InvalidHex" SG_ 500 Dsp_SourceSetTrack_Rq "$0000";
BA_ "GenSigSendType" SG_ 501 Dsp_FreezeFMSL_Rq 3;
BA_ "InvalidHex" SG_ 501 Dsp_SetCurrFMSLPr_Rq "$0";
BA_ "GenSigSendType" SG_ 501 Dsp_SetCurrFMSLPr_Rq 3;
BA_ "GenSigSendType" SG_ 501 Dsp_SetRadSeekMode_Rq 3;
BA_ "GenSigSendType" SG_ 501 Dsp_SetCurrPreset2_Rq 3;
BA_ "GenSigSendType" SG_ 503 Dsp_AudioSourceSel3_Rq 3;
BA_ "VNASignalName" SG_ 698 CONMP_RDISP_WORD_Rx "CONMP_RDISP_WORD_Rx_I";
BA_ "VNASignalName" SG_ 699 PHONE_RDSP_WORD_Rx "PHONE_RDSP_WORD_Rx_I";
BA_ "VNASignalName" SG_ 691 PHONE_RDSP_WORD_Tx "PHONE_RDSP_WORD_Tx_I";
BA_ "GenSigStartValue" SG_ 401 Disp_VehUnitTripCoUsrSel 3;
BA_ "LegacySignalName" SG_ 401 Disp_VehUnitTripCoUsrSel "Disp_VehUnitTripCoUsrSel";
BA_ "GenSigSendType" SG_ 401 Disp_VehUnitTripCoUsrSel 3;
BA_ "GenSigStartValue" SG_ 401 Disp_VehUnitTempUsrSel 3;
BA_ "GenSigSendType" SG_ 401 Disp_VehUnitTempUsrSel 3;
BA_ "GenSigSendType" SG_ 401 Disp_LangSel_Rq 3;
BA_ "InvalidHex" SG_ 400 Mc_PerTUStartIndex2_Rq "$0";
BA_ "GenSigSendType" SG_ 400 Mc_PerTUPresetArea_Rq 3;
BA_ "InvalidHex" SG_ 400 Mc_PerTUNbrOfPresets_Rq "$0";
BA_ "GenSigStartValue" SG_ 400 Mc_SDARS_DirectTune_Rq 255;
BA_ "GenSigSendType" SG_ 400 Mc_SDARS_DirectTune_Rq 3;
BA_ "InvalidHex" SG_ 400 Mc_SetCurrentStatFreq_Rq "$7FF";
BA_ "LegacySignalName" SG_ 400 Mc_SetCurrentStatFreq_Rq "Mc_SetCurrentStatFreq_Rq";
BA_ "GenSigSendType" SG_ 400 Mc_SetCurrentStatOp_Rq 3;
BA_ "GenSigSendType" SG_ 756 Chime2 3;
BA_ "GenSigSendType" SG_ 1425 IPC_AutoSar_Network_Mgmt 3;
BA_ "GenSigStartValue" SG_ 477 NAV_SetBass_Rq 15;
BA_ "GenSigSendType" SG_ 477 NAV_SetBass_Rq 3;
BA_ "GenSigStartValue" SG_ 477 NAV_SetTreble_Rq 15;
BA_ "GenSigSendType" SG_ 477 NAV_SetTreble_Rq 3;
BA_ "GenSigStartValue" SG_ 477 NAV_SetFader_Rq 15;
BA_ "GenSigSendType" SG_ 477 NAV_SetFader_Rq 3;
BA_ "GenSigStartValue" SG_ 477 NAV_SetBalance_Rq 15;
BA_ "GenSigSendType" SG_ 477 NAV_SetBalance_Rq 3;
BA_ "GenSigStartValue" SG_ 477 NAV_SetAVC_Rq 15;
BA_ "GenSigSendType" SG_ 477 NAV_SetAVC_Rq 3;
BA_ "LegacySignalName" SG_ 477 NAV_SecurityPINUnlock_Rq "NAV_SecurityPINUnlock_Rq";
BA_ "GenSigSendType" SG_ 477 NAV_SecurityPINUnlock_Rq 3;
BA_ "GenSigSendType" SG_ 477 NAV_LoadEjectMode_Rq 3;
BA_ "GenSigSendType" SG_ 476 NAV_SetDSPProgram_Rq 3;
BA_ "GenSigSendType" SG_ 476 NAV_SkipCatalouge_Rq 3;
BA_ "GenSigSendType" SG_ 476 NAV_SetOperationMode_Rq 3;
BA_ "GenSigStartValue" SG_ 476 Nav_SetAudioMixRatio_Rq 31;
BA_ "GenSigSendType" SG_ 476 Nav_SetAudioMixRatio_Rq 3;
BA_ "GenSigStartValue" SG_ 474 NAV_SetMid_Rq 15;
BA_ "GenSigSendType" SG_ 474 NAV_SetMid_Rq 3;
BA_ "GenSigSendType" SG_ 474 NAV_SetNEWSMode_Rq 3;
BA_ "GenSigSendType" SG_ 474 NAV_SetDSP_Rq 3;
BA_ "InvalidHex" SG_ 474 NAV_SetCurrentStatFreq_Rq "$7FF";
BA_ "LegacySignalName" SG_ 474 NAV_SetCurrentStatFreq_Rq "NAV_SetCurrentStatFreq_Rq";
BA_ "LegacySignalName" SG_ 474 NAV_ARRquesterPriority_Rq "NAV_ARRquesterPriority_Rq";
BA_ "LegacySignalName" SG_ 474 NAV_ARRequesterSystem_Rq "NAV_ARRequesterSystem_Rq";
BA_ "GenSigSendType" SG_ 474 NAV_AROperationType_Rq 3;
BA_ "GenSigSendType" SG_ 474 NAV_SetCurrentStatOp_Rq 3;
BA_ "GenSigSendType" SG_ 473 NAV_SetTUServiceLink_Rq 3;
BA_ "GenSigSendType" SG_ 473 NAV_StorePreset_Rq 3;
BA_ "GenSigSendType" SG_ 473 NAV_SetTAMode_Rq 3;
BA_ "GenSigSendType" SG_ 473 NAV_SetReg_Rq 3;
BA_ "GenSigSendType" SG_ 473 NAV_SetAFMode_Rq 3;
BA_ "LegacySignalName" SG_ 473 NAV_SelectPTYCodesSet_Rq "NAV_SelectPTYCodesSet_Rq";
BA_ "GenSigSendType" SG_ 473 NAV_SelectPTYCodesSet_Rq 3;
BA_ "InvalidHex" SG_ 473 NAV_SelectPTYCodes_Rq "n/a";
BA_ "GenSigSendType" SG_ 473 NAV_CDSetShuffle_Rq 3;
BA_ "GenSigSendType" SG_ 473 NAV_CDSetRepeat_Rq 3;
BA_ "GenSigSendType" SG_ 473 NAV_CDSetIntroScan_Rq 3;
BA_ "GenSigSendType" SG_ 479 DISP_SetVol_Source_Rq 3;
BA_ "GenSigStartValue" SG_ 479 DISP_SetVolume_Rq 30;
BA_ "GenSigSendType" SG_ 479 DISP_SetVolume_Rq 3;
BA_ "GenSigSendType" SG_ 726 ACU_AFJump_St 3;
BA_ "GenSigSendType" SG_ 726 ACU_NEWSMode_St 3;
BA_ "GenSigTimeoutTime_MFD" SG_ 726 ACU_NEWSMode_St 10000;
BA_ "GenSigSendType" SG_ 726 ACU_SelectedPTYCodes_St 3;
BA_ "GenSigSendType" SG_ 726 ACU_TAMode_St 3;
BA_ "GenSigTimeoutTime_MFD" SG_ 726 ACU_TAMode_St 10000;
BA_ "GenSigTimeoutTime_MFD" SG_ 727 ACU_LoadEjectDisc_St 10000;
BA_ "GenSigSendType" SG_ 727 ACU_LoadEjectMode_St 3;
BA_ "GenSigTimeoutTime_MFD" SG_ 727 ACU_LoadEjectMode_St 10000;
BA_ "FISI_Comment_Sig" SG_ 119 BpedDrvAppl_D_Actl_UB "UB";
BA_ "GenSigStartValue" SG_ 119 BpedDrvAppl_D_Actl 1;
BA_ "GenSigSendType" SG_ 119 BpedDrvAppl_D_Actl 3;
BA_ "FISI_Comment_Sig" SG_ 119 HsaStat_D_Actl_UB "UB";
BA_ "GenSigSendType" SG_ 119 HsaStat_D_Actl 3;
BA_ "GenSigSendType" SG_ 119 EPAS_Failure 3;
BA_ "FISI_Comment_Sig" SG_ 119 EPAS_Failure_UB "UB";
BA_ "FISI_Comment_Sig" SG_ 119 SAPPStatusCoding_UB "UB";
BA_ "GenSigSendType" SG_ 119 SAPPStatusCoding 3;
BA_ "FISI_Comment_Sig" SG_ 119 CcOvrrdActv_B_Actl_UB "UB";
BA_ "GenSigSendType" SG_ 119 CcOvrrdActv_B_Actl 3;
BA_ "FISI_Comment_Sig" SG_ 119 EngPullUpPullDown_D_Rq_UB "UB";
BA_ "GenSigSendType" SG_ 119 EngPullUpPullDown_D_Rq 3;
BA_ "FISI_Comment_Sig" SG_ 119 VehYawComp_W_Actl_UB "UB";
BA_ "GenSigSendType" SG_ 119 Veh_V_DsplyCcSet 3;
BA_ "GenSigSendType" SG_ 119 VehYawComp_W_Actl 3;
BA_ "GenSigSendType" SG_ 119 VehYaw_W_Rq 3;
BA_ "FISI_Comment_Sig" SG_ 119 Veh_V_DsplyCcSet_UB "UB";
BA_ "FISI_Comment_Sig" SG_ 119 VehYaw_W_Rq_UB "UB";
BA_ "VNASignalName" SG_ 2015 TesterFunctionalReq "HEC_DIAG_FA";
BA_ "GenSigSendType" SG_ 2015 TesterFunctionalReq 3;
BA_ "GenSigSendType" SG_ 1839 TesterPhysicalResACM 3;
BA_ "GenSigSendType" SG_ 1831 TesterPhysicalReqACM 3;
BA_ "InvalidHex" SG_ 1241 EATC_TempRangeOffset "$FF";
BA_ "GenSigTimeoutTime_MFD" SG_ 1241 EATC_TempRangeOffset 10000;
BA_ "InvalidHex" SG_ 1241 EATC_TempRangeStart "$FF";
BA_ "GenSigTimeoutTime_MFD" SG_ 1241 EATC_TempRangeStart 10000;
BA_ "InvalidHex" SG_ 1241 EATC_BlowerSpeedMAX "$F";
BA_ "GenSigTimeoutTime_MFD" SG_ 1241 EATC_BlowerSpeedMAX 10000;
BA_ "InvalidHex" SG_ 1241 EATC_BlowerSpeedMIN "$F";
BA_ "GenSigTimeoutTime_MFD" SG_ 1241 EATC_BlowerSpeedMIN 10000;
BA_ "InvalidHex" SG_ 1239 HEC_NbrOfItems_St "$1F";
BA_ "VNASignalName" SG_ 1239 HEC_NbrOfItems_St "HEC_NbrOfItems_StX";
BA_ "InvalidHex" SG_ 1239 HEC_ItemNameLength_St "$0";
BA_ "VNASignalName" SG_ 1239 HEC_ItemNameLength_St "HEC_ItemNameLength_StX";
BA_ "GenSigTimeoutTime_MFD" SG_ 1239 HEC_VehicleConfig 10000;
BA_ "LegacySignalName" SG_ 1232 AHU_AutoConfigOcc_Shaker "AHU_AutoConfigOcc_Shaker";
BA_ "LegacySignalName" SG_ 1232 AHU_AutoConfigOcc_Driver "AHU_AutoConfigOcc_Driver";
BA_ "LegacySignalName" SG_ 1232 AHU_AutoConfigOcc_Convert "AHU_AutoConfigOcc_Convert";
BA_ "LegacySignalName" SG_ 1232 AHU_AutoConfigOcc_Allseats "AHU_AutoConfigOcc_Allseats";
BA_ "GenSigTimeoutTime_MFD" SG_ 1232 ACU_Configuration 10000;
BA_ "GenSigTimeoutTime_MFD" SG_ 1232 ACU_DigitalRadio_St 10000;
BA_ "GenSigTimeoutTime_MFD" SG_ 1232 ACU_MediaPlayer_St 10000;
BA_ "GenSigStartValue" SG_ 1075 PJB_LockStatusValid 1;
BA_ "VNASignalName" SG_ 1075 PJB_LockStatusValid "PJB_LockStatusValidI";
BA_ "GenSigSendType" SG_ 1075 PJB_LockStatusValid 3;
BA_ "GenSigTimeoutTime_MFD" SG_ 1075 PJB_LockStatusValid 2000;
BA_ "VNASignalName" SG_ 1075 PJB_LockStatus "PJB_LockStatusI";
BA_ "GenSigSendType" SG_ 1075 PJB_LockStatus 3;
BA_ "GenSigTimeoutTime_MFD" SG_ 1075 PJB_LockStatus 2000;
BA_ "VNASignalName" SG_ 1075 PJB_ReverseGearSwitch "PJB_ReverseGearSwitchI";
BA_ "GenSigSendType" SG_ 1075 PJB_ReverseGearSwitch 3;
BA_ "VNASignalName" SG_ 1075 PJB_DriverDoorStatus "PJB_DriverDoorStatusI";
BA_ "GenSigSendType" SG_ 1075 PJB_DriverDoorStatus 3;
BA_ "GenSigTimeoutTime_MFD" SG_ 1075 PJB_DriverDoorStatus 2000;
BA_ "InvalidHex" SG_ 1075 PJB_PassengerDoorStatus "NA";
BA_ "VNASignalName" SG_ 1075 PJB_PassengerDoorStatus "PJB_PassengerDoorStatusI";
BA_ "GenSigSendType" SG_ 1075 PJB_PassengerDoorStatus 3;
BA_ "GenSigTimeoutTime_MFD" SG_ 1075 PJB_PassengerDoorStatus 2000;
BA_ "InvalidHex" SG_ 1075 PJB_LeftRearDoorStatus "NA";
BA_ "GenSigSendType" SG_ 1075 PJB_LeftRearDoorStatus 3;
BA_ "GenSigTimeoutTime_MFD" SG_ 1075 PJB_LeftRearDoorStatus 2000;
BA_ "InvalidHex" SG_ 1075 PJB_RightRearDoorStatus "NA";
BA_ "GenSigSendType" SG_ 1075 PJB_RightRearDoorStatus 3;
BA_ "GenSigTimeoutTime_MFD" SG_ 1075 PJB_RightRearDoorStatus 2000;
BA_ "GenSigSendType" SG_ 1075 PJB_BootLidStatus 3;
BA_ "GenSigTimeoutTime_MFD" SG_ 1075 PJB_BootLidStatus 2000;
BA_ "VNASignalName" SG_ 1029 VehicleInfoSignal "VehicleInfoParametersMS";
BA_ "GenSigSendType" SG_ 1029 VehicleInfoSignal 1;
BA_ "VNASignalName" SG_ 1024 CarConfigSignal "VehicleConfParametersMS";
BA_ "GenSigSendType" SG_ 1024 CarConfigSignal 1;
BA_ "GenSigSendType" SG_ 739 HMI_HMIMode_St 3;
BA_ "WakeupSignal" SG_ 739 HMI_HMIMode_St 1;
BA_ "GenSigTimeoutTime_AHU" SG_ 739 HMI_HMIMode_St 10000;
BA_ "GenSigTimeoutTime_IPC" SG_ 739 HMI_HMIMode_St 2300;
BA_ "GenSigSendType" SG_ 736 TextMessage_Rsp 3;
BA_ "InvalidHex" SG_ 736 VRM_CallDuration_St "$FFFF";
BA_ "GenSigSendType" SG_ 736 VRM_CallDuration_St 3;
BA_ "GenSigTimeoutTime_MFD" SG_ 736 VRM_CallDuration_St 10000;
BA_ "GenSigSendType" SG_ 736 BTInCallOptions_St 3;
BA_ "GenSigSendType" SG_ 732 ACU_FunctionStatus_St 3;
BA_ "GenSigTimeoutTime_MFD" SG_ 732 ACU_FunctionStatus_St 10000;
BA_ "InvalidHex" SG_ 732 ACU_CurrFMSLPreset_St "$0";
BA_ "GenSigSendType" SG_ 732 ACU_CurrFMSLPreset_St 3;
BA_ "GenSigTimeoutTime_MFD" SG_ 732 ACU_CurrFMSLPreset_St 10000;
BA_ "InvalidHex" SG_ 732 ACU_CurrPreset2_St "$0";
BA_ "GenSigSendType" SG_ 732 ACU_CurrPreset2_St 3;
BA_ "GenSigTimeoutTime_MFD" SG_ 732 ACU_CurrPreset2_St 10000;
BA_ "InvalidHex" SG_ 732 ACU_StorePreset_St "$0";
BA_ "GenSigSendType" SG_ 732 ACU_StorePreset_St 3;
BA_ "GenSigTimeoutTime_MFD" SG_ 732 ACU_StorePreset_St 10000;
BA_ "InvalidHex" SG_ 731 ACU_NumberofTracks_St "$0000";
BA_ "GenSigSendType" SG_ 731 ACU_NumberofTracks_St 3;
BA_ "GenSigTimeoutTime_MFD" SG_ 731 ACU_NumberofTracks_St 10000;
BA_ "InvalidHex" SG_ 731 ACU_TotalPlayTime_St "$FFFF";
BA_ "GenSigSendType" SG_ 731 ACU_TotalPlayTime_St 3;
BA_ "GenSigTimeoutTime_MFD" SG_ 731 ACU_TotalPlayTime_St 10000;
BA_ "InvalidHex" SG_ 731 ACU_TrackPlaytime_St "$FFFF";
BA_ "GenSigSendType" SG_ 731 ACU_TrackPlaytime_St 3;
BA_ "GenSigTimeoutTime_MFD" SG_ 731 ACU_TrackPlaytime_St 10000;
BA_ "InvalidHex" SG_ 730 ACU_ActiveDiscNumber_St "$0";
BA_ "GenSigSendType" SG_ 730 ACU_ActiveDiscNumber_St 3;
BA_ "GenSigTimeoutTime_MFD" SG_ 730 ACU_ActiveDiscNumber_St 10000;
BA_ "GenSigSendType" SG_ 730 ACU_CDIntroScan_St 3;
BA_ "GenSigTimeoutTime_MFD" SG_ 730 ACU_CDIntroScan_St 10000;
BA_ "GenSigSendType" SG_ 730 ACU_CDRepeat_St 3;
BA_ "GenSigTimeoutTime_MFD" SG_ 730 ACU_CDRepeat_St 10000;
BA_ "GenSigSendType" SG_ 730 ACU_CDShuffle_St 3;
BA_ "GenSigTimeoutTime_MFD" SG_ 730 ACU_CDShuffle_St 10000;
BA_ "HS3_Category" SG_ 730 ACU_Coding_St 1;
BA_ "GenSigSendType" SG_ 730 ACU_Coding_St 3;
BA_ "GenSigTimeoutTime_MFD" SG_ 730 ACU_Coding_St 10000;
BA_ "GenSigSendType" SG_ 730 ACU_DiscCoding_St 3;
BA_ "GenSigSendType" SG_ 730 ACU_MagazineSlots_St 3;
BA_ "GenSigTimeoutTime_MFD" SG_ 730 ACU_MagazineSlots_St 10000;
BA_ "GenSigSendType" SG_ 730 ACU_OperationMode_St 3;
BA_ "GenSigTimeoutTime_MFD" SG_ 730 ACU_OperationMode_St 10000;
BA_ "InvalidHex" SG_ 729 ACU_AVC_St "$F";
BA_ "GenSigSendType" SG_ 729 ACU_AVC_St 3;
BA_ "GenSigTimeoutTime_MFD" SG_ 729 ACU_AVC_St 10000;
BA_ "GenSigStartValue" SG_ 729 ACU_Balance_St 15;
BA_ "InvalidHex" SG_ 729 ACU_Balance_St "$F";
BA_ "GenSigSendType" SG_ 729 ACU_Balance_St 3;
BA_ "GenSigTimeoutTime_MFD" SG_ 729 ACU_Balance_St 10000;
BA_ "GenSigStartValue" SG_ 729 ACU_Bass_St 15;
BA_ "InvalidHex" SG_ 729 ACU_Bass_St "$F";
BA_ "GenSigSendType" SG_ 729 ACU_Bass_St 3;
BA_ "GenSigTimeoutTime_MFD" SG_ 729 ACU_Bass_St 10000;
BA_ "GenSigSendType" SG_ 729 ACU_DSP_St 3;
BA_ "GenSigTimeoutTime_MFD" SG_ 729 ACU_DSP_St 10000;
BA_ "GenSigSendType" SG_ 729 ACU_DSPProgram_St 3;
BA_ "GenSigTimeoutTime_MFD" SG_ 729 ACU_DSPProgram_St 10000;
BA_ "GenSigStartValue" SG_ 729 ACU_Fader_St 15;
BA_ "InvalidHex" SG_ 729 ACU_Fader_St "$F";
BA_ "GenSigSendType" SG_ 729 ACU_Fader_St 3;
BA_ "GenSigTimeoutTime_MFD" SG_ 729 ACU_Fader_St 10000;
BA_ "InvalidHex" SG_ 729 ACU_NavCmdVolume_St "$1F";
BA_ "GenSigSendType" SG_ 729 ACU_NavCmdVolume_St 3;
BA_ "GenSigTimeoutTime_MFD" SG_ 729 ACU_NavCmdVolume_St 10000;
BA_ "GenSigSendType" SG_ 729 ACU_NavCmdVolume_Up 3;
BA_ "GenSigTimeoutTime_MFD" SG_ 729 ACU_NavCmdVolume_Up 10000;
BA_ "InvalidHex" SG_ 729 ACU_PhoneVolume_St "$1F";
BA_ "GenSigSendType" SG_ 729 ACU_PhoneVolume_St 3;
BA_ "GenSigTimeoutTime_MFD" SG_ 729 ACU_PhoneVolume_St 10000;
BA_ "GenSigSendType" SG_ 729 ACU_PhoneVolume_Up 3;
BA_ "GenSigTimeoutTime_MFD" SG_ 729 ACU_PhoneVolume_Up 10000;
BA_ "GenSigSendType" SG_ 729 ACU_Reg_St 3;
BA_ "GenSigTimeoutTime_MFD" SG_ 729 ACU_Reg_St 10000;
BA_ "InvalidHex" SG_ 729 ACU_TAVolume_St "$1F";
BA_ "GenSigSendType" SG_ 729 ACU_TAVolume_St 3;
BA_ "GenSigTimeoutTime_MFD" SG_ 729 ACU_TAVolume_St 10000;
BA_ "GenSigSendType" SG_ 729 ACU_TAVolume_Up 3;
BA_ "GenSigTimeoutTime_MFD" SG_ 729 ACU_TAVolume_Up 10000;
BA_ "GenSigStartValue" SG_ 729 ACU_Treble_St 15;
BA_ "InvalidHex" SG_ 729 ACU_Treble_St "$F";
BA_ "GenSigSendType" SG_ 729 ACU_Treble_St 3;
BA_ "GenSigTimeoutTime_MFD" SG_ 729 ACU_Treble_St 10000;
BA_ "InvalidHex" SG_ 729 ACU_VoiceFBVolume_St "$1F";
BA_ "GenSigSendType" SG_ 729 ACU_VoiceFBVolume_St 3;
BA_ "GenSigTimeoutTime_MFD" SG_ 729 ACU_VoiceFBVolume_St 10000;
BA_ "GenSigSendType" SG_ 729 ACU_VoiceFBVolume_Up 3;
BA_ "GenSigTimeoutTime_MFD" SG_ 729 ACU_VoiceFBVolume_Up 10000;
BA_ "GenSigSendType" SG_ 728 AudioDrvMde_D_Stat 3;
BA_ "GenSigSendType" SG_ 728 ACU_CDError_St 3;
BA_ "GenSigTimeoutTime_MFD" SG_ 728 ACU_CDError_St 10000;
BA_ "GenSigSendType" SG_ 728 ACU_CurrentStatFlags_St 3;
BA_ "GenSigTimeoutTime_MFD" SG_ 728 ACU_CurrentStatFlags_St 10000;
BA_ "GenSigStartValue" SG_ 728 ACU_Mid_St 15;
BA_ "InvalidHex" SG_ 728 ACU_Mid_St "$F";
BA_ "GenSigSendType" SG_ 728 ACU_Mid_St 3;
BA_ "GenSigTimeoutTime_MFD" SG_ 728 ACU_Mid_St 10000;
BA_ "GenSigSendType" SG_ 728 ACU_RadioSeekMode_St 3;
BA_ "GenSigTimeoutTime_MFD" SG_ 728 ACU_RadioSeekMode_St 10000;
BA_ "InvalidHex" SG_ 728 ACU_Volume_St "$1F";
BA_ "GenSigSendType" SG_ 728 ACU_Volume_St 3;
BA_ "GenSigTimeoutTime_MFD" SG_ 728 ACU_Volume_St 10000;
BA_ "GenSigSendType" SG_ 728 ACU_Volume_Up 1;
BA_ "GenSigTimeoutTime_MFD" SG_ 728 ACU_Volume_Up 10000;
BA_ "GenSigSendType" SG_ 725 ACU_CompLogic_St 3;
BA_ "GenSigSendType" SG_ 725 ACU_RadioError_St 3;
BA_ "GenSigTimeoutTime_MFD" SG_ 725 ACU_RadioError_St 10000;
BA_ "GenSigSendType" SG_ 725 ACU_HardwareError_St 3;
BA_ "GenSigTimeoutTime_MFD" SG_ 725 ACU_HardwareError_St 10000;
BA_ "InvalidHex" SG_ 725 ACU_CurrentPTYCode_St "$00";
BA_ "GenSigSendType" SG_ 725 ACU_CurrentPTYCode_St 3;
BA_ "GenSigTimeoutTime_MFD" SG_ 725 ACU_CurrentPTYCode_St 10000;
BA_ "InvalidHex" SG_ 725 ACU_CurrentPICode_St "$1FFFF";
BA_ "GenSigSendType" SG_ 725 ACU_CurrentPICode_St 3;
BA_ "GenSigTimeoutTime_MFD" SG_ 725 ACU_CurrentPICode_St 10000;
BA_ "InvalidHex" SG_ 725 ACU_CurrentFreq_St "$7FF";
BA_ "GenSigSendType" SG_ 725 ACU_CurrentFreq_St 3;
BA_ "GenSigTimeoutTime_MFD" SG_ 725 ACU_CurrentFreq_St 10000;
BA_ "GenSigSendType" SG_ 725 ACU_AFMode_St 3;
BA_ "GenSigTimeoutTime_MFD" SG_ 725 ACU_AFMode_St 10000;
BA_ "GenSigSendType" SG_ 661 EATC_DISPupdate_Defrost 3;
BA_ "GenSigTimeoutTime_MFD" SG_ 661 EATC_DISPupdate_Defrost 2000;
BA_ "GenSigSendType" SG_ 661 EATC_DISPupdate_MAXAC 3;
BA_ "GenSigTimeoutTime_MFD" SG_ 661 EATC_DISPupdate_MAXAC 2000;
BA_ "GenSigSendType" SG_ 661 EATC_MAXACMode 3;
BA_ "GenSigTimeoutTime_MFD" SG_ 661 EATC_MAXACMode 2000;
BA_ "GenSigSendType" SG_ 661 EATC_DISPupdate_AutoMode 3;
BA_ "GenSigTimeoutTime_MFD" SG_ 661 EATC_DISPupdate_AutoMode 2000;
BA_ "GenSigSendType" SG_ 661 EATC_DISPupdate_ACMode 3;
BA_ "GenSigTimeoutTime_MFD" SG_ 661 EATC_DISPupdate_ACMode 2000;
BA_ "GenSigSendType" SG_ 661 EATC_DISPupdate_AirMode 3;
BA_ "GenSigTimeoutTime_MFD" SG_ 661 EATC_DISPupdate_AirMode 2000;
BA_ "GenSigSendType" SG_ 661 EATC_DISPupdate_BlowerSpd 3;
BA_ "GenSigTimeoutTime_MFD" SG_ 661 EATC_DISPupdate_BlowerSpd 2000;
BA_ "GenSigSendType" SG_ 661 EATC_DISPupdate_TempCoDr 3;
BA_ "GenSigTimeoutTime_MFD" SG_ 661 EATC_DISPupdate_TempCoDr 2000;
BA_ "GenSigSendType" SG_ 661 EATC_DISPupdate_TempDr 3;
BA_ "GenSigTimeoutTime_MFD" SG_ 661 EATC_DISPupdate_TempDr 2000;
BA_ "GenSigSendType" SG_ 661 EATC_DISPupdate_SysMode 3;
BA_ "GenSigTimeoutTime_MFD" SG_ 661 EATC_DISPupdate_SysMode 2000;
BA_ "InvalidHex" SG_ 661 EATC_BlowerSpeed "$F";
BA_ "VNASignalName" SG_ 661 EATC_BlowerSpeed "EATC_BlowerSpeedI";
BA_ "GenSigSendType" SG_ 661 EATC_BlowerSpeed 3;
BA_ "GenSigTimeoutTime_MFD" SG_ 661 EATC_BlowerSpeed 2000;
BA_ "VNASignalName" SG_ 661 EATC_HeatingStatus "EATC_HeatingStatusI";
BA_ "GenSigSendType" SG_ 661 EATC_HeatingStatus 3;
BA_ "GenSigTimeoutTime_MFD" SG_ 661 EATC_HeatingStatus 2000;
BA_ "InvalidHex" SG_ 661 EATC_TempCoDriverSet "$FF";
BA_ "VNASignalName" SG_ 661 EATC_TempCoDriverSet "EATC_TempCoDriverSetI";
BA_ "GenSigSendType" SG_ 661 EATC_TempCoDriverSet 3;
BA_ "GenSigTimeoutTime_MFD" SG_ 661 EATC_TempCoDriverSet 2000;
BA_ "InvalidHex" SG_ 661 EATC_TempDriverSet "$FF";
BA_ "VNASignalName" SG_ 661 EATC_TempDriverSet "EATC_TempDriverSetI";
BA_ "GenSigSendType" SG_ 661 EATC_TempDriverSet 3;
BA_ "GenSigTimeoutTime_MFD" SG_ 661 EATC_TempDriverSet 2000;
BA_ "VNASignalName" SG_ 661 EATC_SystemMode "EATC_SystemModeI";
BA_ "GenSigSendType" SG_ 661 EATC_SystemMode 3;
BA_ "GenSigTimeoutTime_MFD" SG_ 661 EATC_SystemMode 2000;
BA_ "VNASignalName" SG_ 661 EATC_ECOMode "EATC_ECOModeI";
BA_ "GenSigSendType" SG_ 661 EATC_ECOMode 3;
BA_ "GenSigTimeoutTime_MFD" SG_ 661 EATC_ECOMode 2000;
BA_ "VNASignalName" SG_ 661 EATC_AirToScreenMode "EATC_AirToScreenModeI";
BA_ "GenSigSendType" SG_ 661 EATC_AirToScreenMode 3;
BA_ "GenSigTimeoutTime_MFD" SG_ 661 EATC_AirToScreenMode 2000;
BA_ "VNASignalName" SG_ 661 EATC_AirToPanelMode "EATC_AirToPanelModeI";
BA_ "GenSigSendType" SG_ 661 EATC_AirToPanelMode 3;
BA_ "GenSigTimeoutTime_MFD" SG_ 661 EATC_AirToPanelMode 2000;
BA_ "VNASignalName" SG_ 661 EATC_AirToFloorMode "EATC_AirToFloorModeI";
BA_ "GenSigSendType" SG_ 661 EATC_AirToFloorMode 3;
BA_ "GenSigTimeoutTime_MFD" SG_ 661 EATC_AirToFloorMode 2000;
BA_ "VNASignalName" SG_ 661 EATC_MonoMode "EATC_MonoModeI";
BA_ "GenSigSendType" SG_ 661 EATC_MonoMode 3;
BA_ "GenSigTimeoutTime_MFD" SG_ 661 EATC_MonoMode 2000;
BA_ "VNASignalName" SG_ 661 EATC_AutoMode "EATC_AutoModeI";
BA_ "GenSigSendType" SG_ 661 EATC_AutoMode 3;
BA_ "GenSigTimeoutTime_MFD" SG_ 661 EATC_AutoMode 2000;
BA_ "VNASignalName" SG_ 661 EATC_DefrostMode "EATC_DefrostModeI";
BA_ "GenSigSendType" SG_ 661 EATC_DefrostMode 3;
BA_ "GenSigTimeoutTime_MFD" SG_ 661 EATC_DefrostMode 2000;
BA_ "VNASignalName" SG_ 661 EATC_RecircMode "EATC_RecircModeI";
BA_ "GenSigSendType" SG_ 661 EATC_RecircMode 3;
BA_ "GenSigTimeoutTime_MFD" SG_ 661 EATC_RecircMode 2000;
BA_ "GenSigSendType" SG_ 661 EATC_DISPupdate_MonoMode 3;
BA_ "GenSigTimeoutTime_MFD" SG_ 661 EATC_DISPupdate_MonoMode 2000;
BA_ "HS3_Category" SG_ 649 Ill_BEZ_HLA 1;
BA_ "GenSigSendType" SG_ 649 Ill_BEZ_HLA 3;
BA_ "GenSigTimeoutTime_MFD" SG_ 649 Ill_BEZ_HLA 2000;
BA_ "HS3_Category" SG_ 649 Ill_BEZ_NAV 1;
BA_ "GenSigSendType" SG_ 649 Ill_BEZ_NAV 3;
BA_ "GenSigTimeoutTime_MFD" SG_ 649 Ill_BEZ_NAV 2000;
BA_ "HS3_Category" SG_ 649 Ill_BEZ_ACU 1;
BA_ "GenSigSendType" SG_ 649 Ill_BEZ_ACU 3;
BA_ "GenSigTimeoutTime_MFD" SG_ 649 Ill_BEZ_ACU 2000;
BA_ "LegacySignalName" SG_ 498 HEC_ARRquesterPriority_Rq "HEC_ARRquesterPriority_Rq";
BA_ "GenSigSendType" SG_ 498 HEC_AROperationType_Rq 3;
BA_ "LegacySignalName" SG_ 498 HEC_ARRequesterSystem_Rq "HEC_ARRequesterSystem_Rq";
BA_ "GenSigSendType" SG_ 490 HMI_SkipTrack_Rq 3;
BA_ "GenSigSendType" SG_ 489 ACU_CurrentPSName_St 3;
BA_ "GenSigSendType" SG_ 488 HMI_BTGetActDevActFeat_Rq 3;
BA_ "GenSigSendType" SG_ 488 HMI_BTDebondDevice_Rq 3;
BA_ "GenSigSendType" SG_ 488 HMI_BTSetActFeatDevInd_Rq 3;
BA_ "GenSigSendType" SG_ 488 HMI_PhMicrophoneMute_Rq 3;
BA_ "GenSigSendType" SG_ 488 HMI_SubscribeStInfo_Rq 3;
BA_ "GenSigSendType" SG_ 488 HMI_SetBlutoothMode_Rq 3;
BA_ "GenSigSendType" SG_ 488 HMI_SetIncCallOption_Rq 3;
BA_ "GenSigSendType" SG_ 488 HMI_PhonesSts_Rq 3;
BA_ "GenSigSendType" SG_ 488 HMI_BTIncomingCall_Rq 3;
BA_ "GenSigSendType" SG_ 488 HMI_BTEndTelService_Rq 3;
BA_ "GenSigSendType" SG_ 488 HMI_BTSendDTMFTone_Rq 3;
BA_ "LegacySignalName" SG_ 486 ACU_ARRequesterSystem_Rsp "ACU_ARRequesterSystem_Rsp";
BA_ "GenSigSendType" SG_ 486 ACU_ARResponse_Rsp 1;
BA_ "LegacySignalName" SG_ 486 ACU_ARRquesterPriority_Rp "ACU_ARRquesterPriority_Rp";
BA_ "LegacySignalName" SG_ 486 ACU_RURequesterSystem_St "ACU_RURequesterSystem_St";
BA_ "LegacySignalName" SG_ 486 ACU_RUResRequestStatus_St "ACU_RUResRequestStatus_St";
BA_ "LegacySignalName" SG_ 486 ACU_RURquesterPriority_St "ACU_RURquesterPriority_St";
BA_ "LegacySignalName" SG_ 469 VRM_ARRquesterPriority_Rq "VRM_ARRquesterPriority_Rq";
BA_ "GenSigSendType" SG_ 469 VRM_AROperationType_Rq 3;
BA_ "LegacySignalName" SG_ 469 VRM_ARRequesterSystem_Rq "VRM_ARRequesterSystem_Rq";
BA_ "GenSigSendType" SG_ 144 SetTimeFormat 3;
BA_ "InvalidHex" SG_ 144 SetYear "$FF";
BA_ "InvalidHex" SG_ 144 SetMonth "$FF";
BA_ "InvalidHex" SG_ 144 SetDay "$FF";
BA_ "InvalidHex" SG_ 144 SetHour "$FF";
BA_ "InvalidHex" SG_ 144 SetMinute "$FF";
BA_ "InvalidHex" SG_ 144 SetSecond "$FF";
BA_ "GenSigSendType" SG_ 144 TimeAdjustRequest 3;
BA_ "GenSigSendType" SG_ 144 DateAdjustRequest 3;
BA_ "InvalidHex" SG_ 128 HEC_Second "$FF";
BA_ "GenSigSendType" SG_ 128 HEC_Second 3;
BA_ "InvalidHex" SG_ 128 HEC_Minute "$FF";
BA_ "InvalidHex" SG_ 128 HEC_Hour "$FF";
BA_ "InvalidHex" SG_ 128 HEC_Day "$FF";
BA_ "InvalidHex" SG_ 128 HEC_Month "$FF";
BA_ "InvalidHex" SG_ 128 HEC_Year "$FF";
BA_ "GenSigSendType" SG_ 403 Mc_RepeatGuidance_Rq 3;
BA_ "GenSigSendType" SG_ 403 Mc_CancelRoute_Rq 3;
BA_ "GenSigSendType" SG_ 403 Mc_CancelCurrWaypt_Rq 3;
BA_ "GenSigSendType" SG_ 403 Mc_TextMessage_Rq 3;
BA_ "GenSigSendType" SG_ 403 Mc_BTInCallOptions_Rq 3;
BA_ "GenSigSendType" SG_ 403 Mc_PhMicrophoneMute_Rq 3;
BA_ "GenSigSendType" SG_ 403 Mc_LangSel_Rq 3;
BA_ "GenSigSendType" SG_ 547 Audio_Amp_St 3;
BA_ "GenSigSendType" SG_ 547 Chime_Alert_Chan2 3;
BA_ "GenSigSendType" SG_ 547 AHU_Chime2_Active 3;
BA_ "LegacySignalName" SG_ 547 AHU_Chime2_Not_Recognized "AHU_Chime2_Not_Recognized";
BA_ "GenSigSendType" SG_ 547 AHU_Chime2_Not_Recognized 3;
BA_ "GenSigSendType" SG_ 547 Chime_Alert_Chan 3;
BA_ "NWM-WakeupAllowed" SG_ 547 AHU_Alert_Channel1 1;
BA_ "GenSigSendType" SG_ 547 AHU_Alert_Channel1 3;
BA_ "GenSigSendType" SG_ 547 AHU_Chime_Supported 3;
BA_ "GenSigSendType" SG_ 547 AHU_Chime_Active 3;
BA_ "LegacySignalName" SG_ 547 AHU_Chime_Not_Recognized "AHU_Chime_Not_Recognized";
BA_ "GenSigSendType" SG_ 547 AHU_Chime_Not_Recognized 3;
BA_ "GenSigStartValue" SG_ 765 Btt_L_Actl 126;
BA_ "GenSigStartValue" SG_ 765 AwdRnge_D_ActlIpc 7;
BA_ "GenSigStartValue" SG_ 765 EngExhMdeQuiet_D_Rq 2;
BA_ "GenSigSendType" SG_ 765 EngExhMdeQuiet_D_Rq 3;
BA_ "GenSigSendType" SG_ 765 BrkLineLck_D_Rq 3;
BA_ "LegacySignalName" SG_ 765 Mc_VehUnitTripCoUsrSel_St "Mc_VehUnitTripCoUsrSel_St";
BA_ "GenSigSendType" SG_ 765 Mc_VehUnitTripCoUsrSel_St 3;
BA_ "GenSigSendType" SG_ 765 Mc_VehUnitTempUsrSel_St 3;
BA_ "GenSigSendType" SG_ 765 Running_Board_Cmd 3;
BA_ "GenSigSendType" SG_ 765 Mc_VehDayNightUsrSel_St 3;
BA_ "LegacySignalName" SG_ 765 Mc_VehTimeFormatUsrSel_St "Mc_VehTimeFormatUsrSel_St";
BA_ "GenSigSendType" SG_ 765 Mc_VehTimeFormatUsrSel_St 3;
BA_ "GenSigSendType" SG_ 765 Mc_VehThemeUsrSel_St 3;
BA_ "GenSigSendType" SG_ 765 Mc_VehLangUsrSel_St 3;
BA_ "HS3_Category" SG_ 648 DimmingMode_St 1;
BA_ "GenSigSendType" SG_ 648 DimmingMode_St 3;
BA_ "HS3_Category" SG_ 648 Ill_Disp_HLA 1;
BA_ "GenSigSendType" SG_ 648 Ill_Disp_HLA 3;
BA_ "GenSigTimeoutTime_MFD" SG_ 648 Ill_Disp_HLA 2000;
BA_ "HS3_Category" SG_ 648 Ill_Disp_NAV 1;
BA_ "GenSigSendType" SG_ 648 Ill_Disp_NAV 3;
BA_ "GenSigTimeoutTime_MFD" SG_ 648 Ill_Disp_NAV 2000;
BA_ "HS3_Category" SG_ 648 Ill_Disp_ACU 1;
BA_ "GenSigSendType" SG_ 648 Ill_Disp_ACU 3;
BA_ "GenSigTimeoutTime_MFD" SG_ 648 Ill_Disp_ACU 2000;
BA_ "HS3_Category" SG_ 648 IntIllumDimOvrrd 1;
BA_ "GenSigSendType" SG_ 774 Pa_RSensorDist_St 3;
BA_ "GenSigTimeoutTime_MFD" SG_ 774 Pa_RSensorDist_St 10000;
BA_ "GenSigSendType" SG_ 774 Pa_RROutSensorDist_St 3;
BA_ "GenSigTimeoutTime_MFD" SG_ 774 Pa_RROutSensorDist_St 10000;
BA_ "GenSigSendType" SG_ 774 Pa_RRInSensorDist_St 3;
BA_ "GenSigTimeoutTime_MFD" SG_ 774 Pa_RRInSensorDist_St 10000;
BA_ "GenSigSendType" SG_ 774 Pa_RLInSensorDist_St 3;
BA_ "GenSigTimeoutTime_MFD" SG_ 774 Pa_RLInSensorDist_St 10000;
BA_ "GenSigSendType" SG_ 774 Pa_RLOutSensorDist_St 3;
BA_ "GenSigTimeoutTime_MFD" SG_ 774 Pa_RLOutSensorDist_St 10000;
BA_ "HS3_Category" SG_ 775 SAPP_Status_St 1;
BA_ "GenSigSendType" SG_ 775 SAPP_Status_St 3;
BA_ "GenSigTimeoutTime_MFD" SG_ 775 SAPP_Status_St 10000;
BA_ "InvalidHex" SG_ 48 WheelSpeedReL "$7FFF";
BA_ "VNASignalName" SG_ 48 WheelSpeedReL "WheelSpeedReLI";
BA_ "GenSigSendType" SG_ 48 WheelSpeedReL 1;
BA_ "InvalidHex" SG_ 48 WheelSpeedReR "$7FFF";
BA_ "VNASignalName" SG_ 48 WheelSpeedReR "WheelSpeedReRI";
BA_ "GenSigSendType" SG_ 48 WheelSpeedReR 1;
BA_ "GenSigSendType" SG_ 673 ICI_Coding_BtnID_D 3;
BA_ "GenSigTimeoutTime_MFD" SG_ 673 ICI_Coding_BtnID_D 1000;
BA_ "GenSigSendType" SG_ 673 ICI_Coding_BtnID_C 3;
BA_ "GenSigTimeoutTime_MFD" SG_ 673 ICI_Coding_BtnID_C 1000;
BA_ "GenSigSendType" SG_ 673 ICI_Coding_BtnID_B 3;
BA_ "GenSigTimeoutTime_MFD" SG_ 673 ICI_Coding_BtnID_B 1000;
BA_ "GenSigSendType" SG_ 673 ICI_Coding_BtnID_A 3;
BA_ "GenSigTimeoutTime_MFD" SG_ 673 ICI_Coding_BtnID_A 1000;
BA_ "GenSigStartValue" SG_ 673 ICI_BtnID_D 255;
BA_ "GenSigTimeoutTime_MFD" SG_ 673 ICI_BtnID_D 1000;
BA_ "GenSigStartValue" SG_ 673 ICI_BtnID_C 255;
BA_ "GenSigTimeoutTime_MFD" SG_ 673 ICI_BtnID_C 1000;
BA_ "GenSigStartValue" SG_ 673 ICI_BtnID_B 255;
BA_ "GenSigTimeoutTime_MFD" SG_ 673 ICI_BtnID_B 1000;
BA_ "GenSigStartValue" SG_ 673 ICI_BtnID_A 255;
BA_ "GenSigTimeoutTime_MFD" SG_ 673 ICI_BtnID_A 1000;
BA_ "GenSigSendType" SG_ 483 Dsp_PACCamSelect_Rq 3;
BA_ "GenSigSendType" SG_ 483 Dsp_PACDistanceBars_Rq 3;
BA_ "GenSigSendType" SG_ 483 Dsp_PACGuidelines_Rq 3;
BA_ "GenSigSendType" SG_ 483 Dsp_PACTowBarZoom_Rq 3;
BA_ "GenSigSendType" SG_ 483 Dsp_PACSystemAct_Rq 3;
BA_ "GenSigSendType" SG_ 777 TrailerConnection_St 3;
BA_ "GenSigTimeoutTime_MFD" SG_ 777 TrailerConnection_St 10000;
BA_ "GenSigSendType" SG_ 773 Pa_FSSensorDist_St 3;
BA_ "GenSigTimeoutTime_MFD" SG_ 773 Pa_FSSensorDist_St 10000;
BA_ "GenSigSendType" SG_ 773 Pa_SLSensorDist_St 3;
BA_ "GenSigTimeoutTime_MFD" SG_ 773 Pa_SLSensorDist_St 10000;
BA_ "GenSigSendType" SG_ 773 Pa_SRSensorDist_St 3;
BA_ "GenSigTimeoutTime_MFD" SG_ 773 Pa_SRSensorDist_St 10000;
BA_ "GenSigSendType" SG_ 773 Pa_FROutSensorDist_St 3;
BA_ "GenSigTimeoutTime_MFD" SG_ 773 Pa_FROutSensorDist_St 10000;
BA_ "GenSigSendType" SG_ 773 Pa_FRInSensorDist_St 3;
BA_ "GenSigTimeoutTime_MFD" SG_ 773 Pa_FRInSensorDist_St 10000;
BA_ "GenSigSendType" SG_ 773 Pa_FLInSensorDist_St 3;
BA_ "GenSigTimeoutTime_MFD" SG_ 773 Pa_FLInSensorDist_St 10000;
BA_ "GenSigSendType" SG_ 773 Pa_FLOutSensorDist_St 3;
BA_ "GenSigTimeoutTime_MFD" SG_ 773 Pa_FLOutSensorDist_St 10000;
BA_ "GenSigSendType" SG_ 769 Pa_SensorAct_St 3;
BA_ "GenSigTimeoutTime_MFD" SG_ 769 Pa_SensorAct_St 10000;
BA_ "GenSigSendType" SG_ 448 Gw_MainVolAtt_Rq 3;
BA_ "GenSigSendType" SG_ 448 Gw_ChimeOccur_Rq 3;
BA_ "GenSigSendType" SG_ 1957 TesterPhysicalReqFCDIM 3;
BA_ "GenSigSendType" SG_ 1965 TesterPhysicalResFCDIM 3;
BA_ "InvalidHex" SG_ 511 Dsp_TUNbrOfPresets_Rq "$0";
BA_ "InvalidHex" SG_ 511 Dsp_TUStartIndex2_Rq "$0";
BA_ "GenSigSendType" SG_ 511 Dsp_TUPresetArea_Rq 3;
BA_ "GenSigSendType" SG_ 511 Dsp_SetCurrTUBand_Rq 3;
BA_ "GenSigSendType" SG_ 511 Dsp_SetCurrTUPreset_Rq 3;
BA_ "FISI_Comment_Sig" SG_ 771 TrlrLampCnnct_B_Actl "Do not use the SGW interface in 0x303! Use FGW 0x443 instead!";
BA_ "HS3_Category" SG_ 771 TrlrLampCnnct_B_Actl 4;
BA_ "GenSigSendType" SG_ 771 TrlrLampCnnct_B_Actl 3;
BA_ "FISI_Comment_Sig" SG_ 771 ApaMde_D_Stat "Do not use the SGW interface in 0x303! Use FGW 0x3AA instead!";
BA_ "HS3_Category" SG_ 771 ApaMde_D_Stat 4;
BA_ "GenSigSendType" SG_ 771 ApaMde_D_Stat 3;
BA_ "FISI_Comment_Sig" SG_ 771 ApaMde_D_Avail "Do not use the SGW interface in 0x303! Use FGW 0x3AA instead!";
BA_ "HS3_Category" SG_ 771 ApaMde_D_Avail 4;
BA_ "GenSigSendType" SG_ 771 ApaMde_D_Avail 3;
BA_ "GenSigStartValue" SG_ 771 ApaActvSd_D_Actl 1;
BA_ "FISI_Comment_Sig" SG_ 771 ApaActvSd_D_Actl "Do not use the SGW interface in 0x303! Use FGW 0x3AA instead!";
BA_ "HS3_Category" SG_ 771 ApaActvSd_D_Actl 4;
BA_ "GenSigSendType" SG_ 771 ApaActvSd_D_Actl 3;
BA_ "FISI_Comment_Sig" SG_ 771 RearDiffLckLamp_D_Rq "Do not use the SGW interface in 0x303! Use FGW 0x4A2 instead!";
BA_ "HS3_Category" SG_ 771 RearDiffLckLamp_D_Rq 4;
BA_ "GenSigSendType" SG_ 771 RearDiffLckLamp_D_Rq 3;
BA_ "GenSigSendType" SG_ 771 CamraFrntStat_D_Stat 3;
BA_ "GenSigStartValue" SG_ 771 AwdRnge_D_Actl 7;
BA_ "FISI_Comment_Sig" SG_ 771 AwdRnge_D_Actl "Do not use the SGW interface in 0x303! Use FGW 0x263 instead!";
BA_ "HS3_Category" SG_ 771 AwdRnge_D_Actl 4;
BA_ "GenSigSendType" SG_ 771 AwdRnge_D_Actl 3;
BA_ "FISI_Comment_Sig" SG_ 771 AwdOffRoadMode_D_Stats "Do not use the SGW interface in 0x303! Use FGW 0x263 instead!";
BA_ "HS3_Category" SG_ 771 AwdOffRoadMode_D_Stats 4;
BA_ "GenSigSendType" SG_ 771 AwdOffRoadMode_D_Stats 3;
BA_ "HS3_Category" SG_ 771 CamPDCGuidStat 1;
BA_ "GenSigSendType" SG_ 771 CamPDCGuidStat 3;
BA_ "GenSigSendType" SG_ 771 PAC_CamLensObs_St 3;
BA_ "GenSigTimeoutTime_MFD" SG_ 771 PAC_CamLensObs_St 10000;
BA_ "GenSigSendType" SG_ 771 PAC_CamSysFail_St 3;
BA_ "GenSigTimeoutTime_MFD" SG_ 771 PAC_CamSysFail_St 10000;
BA_ "GenSigSendType" SG_ 771 PAC_TowBarZoom_St 3;
BA_ "GenSigTimeoutTime_MFD" SG_ 771 PAC_TowBarZoom_St 10000;
BA_ "GenSigSendType" SG_ 771 PAC_Guidelines_St 3;
BA_ "GenSigTimeoutTime_MFD" SG_ 771 PAC_Guidelines_St 10000;
BA_ "GenSigSendType" SG_ 771 PAC_DistanceBars_St 3;
BA_ "GenSigTimeoutTime_MFD" SG_ 771 PAC_DistanceBars_St 10000;
BA_ "GenSigSendType" SG_ 771 PAC_Activation_St 3;
BA_ "GenSigTimeoutTime_MFD" SG_ 771 PAC_Activation_St 10000;
BA_ "FISI_Comment_Sig" SG_ 771 CamraOvrlTow_D_Actl "*";
BA_ "HS3_Category" SG_ 771 CamraOvrlTow_D_Actl 1;
BA_ "GenSigSendType" SG_ 771 CamraOvrlTow_D_Actl 3;
BA_ "HS3_Category" SG_ 771 CamraOvrlStat_D_Actl 1;
BA_ "GenSigSendType" SG_ 771 CamraOvrlStat_D_Actl 3;
BA_ "GenSigSendType" SG_ 771 CamZoomActiveState 3;
BA_ "HS3_Category" SG_ 771 CamraZoomMan_D_Actl 1;
BA_ "GenSigSendType" SG_ 771 CamraZoomMan_D_Actl 3;
BA_ "HS3_Category" SG_ 771 CamraOvrlDyn_D_Actl 1;
BA_ "GenSigSendType" SG_ 771 CamraOvrlDyn_D_Actl 3;
BA_ "GenSigSendType" SG_ 494 AudioDrvMde_D_Rq 3;
BA_ "GenSigSendType" SG_ 494 Mc_SetCurrPreset2_Rq 3;
BA_ "InvalidHex" SG_ 494 HEC_TUNbrOfPresets_Rq "$0";
BA_ "InvalidHex" SG_ 494 HEC_TUStartIndex2_Rq "$0";
BA_ "GenSigSendType" SG_ 494 HEC_TUPresetArea_Rq 3;
BA_ "GenSigSendType" SG_ 494 HEC_SetCurrTUBand_Rq 3;
BA_ "GenSigSendType" SG_ 734 ACU_ActServiceLink_St 3;
BA_ "GenSigTimeoutTime_MFD" SG_ 734 ACU_ActServiceLink_St 10000;
BA_ "GenSigSendType" SG_ 734 ACU_CurrTUDRService2_St 3;
BA_ "GenSigTimeoutTime_MFD" SG_ 734 ACU_CurrTUDRService2_St 10000;
BA_ "GenSigTimeoutTime_MFD" SG_ 734 ACU_ComTUSIDValid_St 10000;
BA_ "InvalidHex" SG_ 734 ACU_CurrTUDABBlock_St "$3FF";
BA_ "GenSigSendType" SG_ 734 ACU_CurrTUDABBlock_St 3;
BA_ "GenSigTimeoutTime_MFD" SG_ 734 ACU_CurrTUDABBlock_St 10000;
BA_ "GenSigSendType" SG_ 734 ACU_CurrTUDRService_St 3;
BA_ "GenSigTimeoutTime_MFD" SG_ 734 ACU_CurrTUDRService_St 10000;
BA_ "GenSigSendType" SG_ 734 ACU_CurrTURadioBand_St 3;
BA_ "GenSigTimeoutTime_MFD" SG_ 734 ACU_CurrTURadioBand_St 10000;
BA_ "InvalidHex" SG_ 734 ACU_CurrTUSCIDI_St "$FFFF";
BA_ "GenSigTimeoutTime_MFD" SG_ 734 ACU_CurrTUSCIDI_St 10000;
BA_ "GenSigSendType" SG_ 734 ACU_CurrTUServiceLink_St 3;
BA_ "GenSigTimeoutTime_MFD" SG_ 734 ACU_CurrTUServiceLink_St 10000;
BA_ "GenSigSendType" SG_ 734 ACU_CurrTUSID_St 3;
BA_ "GenSigTimeoutTime_MFD" SG_ 734 ACU_CurrTUSID_St 10000;
BA_ "GenSigSendType" SG_ 492 Dsp_MPType_Rq 3;
BA_ "GenSigSendType" SG_ 495 HEC_BTIncomingCall2_Rq 3;
BA_ "GenSigSendType" SG_ 495 HEC_BTEndTelService2_Rq 3;
BA_ "GenSigSendType" SG_ 495 HEC_BTGetActDevActFeat_Rq 3;
BA_ "VNASignalName" SG_ 701 BTMP_RDISP_WORD_Rx "BTMP_RDISP_WORD_Rx_I";
BA_ "VNASignalName" SG_ 696 NAV_RDISP_WORD_Rx "NAV_RDISP_WORD_Rx_I";
BA_ "LegacySignalName" SG_ 509 Dsp_DB1SetTrkItemIndex_Rq "Dsp_DB1SetTrkItemIndex_Rq";
BA_ "GenSigSendType" SG_ 509 Dsp_DB1SetTrkItemIndex_Rq 1;
BA_ "LegacySignalName" SG_ 509 Dsp_DB1SetTrkSetFilt3_Rq "Dsp_DB1SetTrkSetFilt3_Rq";
BA_ "LegacySignalName" SG_ 509 Dsp_DB1SetTrkSetFilt2_Rq "Dsp_DB1SetTrkSetFilt2_Rq";
BA_ "LegacySignalName" SG_ 509 Dsp_DB1SetTrkSetFilt1_Rq "Dsp_DB1SetTrkSetFilt1_Rq";
BA_ "GenSigSendType" SG_ 742 ACU_ActiveTrackNum1_St 3;
BA_ "GenSigTimeoutTime_MFD" SG_ 742 ACU_ActiveTrackNum1_St 10000;
BA_ "GenSigStartValue" SG_ 72 PowerMode_UB 1;
BA_ "VNASignalName" SG_ 72 PowerMode_UB "UB_PowerModeI";
BA_ "FISI_Comment_Sig" SG_ 72 PowerMode_UB "UB";
BA_ "HS3_Category" SG_ 72 PowerMode_UB 1;
BA_ "GenSigTimeoutTime_AHU" SG_ 72 PowerMode_UB 1000;
BA_ "VNASignalName" SG_ 72 CarMode "CarModeI";
BA_ "HS3_Category" SG_ 72 CarMode 1;
BA_ "GenSigSendType" SG_ 72 CarMode 3;
BA_ "GenSigTimeoutTime_AHU" SG_ 72 CarMode 1000;
BA_ "GenSigStartValue" SG_ 72 PowerModeQF 3;
BA_ "VNASignalName" SG_ 72 PowerModeQF "PowerModeQFI";
BA_ "HS3_Category" SG_ 72 PowerModeQF 1;
BA_ "GenSigSendType" SG_ 72 PowerModeQF 3;
BA_ "GenSigTimeoutTime_AHU" SG_ 72 PowerModeQF 1000;
BA_ "NWM-WakeupAllowed" SG_ 72 PowerMode 1;
BA_ "VNASignalName" SG_ 72 PowerMode "PowerModeI";
BA_ "HS3_Category" SG_ 72 PowerMode 1;
BA_ "GenSigSendType" SG_ 72 PowerMode 3;
BA_ "GenSigTimeoutTime_AHU" SG_ 72 PowerMode 1000;
BA_ "GenSigSendType" SG_ 466 Dsp_BTAud_SetOpMode_Rq 3;
BA_ "GenSigSendType" SG_ 466 Dsp_iPod_SetOpMode_Rq 3;
BA_ "GenSigSendType" SG_ 466 Dsp_USB_SetOpMode_Rq 3;
BA_ "InvalidHex" SG_ 1235 MFD_NbrOfItems_St "$1F";
BA_ "InvalidHex" SG_ 1235 MFD_ItemNameLength_St "$0";
BA_ "GenSigTimeoutTime_AHU" SG_ 1235 MFD_ConICPConfiguration 10000;
BA_ "GenSigTimeoutTime_AHU" SG_ 1235 MFD_InfotainmentVer_St 10000;
BA_ "GenSigSendType" SG_ 502 Dsp_AudioSourceSel2_Rq 3;
BA_ "InvalidHex" SG_ 502 Dsp_NbrOfItems2_Rq "$0";
BA_ "InvalidHex" SG_ 502 Dsp_ItemNameLength2_Rq "$0";
VAL_ 857 Report_Active 3 "Unused" 2 "All_Segments_On" 1 "Testing_or_Reporting_Data" 0 "Exit_Received" ;
VAL_ 857 Pass_Temp_Units 1 "Degrees_C_Symbol_On" 0 "Blank" ;
VAL_ 857 Front_Fan_Bars_Disply 7 "Fan_Symbol__All_bars_ON" 6 "Fan_Symbol__1st_6_bars_ON" 5 "Fan_Symbol__1st_5_bars_ON" 4 "Fan_Symbol__1st_4_bars_ON" 3 "Fan_Symbol__1st_3_bars_ON" 2 "Fan_Symbol__1st_2_bars_ON" 1 "Fan_Symbol__1st_bar_ON" 0 "Fan_Symbol__All_bars_OFF" ;
VAL_ 857 Drvr_Temp_Units 1 "Degrees_F_Symbol_On" 0 "Blank" ;
VAL_ 859 Voice_Blower_Limit 1 "Request" 0 "No_Request" ;
VAL_ 859 Rear_Mode_Bttn_Status 1 "Pressed" 0 "Not_Pressed" ;
VAL_ 859 Rear_Temp_Button_Status 3 "NA" 2 "Temp_Decrease" 1 "Temp_Increase" 0 "None_Pressed" ;
VAL_ 859 Rear_Man_Temp_Bar_Stat 9 "_9" 8 "_8" 7 "_7" 6 "_6" 5 "_5" 4 "_4" 3 "_3" 2 "_2" 1 "_1" 0 "_0" ;
VAL_ 859 Rear_Man_ATC_Button_Status 3 "AUTO_Pressed" 2 "Rear_Control_Pressed" 1 "Power_Pressed" 0 "None_Pressed" ;
VAL_ 859 Rear_Fan_Button_Status 3 "NA" 2 "Fan_Decrease" 1 "Fan_Increase" 0 "None_Pressed" ;
VAL_ 859 Frt_System_Button_Stat 22 "Max_Defrost_Pressed" 21 "Frt_Cond_Seat_Cool_Press" 20 "Frt_Cond_Seat_Heat_Press" 19 "My_Temp_Pressed" 18 "Front_Power_Pressed" 17 "Rear_Defrost_Pressed" 16 "Front_Defrost_Pressed" 15 "Recirc_Pressed" 14 "Max_AC_Pressed" 13 "AUTO_Pressed" 12 "Fan_Decrement_Pressed" 11 "Fan_Increment_Pressed" 10 "Right_side_Temp_Dec_Press" 9 "Right_side_Temp_Inc_Press" 8 "Left_side_Temp_Dec_Press" 7 "Left_side_Temp_Inc_Press" 6 "Dual_Pressed" 5 "AC_Pressed" 4 "Floor_Defrost_Pressed" 3 "Floor_Pressed" 2 "Panel_Floor_Pressed" 1 "Panel_Pressed" 0 "None_Pressed" ;
VAL_ 859 Driver_Set_Temp 255 "Invalid" 254 "No_Request" ;
VAL_ 859 ConditionSt_ButtonStat 8 "Pass_Rr_Cool_Req_Pressed" 7 "Pass_Rr_Heat_Req_Pressed" 6 "Drvr_Rr_Cool_Req_Pressed" 5 "Drvr_Rr_Heat_Req_Pressed" 4 "Pass_Fr_Cool_Req_Pressed" 3 "Pass_Fr_Heat_Req_Pressed" 2 "Drvr_Fr_Cool_Req_Pressed" 1 "Drvr_Fr_Heat_Req_Pressed" 0 "None_Pressed" ;
VAL_ 859 HtdStrgWhl_Bttn_Stat 1 "Pressed" 0 "Not_Pressed" ;
VAL_ 293 ClmtCtrlSeat_SetStat_Psgr 128 "H3_High_Heat__MAX" 64 "H2_Medium_Heat" 32 "H1_Low_Heat" 16 "C3_High_Cool__MAX" 8 "C2_Medium_Cool" 4 "C1_Low_Cool" 2 "Off" ;
VAL_ 293 ClmtCtrlSeat_SetStat_Dvr 128 "H3_High_Heat__MAX" 64 "H2_Medium_Heat" 32 "H1_Low_Heat" 16 "C3_High_Cool__MAX" 8 "C2_Medium_Cool" 4 "C1_Low_Cool" 2 "Off" ;
VAL_ 1068 BSBattSOC_UB 1 "Fresh_data" 0 "Unchanged_data" ;
VAL_ 1068 Shed_T_Eng_Off_B_UB 1 "Fresh_data" 0 "Unchanged_data" ;
VAL_ 1068 Shed_Drain_Eng_Off_B_UB 1 "Fresh_data" 0 "Unchanged_data" ;
VAL_ 1068 PwPckTqRdy_B_Dsply_UB 1 "Fresh_data" 0 "Unchanged_data" ;
VAL_ 1068 BattTracWarnLamp_B_Rq_UB 1 "Fresh_data" 0 "Unchanged_data" ;
VAL_ 1068 BattTracWarnLamp_B_Rq 1 "On" 0 "Off" ;
VAL_ 1068 BattTracSrvcRqd_B_Rq_UB 1 "Fresh_data" 0 "Unchanged_data" ;
VAL_ 1068 BattTracSrvcRqd_B_Rq 1 "On" 0 "Off" ;
VAL_ 1068 BattTracSoc_Pc_Dsply_UB 1 "Fresh_data" 0 "Unchanged_data" ;
VAL_ 1068 HtrnWarnLamp_B_Dsply_UB 1 "Fresh_data" 0 "Unchanged_data" ;
VAL_ 1068 HtrnWarnLamp_B_Dsply 1 "On" 0 "Off" ;
VAL_ 1068 HtrnSrvcRqd_B_Dsply_UB 1 "Fresh_data" 0 "Unchanged_data" ;
VAL_ 1068 HtrnSrvcRqd_B_Dsply 1 "On" 0 "Off" ;
VAL_ 1068 HtrnOvrTeLamp_B_Dsply_UB 1 "Fresh_data" 0 "Unchanged_data" ;
VAL_ 1068 HtrnOvrTeLamp_B_Dsply 1 "On" 0 "Off" ;
VAL_ 1068 PwPckTqRdy_B_Dsply 1 "On" 0 "Off" ;
VAL_ 1068 Shed_T_Eng_Off_B 1 "Active" 0 "Inactive" ;
VAL_ 1068 Shed_Level_Req 5 "SHED_ENG_OFF" 4 "SOON_ENG_OFF" 3 "SHED2_CONTIN" 2 "SHED2_TRANS" 1 "SHED1" 0 "NO_SHED" 7 "Unused_2" 6 "Loads_On" ;
VAL_ 1068 Shed_Drain_Eng_Off_B 1 "Active" 0 "Inactive" ;
VAL_ 1068 Batt_Lo_SoC_B 1 "Active" 0 "Inactive" ;
VAL_ 1068 Batt_Crit_SoC_B 1 "Active" 0 "Inactive" ;
VAL_ 1068 VehDynamicsSOS 1 "Yes" 0 "No" ;
VAL_ 1068 VehDynamicsSOS_UB 1 "Fresh_data" 0 "Unchanged_data" ;
VAL_ 1068 ObjectEntrapped_UB 1 "Fresh_data" 0 "Unchanged_data" ;
VAL_ 1068 Batt_Lo_SoC_B_UB 1 "Fresh_data" 0 "Unchanged_data" ;
VAL_ 1068 ObjectEntrapped 1 "Yes" 0 "No" ;
VAL_ 1068 Shed_Level_Req_UB 1 "Fresh_data" 0 "Unchanged_data" ;
VAL_ 1068 PwSysULoFalt_D_Stat_UB 1 "Fresh_data" 0 "Unchanged_data" ;
VAL_ 1068 PwSysULoFalt_D_Stat 15 "Not_Used_6" 14 "LowBatterySOC" 13 "PSS_Shed2_Contin" 12 "Not_Used_4" 11 "Not_Used_3" 10 "Not_Used_2" 9 "BattMonitoringSensorFault" 8 "LowBattVoltDuringPwSrcOn" 7 "LowBatt2_PowerSaveMode" 6 "LowBatt1_Warning" 5 "Overvoltage" 4 "Fault_NoOutput" 3 "Fault_ReducedOutput" 2 "Fault_Nonspecific" 1 "Cluster_Proveout" 0 "No_Fault" ;
VAL_ 1068 CcStat_D_Actl_UB 1 "Fresh_data" 0 "Unchanged_data" ;
VAL_ 1068 CcStat_D_Actl 7 "Undefined_2" 6 "Undefined_1" 5 "Active" 4 "Active_Que_Assist" 3 "Standby" 2 "Standby_Denied" 1 "Denied" 0 "Off" ;
VAL_ 1068 Batt_Crit_SoC_B_UB 1 "Fresh_data" 0 "Unchanged_data" ;
VAL_ 1068 TrlrAidEnbl_D_Stat_UB 1 "Fresh_data" 0 "Unchanged_data" ;
VAL_ 1068 TrlrAidMsgTxt_D_Rq_UB 1 "Fresh_data" 0 "Unchanged_data" ;
VAL_ 1068 TrlrAidEnbl_D_Stat 7 "Faulty" 6 "NoDataExists" 5 "TbaRecalibrate" 4 "TabTadMonitor" 3 "TbaNotAvailable" 2 "TbaInactive" 1 "TbaActive" 0 "Null" ;
VAL_ 1068 TrlrAidMsgTxt_D_Rq 31 "Message31" 30 "Message30" 29 "Message29" 28 "Message28" 27 "Message27" 26 "Message26" 25 "Message25" 24 "Message24" 23 "Message23" 22 "Message22" 21 "Message21" 20 "Message20" 19 "Message19" 18 "Message18" 17 "Message17" 16 "Message16" 15 "Message15" 14 "Message14" 13 "Message13" 12 "Message12" 11 "Message11" 10 "Message10" 9 "Message9" 8 "Message8" 7 "Message7" 6 "Message6" 5 "Message5" 4 "Message4" 3 "Message3" 2 "Message2" 1 "Message1" 0 "No_Message" ;
VAL_ 757 ACU_AutoStoreResult_St 2 "No_Station_Found" 1 "Inactive" 0 "Invalid" ;
VAL_ 757 ACU_DirectTune_St 2 "Valid_Station" 1 "Invalid_Station" 0 "Invalid" ;
VAL_ 757 ACU_RadioSeekMode2_St 16 "ContAutoDown" 15 "ContAutoUp" 14 "PISeek" 13 "TpSeek" 12 "Autostore" 11 "PtySeekDown" 10 "PtySeekUp" 9 "ScanDown" 8 "ScanUp" 7 "ContManualDown" 6 "ContManualUp" 5 "ManSingleStepDown" 4 "ManSingleStepUp" 3 "AutoDown" 2 "AutoUp" 1 "SeekOff" 0 "Invalid" ;
VAL_ 757 ACU_CurrTUBand_St 13 "reserved1" 15 "reserved_last" 12 "DAB3" 11 "SAT3" 10 "SAT2" 9 "SAT1" 8 "DAB2" 7 "DAB1" 6 "Fm3" 5 "AmAst" 4 "Am" 3 "FmAst" 2 "Fm2" 1 "Fm1" 0 "Invalid" ;
VAL_ 553 Disp_LangSel_St 30 "Slovak" 29 "Arabic" 28 "Taiwanese" 27 "Mandarin_Chinese" 26 "Korean" 25 "AU_English" 24 "Japanese" 23 "Braz_Portuguese" 22 "EU_Portuguese" 21 "Finish" 20 "Norwegian" 19 "Danish" 18 "Swedish" 17 "Hungarian" 16 "Greek" 15 "Czech" 14 "Polish" 13 "Flemish" 12 "Dutch" 11 "Russian" 10 "Turkish" 9 "Mex_Spanish" 8 "EU_Spanish" 7 "Cana_French" 6 "EU_French" 5 "Italian" 4 "German" 3 "NA_English" 2 "UK_English" 1 "Unknown" 0 "Invalid" ;
VAL_ 553 Diagnostic_Operation_Rq 7 "SignalStrength" 6 "SDARSESNNumber" 5 "SpeakerWalkAround" 4 "CalibrationPartNumber" 15 "Reserved" 3 "HardwarePartNumber" 2 "SoftwarePartNumber" 1 "GetAllBackgroundDiagRq" 0 "Inactive" ;
VAL_ 553 Bezel_Diag_Module_Rq 15 "Reserved" 3 "EFP" 2 "DSP_AMP" 1 "AHU" 0 "Inactive" ;
VAL_ 553 Audio_Demo_CMND 2 "On" 1 "Off" 0 "Inactive" ;
VAL_ 553 Surround_Sound_Upmix 2 "Surround" 1 "Stereo" 0 "Inactive" ;
VAL_ 553 Bezel_Diag_State_Rq 1 "Active" 0 "Inactive" ;
VAL_ 553 SurndSndUpmix2_D_Rq 4 "Audience" 3 "On_Stage" 2 "Surround" 1 "Stereo" 0 "Inactive" ;
VAL_ 257 MFD_SetTagMode 2 "On" 1 "Off" 0 "Inactive" ;
VAL_ 257 MFD_SetRBDSMode 2 "On" 1 "Off" 0 "Inactive" ;
VAL_ 257 MFD_SetHDModeRq 2 "On" 1 "Off" 0 "Inactive" ;
VAL_ 257 MFD_GetTagInfo 0 "Inactive" 1 "Tag_Information" ;
VAL_ 546 Alert_Chan 2 "Initialize_for_Prompts" 1 "Mute" 0 "Inactive" ;
VAL_ 546 Audible_Beep 1 "Active" 0 "Inactive" ;
VAL_ 546 SYNC_New_Attn_Event 1 "Active" 0 "Inactive" ;
VAL_ 546 SYNC_Attn_Info_Audio 7 "Unknown" 6 "Attenuation_6" 5 "Attenuation_5" 4 "Attenuation_4" 3 "Attenuation_3" 2 "Attenuation_2" 1 "Attenuation_1" 0 "Inactive" ;
VAL_ 546 Prompt_Directionality 3 "RearSpeakers" 2 "FrontSpeakers" 1 "ALL" 0 "Inactive" ;
VAL_ 549 IPC_MyKeyVolLimit_St 0 "Invalid" 1 "Off" 2 "On" ;
VAL_ 549 BeltminderAudioMute 0 "Invalid" 1 "Off" 2 "On" ;
VAL_ 549 IPC_New_Attn_Event 1 "Active" 0 "Inactive" ;
VAL_ 549 IPC_Attn_Info_Audio 7 "Unknown" 6 "Attenuation_6" 5 "Attenuation_5" 4 "Attenuation_4" 3 "Attenuation_3" 2 "Attenuation_2" 1 "Attenuation_1" 0 "Inactive" ;
VAL_ 549 Power_Up_Chime_Modules 1 "Active" 0 "Inactive" ;
VAL_ 549 Chime_Source 2 "Cluster" 1 "Infotainment_Sys" 0 "Invalid" ;
VAL_ 544 Chime_Occurence 15 "Continuous" 14 "14Repititions" 13 "13Repititions" 12 "12Repititions" 11 "11Repititions" 10 "10Repititions" 9 "9Repititions" 8 "8Repititions" 7 "7Repititions" 6 "6Repititions" 5 "5Repititions" 4 "4Repititions" 3 "3Repititions" 2 "2Repititions" 1 "PlayOnce" 0 "Inactive" ;
VAL_ 544 Chime_Time_Criticality 2 "Low" 1 "High" 0 "Inactive" ;
VAL_ 544 Chime_Directionality 3 "RearSpeakers" 2 "FrontSpeakers" 1 "ALL" 0 "Inactive" ;
VAL_ 544 Chime 63 "Chime_62" 4 "Chime_3" 3 "Chime_2" 2 "Chime_1" 1 "NoChime" 0 "Inactive" ;
VAL_ 545 AudioOccMde_D_Stat 15 "Reserved9" 14 "Reserved8" 13 "Reserved7" 12 "Reserved6" 11 "Reserved5" 10 "Reserved4" 9 "Convertible" 8 "RearSeats" 7 "FrontSeats" 6 "Reserved3" 5 "Reserved2" 4 "Reserved1" 3 "Passenger" 2 "Driver" 1 "All" 0 "Invalid" ;
VAL_ 545 AutoConfigOcc_Rear 1 "Supported" 0 "Not_Supported" ;
VAL_ 545 AutoConfigOcc_AllSeats 1 "Supported" 0 "Not_Supported" ;
VAL_ 545 AutoConfigOcc_Front 1 "Supported" 0 "Not_Supported" ;
VAL_ 545 AutoConfigOcc_Driver 1 "Supported" 0 "Not_Supported" ;
VAL_ 545 DSP_MyKeyVolLimitUp_St 2 "NotUpdated" 1 "Updated" 0 "Invalid" ;
VAL_ 545 DSP_MyKeyVolLim_St 0 "Invalid" 1 "Off" 2 "On" ;
VAL_ 545 DSP_BeltminderAudio_St 0 "Invalid" 1 "Off" 2 "On" ;
VAL_ 545 DSP_Bezel_Diag_St 15 "Reserved" 4 "SpeakerWalkAround" 3 "CalibrationPartNumber" 2 "HardwarePartNumber" 1 "SoftwarePartNumber" 0 "Inactive_NOP" ;
VAL_ 545 DSP_Sur_Sound_st 2 "Surround" 1 "Stereo" 0 "Inactive" ;
VAL_ 545 DSP_Audio_Volume_Up_St 1 "Update" 0 "NoUpdate" ;
VAL_ 545 SurndSndUpmix2_D_Stat 4 "Audience" 3 "On_Stage" 2 "Surround" 1 "Stereo" 0 "Inactive" ;
VAL_ 552 DSP_VoiceFBVolume_Up 1 "Update" 0 "NoUpdate" ;
VAL_ 552 DSP_TAVolume_Up 1 "Update" 0 "NoUpdate" ;
VAL_ 552 DSP_PhoneVolume_Up 1 "Update" 0 "NoUpdate" ;
VAL_ 552 DSP_NavCmdVolume_Up 1 "Update" 0 "NoUpdate" ;
VAL_ 552 DSP_DSPProgram_St 7 "Reserved2" 6 "Reserved1" 5 "Voice" 4 "Rock" 0 "Invalid" 1 "Normal" 2 "Pop" 3 "Classical" ;
VAL_ 552 DSP_DSP_St 0 "Invalid" 1 "All" 2 "Driver" 3 "Passenger" 4 "Pop" 5 "Classical" 6 "Rock" ;
VAL_ 552 DSP_Shaker_St 1 "Active" 0 "Inactive" ;
VAL_ 552 Audio_Demo_Status 1 "Active" 0 "Inactive" ;
VAL_ 548 DSP_AHU_ChmTstTone_Rq 1 "Active" 0 "Inactive" ;
VAL_ 548 DSP_ChimeChanState_St 7 "Reserved4" 6 "Reserved3" 5 "Reserved2" 4 "Reserved" 3 "Busy" 2 "Ready" 1 "Muted" 0 "Invalid" ;
VAL_ 548 DSP_Chime2_Not_Recognized 0 "Inactive" 1 "Chime_Not_Recognized" ;
VAL_ 548 DSP_Chime_Not_Recognized 0 "Inactive" 1 "Chime_Not_Recognized" ;
VAL_ 548 DSP_Alert_Channel3 3 "Reserved" 2 "Muted" 1 "Initialized_for_Prompts" 0 "Inactive" ;
VAL_ 548 DSP_Alert_Channel2 3 "Initialized_for_chimes" 2 "Muted" 1 "Reserved" 0 "Inactive" ;
VAL_ 548 DSP_Alert_Channel1 3 "Initialized_for_chimes" 2 "Muted" 1 "Reserved" 0 "Inactive" ;
VAL_ 548 DSP_Chimes_Supported 2 "Not_Supported" 1 "Supported" 0 "Inactive" ;
VAL_ 1000 AHU_Bezel_Diag_St 15 "Reserved" 6 "SignalStrength" 5 "SDARSESNNumber" 4 "SpeakerWalkAround" 3 "CalibrationPartNumber" 2 "HardwarePartNumber" 1 "SoftwarePartNumber" 0 "Inactive_NOP" ;
VAL_ 1000 MyKeyVolumeLimitMode 0 "Invalid" 1 "Off" 2 "On" ;
VAL_ 1000 MyKeyVolumeLimitUp 2 "NotUpdated" 1 "Updated" 0 "Invalid" ;
VAL_ 1000 ACM_BeltminderAudioSt 0 "Invalid" 1 "Off" 2 "On" ;
VAL_ 1000 AHU_Shaker_St 1 "Active" 0 "Inactive" ;
VAL_ 550 Band9 15 "Reserved1" 9 "Reserved" 8 "Amplitude_8" 7 "Amplitude_7" 6 "Amplitude_6" 4 "Amplitude_4" 2 "Amplitude_2" 5 "Amplitude_5" 3 "Amplitude_3" 1 "Amplitude_1" 0 "Amplitude_0" ;
VAL_ 550 Band8 15 "Reserved1" 9 "Reserved" 8 "Amplitude_8" 7 "Amplitude_7" 6 "Amplitude_6" 4 "Amplitude_4" 2 "Amplitude_2" 5 "Amplitude_5" 3 "Amplitude_3" 1 "Amplitude_1" 0 "Amplitude_0" ;
VAL_ 550 Band7 15 "Reserved1" 9 "Reserved" 8 "Amplitude_8" 7 "Amplitude_7" 6 "Amplitude_6" 4 "Amplitude_4" 2 "Amplitude_2" 5 "Amplitude_5" 3 "Amplitude_3" 1 "Amplitude_1" 0 "Amplitude_0" ;
VAL_ 550 Band6 15 "Reserved1" 9 "Reserved" 8 "Amplitude_8" 7 "Amplitude_7" 6 "Amplitude_6" 4 "Amplitude_4" 2 "Amplitude_2" 5 "Amplitude_5" 3 "Amplitude_3" 1 "Amplitude_1" 0 "Amplitude_0" ;
VAL_ 550 Band5 15 "Reserved1" 9 "Reserved" 8 "Amplitude_8" 7 "Amplitude_7" 6 "Amplitude_6" 4 "Amplitude_4" 2 "Amplitude_2" 5 "Amplitude_5" 3 "Amplitude_3" 1 "Amplitude_1" 0 "Amplitude_0" ;
VAL_ 550 Band4 15 "Reserved1" 9 "Reserved" 8 "Amplitude_8" 7 "Amplitude_7" 6 "Amplitude_6" 4 "Amplitude_4" 2 "Amplitude_2" 5 "Amplitude_5" 3 "Amplitude_3" 1 "Amplitude_1" 0 "Amplitude_0" ;
VAL_ 550 Band3 15 "Reserved1" 9 "Reserved" 8 "Amplitude_8" 7 "Amplitude_7" 6 "Amplitude_6" 4 "Amplitude_4" 2 "Amplitude_2" 5 "Amplitude_5" 3 "Amplitude_3" 1 "Amplitude_1" 0 "Amplitude_0" ;
VAL_ 550 Band2 15 "Reserved1" 9 "Reserved" 8 "Amplitude_8" 7 "Amplitude_7" 6 "Amplitude_6" 4 "Amplitude_4" 2 "Amplitude_2" 5 "Amplitude_5" 3 "Amplitude_3" 1 "Amplitude_1" 0 "Amplitude_0" ;
VAL_ 550 Band1 15 "Inactive" 9 "Reserved" 8 "Amplitude_8" 7 "Amplitude_7" 6 "Amplitude_6" 4 "Amplitude_4" 2 "Amplitude_2" 5 "Amplitude_5" 3 "Amplitude_3" 1 "Amplitude_1" 0 "Amplitude_0" ;
VAL_ 500 Dsp_GetCDTOCDData_Rq 0 "Inactive" 2 "Off" 1 "TOC" ;
VAL_ 500 Dsp_AudioSourceSel_Rq 5 "SDCard" 4 "Reserved" 3 "USB" 2 "BTAudio" 1 "CD" 0 "Inactive" ;
VAL_ 500 Dsp_CutItem_Rq 3 "Inactive" 2 "ThreeQuarterFromTheBeginningOneQ" 1 "End" 0 "Beginning" ;
VAL_ 501 Dsp_FreezeFMSL_Rq 2 "True" 1 "False" 0 "Inactive" ;
VAL_ 501 Dsp_SetRadSeekMode_Rq 15 "Reseved" 14 "ContAutoDown" 0 "Inactive" 1 "SeekOff" 2 "AutoUp" 3 "AutoDown" 4 "ManSingleStepUp" 5 "ManSingleStepDown" 6 "ContManualUp" 7 "ContManualDown" 8 "ScanUp" 9 "ScanDown" 10 "PtySeekUp" 11 "PtySeekDown" 12 "Autostore" 13 "ContAutoUp" ;
VAL_ 503 Dsp_AudioSourceSel3_Rq 3 "USB" 2 "BTAudio" 1 "CD" 0 "Inactive" ;
VAL_ 401 Disp_VehUnitTripCoUsrSel 3 "Inactive" 1 "Imperial" 0 "Metric" ;
VAL_ 401 Disp_VehUnitTempUsrSel 3 "Inactive" 1 "Fahrenheit" 0 "Celsius" ;
VAL_ 401 Disp_LangSel_Rq 30 "Slovak" 29 "Arabic" 28 "Taiwanese" 27 "Mandarin_Chinese" 26 "Korean" 25 "AU_English" 24 "Japanese" 23 "Braz_Portuguese" 22 "EU_Portuguese" 21 "Finish" 20 "Norwegian" 19 "Danish" 18 "Swedish" 17 "Hungarian" 16 "Greek" 15 "Czech" 14 "Polish" 13 "Flemish" 12 "Dutch" 11 "Russian" 10 "Turkish" 9 "Mex_Spanish" 8 "EU_Spanish" 7 "Cana_French" 6 "EU_French" 5 "Italian" 4 "German" 3 "NA_English" 2 "UK_English" 1 "Unknown" 0 "Invalid" ;
VAL_ 400 Mc_PerTUPresetArea_Rq 13 "reserved" 12 "GetSAT3PresetData" 11 "GetSAT2PresetData" 15 "reserved_last" 10 "GetSAT1PresetData" 9 "GetDAB2PresetData" 8 "GetDAB1PresetData" 7 "GetDAB3PresetData" 6 "GetAmPresetData" 5 "GetAmAstPresetData" 4 "GetFmAstPresetData" 3 "GetFm3PresetData" 2 "GetFm2PresetData" 1 "GetFm1PresetData" 0 "Inactive" ;
VAL_ 400 Mc_SetCurrStatMCCh_Rq 7 "MCChannel7" 6 "MCChannel6" 5 "MCChannel5" 4 "MCChannel4" 3 "MCChannel3" 2 "MCChannel2" 1 "MCChannel1" 0 "Inactive" ;
VAL_ 400 Mc_SetCurrentStatOp_Rq 0 "Inactive" 1 "SetCurrentFrequency" 2 "SetCurrentPiCode" 3 "SetCurrentStation" ;
VAL_ 756 Chime_Time_Criticality2 2 "Low" 1 "High" 0 "Inactive" ;
VAL_ 756 Chime_Occurence2 15 "Continuous" 14 "14Repititions" 13 "13Repititions" 12 "12Repititions" 11 "11Repititions" 10 "10Repititions" 9 "9Repititions" 8 "8Repititions" 7 "7Repititions" 6 "6Repititions" 5 "5Repititions" 4 "4Repititions" 3 "3Repititions" 2 "2Repititions" 1 "PlayOnce" 0 "Inactive" ;
VAL_ 756 Chime_Directionality2 3 "RearSpeakers" 2 "FrontSpeakers" 1 "ALL" 0 "Inactive" ;
VAL_ 756 Chime2 63 "Chime_62" 4 "Chime_3" 3 "Chime_2" 2 "Chime_1" 1 "NoChime" 0 "Inactive" ;
VAL_ 477 NAV_LoadEjectMode_Rq 0 "Inactive" 1 "Load" 2 "Eject" 3 "EndloadMode" ;
VAL_ 477 NAV_LoadEjectDisc_Rq 0 "Inactive" 1 "Disc1" 2 "Disc2" 3 "Disc3" 4 "Disc4" 5 "Disc5" 6 "Disc6" 7 "All" ;
VAL_ 476 NAV_SetDSPProgram_Rq 7 "Reserved2" 6 "Reserved1" 5 "Voice" 4 "Rock" 0 "Inactive" 1 "Normal" 2 "Pop" 3 "Classical" ;
VAL_ 476 NAV_SkipCatalouge_Rq 0 "Inactive" 1 "NextCatalouge" 2 "PerviousCatalouge" ;
VAL_ 476 NAV_SetOperationMode_Rq 7 "FastRewind20" 6 "FastRewind10" 5 "FastForward20" 4 "FastForward10" 3 "Pause" 2 "Play" 1 "Stop" 0 "Inactive" ;
VAL_ 476 Nav_SetAudioMixRatio_Rq 31 "Inactive" ;
VAL_ 474 NAV_SetNEWSMode_Rq 0 "Inactive" 1 "NewsOn" 2 "NewsOff" ;
VAL_ 474 NAV_SetDSP_Rq 9 "Convertible" 8 "RearSeats" 7 "FrontSeats" 6 "Reserved3" 5 "Reserved2" 4 "Reserved1" 15 "Reserved" 0 "Inactive" 1 "All" 2 "Driver" 3 "Passenger" ;
VAL_ 474 NAV_ARRquesterPriority_Rq 0 "EmergencyServ" 1 "TelService" 2 "AutoAnswer" 3 "Ta" 4 "PttMutevoice" 5 "NavUserVoiceCmd" 6 "NavSysVoiceCmd" 7 "Radio" 8 "Disc" 9 "Alarm" 10 "Ptynews" 11 "Aux_ExtSource" 12 "BT_BTNavAndTelMute" 13 "ManualAudioMute" 14 "NotReq" ;
VAL_ 474 NAV_ARRequesterSystem_Rq 0 "FrontRequester" 1 "RearRequester" ;
VAL_ 474 NAV_AROperationType_Rq 0 "Inactive" 1 "Requestaudioresource" 2 "Releaseaudioresource" 3 "Releaseallaudioresouces" 4 "Getresourceupdate" 5 "Getallresourceupdates" ;
VAL_ 474 NAV_ARAudioSource_Rq 15 "iPod" 14 "USB" 13 "BTAudio" 0 "AmfmRadio" 1 "FrontDisc" 2 "SDARS_DAB" 3 "InDashCdChanger" 4 "VoiceRecogniser" 5 "TelematicUnit" 6 "BluetoothPhone" 7 "RearDisc" 8 "APIM" 9 "FrontAuxInput" 10 "Navigation" 11 "RearAux" 12 "NotReq" ;
VAL_ 474 Nav_SetCurrStatMCCh_Rq 7 "MCChannel7" 6 "MCChannel6" 5 "MCChannel5" 4 "MCChannel4" 3 "MCChannel3" 2 "MCChannel2" 1 "MCChannel1" 0 "Inactive" ;
VAL_ 474 NAV_SetCurrentStatOp_Rq 0 "Inactive" 1 "SetCurrentFrequency" 2 "SetCurrentPiCode" 3 "SetCurrentStation" ;
VAL_ 473 NAV_SetTUServiceLink_Rq 3 "reserved" 2 "Inactive" 1 "Active" 0 "Invalid" ;
VAL_ 473 NAV_StorePreset_Rq 10 "Preset10" 9 "Preset9" 8 "Preset8" 7 "Preset7" 0 "Inactive" 1 "Preset1" 2 "Preset2" 3 "Preset3" 4 "Preset4" 5 "Preset5" 6 "Preset6" ;
VAL_ 473 NAV_SetTAMode_Rq 0 "Inactive" 1 "TaLocalOn" 2 "TaDistantOn" 3 "TaOff" ;
VAL_ 473 NAV_SetReg_Rq 2 "On" 1 "Off" 0 "Inactive" ;
VAL_ 473 NAV_SetAFMode_Rq 0 "Inactive" 1 "AfOn" 2 "AfOff" 3 "Auto" ;
VAL_ 473 NAV_SelectPTYCodesSet_Rq 0 "Inactive" 1 "SetCode" ;
VAL_ 473 NAV_CDSetShuffle_Rq 0 "Inactive" 1 "On" 2 "Off" 3 "OnFolder" ;
VAL_ 473 NAV_CDSetRepeat_Rq 0 "Inactive" 1 "RepeatOnTrack" 2 "Off" 3 "OnFolder" ;
VAL_ 473 NAV_CDSetIntroScan_Rq 0 "Inactive" 1 "On" 2 "Off" 3 "OnFolder" ;
VAL_ 479 DISP_SetVol_Source_Rq 5 "SetAudioVolume" 4 "SetVRvolume" 3 "SetPhoneVolume" 2 "SetPromptVolume" 1 "SetTAVolume" 0 "Inactive" ;
VAL_ 726 ACU_AFJump_St 2 "Enabled" 1 "Inhibited" 0 "NoDataExists" ;
VAL_ 726 ACU_NEWSMode_St 0 "Invalid" 1 "NewsOn" 2 "NewsOff" ;
VAL_ 726 ACU_TAMode_St 0 "Invalid" 1 "TaLocalOn" 2 "TaDistantOn" 3 "TaOff" ;
VAL_ 727 ACU_LoadEjectDisc_St 0 "Invalid" 1 "Disc1" 2 "Disc2" 3 "Disc3" 4 "Disc4" 5 "Disc5" 6 "Disc6" 7 "All" ;
VAL_ 727 ACU_LoadEjectMode_St 0 "Invalid" 1 "LoadModeInactiveDiscNumIgnored" 2 "LoadModeActiveDiscNumIgnored" 3 "PreparingToLoad" 4 "Insert" 5 "Loading" 6 "PreparingToEject" 7 "Ejecting" 8 "RemoveDisc" ;
VAL_ 119 BpedDrvAppl_D_Actl_UB 1 "Fresh_data" 0 "Unchanged_data" ;
VAL_ 119 BpedDrvAppl_D_Actl 3 "not_allowed" 2 "driver_braking" 1 "driver_not_braking" 0 "not_allow" ;
VAL_ 119 HsaStat_D_Actl_UB 1 "Fresh_data" 0 "Unchanged_data" ;
VAL_ 119 HsaStat_D_Actl 7 "Undefined" 6 "Failed" 5 "SlowRelease" 4 "FastRelease" 3 "ActiveBrakePedalReleased" 2 "ActiveBrakePedalPressed" 1 "FindingGradient" 0 "Inactive" ;
VAL_ 119 EPAS_Failure 3 "SERVICE_POWER_STEERING_NOW" 2 "SERVICE_POWER_STEERING" 1 "POWER_STRG_ASSIST_FAULT" 0 "EPAS_OK_NO_MESSAGE" ;
VAL_ 119 EPAS_Failure_UB 1 "Fresh_data" 0 "Unchanged_data" ;
VAL_ 119 SAPPStatusCoding_UB 1 "Fresh_data" 0 "Unchanged_data" ;
VAL_ 119 CcOvrrdActv_B_Actl_UB 1 "Fresh_data" 0 "Unchanged_data" ;
VAL_ 119 CcOvrrdActv_B_Actl 1 "Cruise_Overridden" 0 "Cruise_Req_Not_Overridden" ;
VAL_ 119 EngPullUpPullDown_D_Rq_UB 1 "Fresh_data" 0 "Unchanged_data" ;
VAL_ 119 EngPullUpPullDown_D_Rq 15 "Undefined_7" 14 "Undefined_6" 13 "Undefined_5" 12 "Undefined_4" 8 "Force_Pull_Down" 7 "Force_Pull_Up" 6 "PullDown_Inhibit_PullUp" 5 "Inhibit_Change" 4 "Inhibit_Pull_Up" 3 "Pull_Down" 2 "Inhibit_Pull_Down" 1 "Pull_Up" 0 "No_Request" 11 "Undefined_3" 10 "Undefined_2" 9 "Undefined_1" ;
VAL_ 119 VehYawComp_W_Actl_UB 1 "Fresh_data" 0 "Unchanged_data" ;
VAL_ 119 Veh_V_DsplyCcSet 255 "Fault" 254 "Unknown" ;
VAL_ 119 VehYawComp_W_Actl 4095 "Fault" 4094 "Unknown" ;
VAL_ 119 VehYaw_W_Rq 4095 "Fault" 4094 "Unknown" ;
VAL_ 119 Veh_V_DsplyCcSet_UB 1 "Fresh_data" 0 "Unchanged_data" ;
VAL_ 119 VehYaw_W_Rq_UB 1 "Fresh_data" 0 "Unchanged_data" ;
VAL_ 1297 HEC_NM_SleepAcknowledge 1 "Active" 0 "Inactive" ;
VAL_ 1297 HEC_NM_SleepIndication 1 "Active" 0 "Inactive" ;
VAL_ 1297 HEC_NM_Limphome 1 "Active" 0 "Inactive" ;
VAL_ 1297 HEC_NM_Ring 1 "Active" 0 "Inactive" ;
VAL_ 1297 HEC_NM_Alive 1 "Active" 0 "Inactive" ;
VAL_ 1292 ACU_NM_Alive 1 "Active" 0 "Inactive" ;
VAL_ 1292 ACU_NM_Limphome 1 "Active" 0 "Inactive" ;
VAL_ 1292 ACU_NM_Ring 1 "Active" 0 "Inactive" ;
VAL_ 1292 ACU_NM_SleepAcknowledge 1 "Active" 0 "Inactive" ;
VAL_ 1292 ACU_NM_SleepIndication 1 "Active" 0 "Inactive" ;
VAL_ 1239 HEC_CutItem_St 3 "ThreeQuarterFromTheBeginningOneQ" 2 "End" 1 "Beginning" 0 "Invalid" ;
VAL_ 1239 HEC_VehicleConfig 0 "Lhd" 1 "Rhd" 3 "Unknown" ;
VAL_ 1232 AHU_AutoConfigOcc_Shaker 1 "Supported" 0 "Not_Supported" ;
VAL_ 1232 AHU_AutoConfigOcc_Rear 1 "Supported" 0 "Not_Supported" ;
VAL_ 1232 AHU_AutoConfigOcc_Front 1 "Supported" 0 "Not_Supported" ;
VAL_ 1232 AHU_AutoConfigOcc_Driver 1 "Supported" 0 "Not_Supported" ;
VAL_ 1232 AHU_AutoConfigOcc_Convert 1 "Supported" 0 "Not_Supported" ;
VAL_ 1232 AHU_AutoConfigOcc_Allseats 1 "Supported" 0 "Not_Supported" ;
VAL_ 1232 ACU_Configuration 6 "HIN_HSRNS" 0 "Invalid" 1 "LowLevelAudio" 2 "HighLevelAudio" 3 "LowLevelNavigation" 4 "HighLevelNavigation" 5 "HIN_LSRNS" ;
VAL_ 1232 ACU_DigitalRadio_St 5 "DAB_RadioSystemWithPTY_JAP" 4 "DAB_RadioSystemWithPTY_GCC" 3 "DAB_RadioSystemWithPTY_NA" 2 "DAB_RadioSystemWithPTY_EU_AndROW" 1 "WithoutDigitalRadioSystem" 0 "Invalid" ;
VAL_ 1232 ACU_MediaPlayer_St 0 "Invalid" 1 "MusicCassettePlayer" 2 "CdSinglePlayer" 3 "CdChanger" ;
VAL_ 1232 AHU_EnsembleName_St 1 "Supported" 0 "Not_Supported" ;
VAL_ 1075 PJB_LockStatusValid 1 "Valid" 0 "Invalid" ;
VAL_ 1075 PJB_LockStatus 0 "Unknown" 1 "Centrallock" 2 "Centralunlock" 3 "Doublelock" 4 "Reserved" 5 "Driverdoorunlock" ;
VAL_ 1075 PJB_ReverseGearSwitch 0 "ReverseGearNotSelected" 1 "ReverseGearSelected" ;
VAL_ 1075 PJB_DriverDoorStatus 0 "DdClosed" 1 "DdAjar" ;
VAL_ 1075 PJB_PassengerDoorStatus 0 "PdClosed" 1 "PdAjar" ;
VAL_ 1075 PJB_LeftRearDoorStatus 0 "LrdClosed" 1 "LrdAjar" ;
VAL_ 1075 PJB_RightRearDoorStatus 0 "RrdClosed" 1 "RrdAjar" ;
VAL_ 1075 PJB_BootLidStatus 0 "TrunkClosed" 1 "TrunkAjar" ;
VAL_ 739 HMI_HMIMode_St 5 "Load_Shed_Active" 0 "Invalid" 1 "OffMode" 2 "On" 3 "Phone" 4 "Climate" ;
VAL_ 736 TextMessage_Rsp 3 "Cancelled" 2 "MessageIgnored" 1 "Listening" 0 "Invalid" ;
VAL_ 736 BTInCallOptions_St 6 "HoldModeoff" 5 "InHoldMode" 4 "InHandsFreeMode" 3 "InPrivacyMode" 2 "Joined" 1 "Switched" 0 "Inactive" ;
VAL_ 732 ACU_FunctionStatus_St 7 "RemoveDisc" 0 "Invalid" 1 "Reading" 2 "Loading" 3 "Loaded" 4 "Insert" 5 "PreparingToEject" 6 "Ejecting" ;
VAL_ 732 ACU_CurrFMSLPreset_St 255 "NoValidPreset" 0 "Invalid" ;
VAL_ 732 ACU_CurrPreset2_St 31 "NoActivePreset" 0 "Invalid" ;
VAL_ 732 ACU_StorePreset_St 31 "NotStoring" 0 "Invalid" ;
VAL_ 730 ACU_CDIntroScan_St 0 "Invalid" 1 "On" 2 "Off" 3 "OnFolder" ;
VAL_ 730 ACU_CDRepeat_St 0 "Invalid" 1 "RepeatOnTrack" 2 "Off" 3 "OnFolder" ;
VAL_ 730 ACU_CDShuffle_St 0 "Invalid" 1 "On" 2 "Off" 3 "OnFolder" ;
VAL_ 730 ACU_Coding_St 0 "Invalid" 1 "Cdda" 2 "Mp3" 3 "NonAudioCd" ;
VAL_ 730 ACU_DiscCoding_St 6 "Cdda_CDTextAvailable" 5 "MP3_DVD" 4 "DVD" 3 "NonAudioCD" 2 "Mp3" 1 "Cdda__NoCDTextAvailable" 0 "Invalid" ;
VAL_ 730 ACU_OperationMode_St 0 "Invalid" 1 "Stop" 2 "Play" 3 "Pause" 4 "FastForward3x" 5 "FastForward10x" 6 "FastRewind3x" 7 "FastRewind10x" ;
VAL_ 729 ACU_DSP_St 15 "Reserved" 9 "Convertible" 8 "RearSeats" 7 "FrontSeats" 0 "Invalid" 1 "All" 2 "Driver" 3 "Passenger" 4 "Reserved1" 5 "Reserved2" 6 "Reserved3" ;
VAL_ 729 ACU_DSPProgram_St 7 "Reserved2" 6 "Reserved1" 5 "Voice" 4 "Rock" 0 "Invalid" 1 "Normal" 2 "Pop" 3 "Classical" ;
VAL_ 729 ACU_NavCmdVolume_Up 1 "Update" 0 "NoUpdate" ;
VAL_ 729 ACU_PhoneVolume_Up 1 "Update" 0 "NoUpdate" ;
VAL_ 729 ACU_Reg_St 0 "Invalid" 1 "Off" 2 "On" ;
VAL_ 729 ACU_TAVolume_Up 1 "Update" 0 "NoUpdate" ;
VAL_ 729 ACU_VoiceFBVolume_Up 1 "Update" 0 "NoUpdate" ;
VAL_ 728 AudioDrvMde_D_Stat 7 "Faulty" 6 "Setting6" 5 "Setting5" 4 "Setting4" 3 "Setting3" 2 "Setting2" 1 "Setting1" 0 "Null" ;
VAL_ 728 ACU_CDError_St 0 "Invalid" 1 "NoError" 2 "NoDiscs" 3 "UnableToReadDisc" ;
VAL_ 728 ACU_RadioSeekMode_St 14 "PISeek" 0 "Invalid" 1 "SeekOff" 2 "AutoUp" 3 "AutoDown" 4 "ManSingleStepUp" 5 "ManSingleStepDown" 6 "ContManualUp" 7 "ContManualDown" 8 "ScanUp" 9 "ScanDown" 10 "PtySeekUp" 11 "PtySeekDown" 12 "Autostore" 13 "TpSeek" ;
VAL_ 728 ACU_Volume_Up 1 "Update" 0 "NoUpdate" ;
VAL_ 725 ACU_CompLogic_St 0 "Invalid" 1 "Off" 2 "On" ;
VAL_ 725 ACU_RadioError_St 0 "Invalid" 1 "NoError" 2 "PiNotFound" 3 "PtyNotFound" ;
VAL_ 725 ACU_HardwareError_St 0 "Invalid" 1 "NoError" 2 "EepromReadError" 3 "KeycodeLocked" 4 "KeycodeLockedForever" 5 "CommunicationError" 6 "OverTemperature" 7 "FocusError" ;
VAL_ 725 ACU_AFMode_St 0 "Invalid" 1 "AfOn" 2 "AfOff" 3 "Auto" ;
VAL_ 661 EATC_DISPupdate_Defrost 1 "HasRecentlyChanged" 0 "NoChange" ;
VAL_ 661 EATC_DISPupdate_MAXAC 1 "HasRecentlyChanged" 0 "NoChange" ;
VAL_ 661 EATC_MAXACMode 1 "Active" 0 "Inactive" ;
VAL_ 661 EATC_DISPupdate_AutoMode 1 "HasRecentlyChanged" 0 "NoChange" ;
VAL_ 661 EATC_DISPupdate_ACMode 1 "HasRecentlyChanged" 0 "NoChange" ;
VAL_ 661 EATC_DISPupdate_AirMode 1 "HasRecentlyChanged" 0 "NoChange" ;
VAL_ 661 EATC_DISPupdate_BlowerSpd 1 "HasRecentlyChanged" 0 "NoChange" ;
VAL_ 661 EATC_DISPupdate_TempCoDr 1 "HasRecentlyChanged" 0 "NoChange" ;
VAL_ 661 EATC_DISPupdate_TempDr 1 "HasRecentlyChanged" 0 "NoChange" ;
VAL_ 661 EATC_DISPupdate_SysMode 1 "HasRecentlyChanged" 0 "NoChange" ;
VAL_ 661 EATC_HeatingStatus 0 "Inactive" 1 "MaxCooling" 2 "Cooling" 3 "MinCooling" 4 "AirflowOnly" 5 "MinHeating" 6 "Heating" 7 "MaxHeating" ;
VAL_ 661 EATC_SystemMode 1 "Active" 0 "Inactive" ;
VAL_ 661 EATC_ECOMode 1 "Active" 0 "Inactive" ;
VAL_ 661 EATC_AirToScreenMode 1 "Active" 0 "Inactive" ;
VAL_ 661 EATC_AirToPanelMode 1 "Active" 0 "Inactive" ;
VAL_ 661 EATC_AirToFloorMode 1 "Active" 0 "Inactive" ;
VAL_ 661 EATC_MonoMode 1 "Active" 0 "Inactive" ;
VAL_ 661 EATC_AutoMode 1 "Active" 0 "Inactive" ;
VAL_ 661 EATC_DefrostMode 1 "Active" 0 "Inactive" ;
VAL_ 661 EATC_RecircMode 1 "Active" 0 "Inactive" ;
VAL_ 661 EATC_DISPupdate_MonoMode 1 "HasRecentlyChanged" 0 "NoChange" ;
VAL_ 649 Ill_BEZ_HLA 0 "Off" ;
VAL_ 649 Ill_BEZ_NAV 0 "Off" ;
VAL_ 649 Ill_BEZ_ACU 0 "Off" ;
VAL_ 498 HEC_ARRquesterPriority_Rq 0 "EmergencyServ" 1 "TelService" 2 "AutoAnswer" 3 "Ta" 4 "PttMutevoice" 5 "NavUserVoiceCmd" 6 "NavSysVoiceCmd" 7 "Radio" 8 "Disc" 9 "Alarm" 10 "Ptynews" 11 "Aux_ExtSource" 12 "BT_BTNavAndTelMute" 13 "ManualAudioMute" 14 "NotReq" ;
VAL_ 498 HEC_AROperationType_Rq 0 "Inactive" 1 "Requestaudioresource" 2 "Releaseaudioresource" 3 "Releaseallaudioresouces" 4 "Getresourceupdate" 5 "Getallresourceupdates" ;
VAL_ 498 HEC_ARRequesterSystem_Rq 0 "FrontRequester" 1 "RearRequester" ;
VAL_ 498 HEC_ARAudioSource_Rq 15 "iPod" 14 "USB" 13 "BTAudio" 0 "AmfmRadio" 1 "FrontDisc" 2 "SDARS_DAB" 3 "InDashCdChanger" 4 "VoiceRecogniser" 5 "TelematicUnit" 6 "BluetoothPhone" 7 "RearDisc" 8 "APIM" 9 "FrontAuxInput" 10 "Navigation" 11 "RearAux" 12 "NotReq" ;
VAL_ 490 HMI_SkipTrack_Rq 2 "Decrement" 1 "Increment" 0 "Inactive" ;
VAL_ 488 HMI_BTGetActDevActFeat_Rq 1 "Getstatus" 0 "Inactive" ;
VAL_ 488 HMI_BTDebondDevice_Rq 15 "BTDeviceIndex15" 14 "BTDeviceIndex14" 13 "BTDeviceIndex13" 12 "BTDeviceIndex12" 11 "BTDeviceIndex11" 10 "BTDeviceIndex10" 9 "BTDeviceIndex9" 8 "BTDeviceIndex8" 7 "BTDeviceIndex7" 6 "BTDeviceIndex6" 5 "BTDeviceIndex5" 4 "BTDeviceIndex4" 3 "BTDeviceIndex3" 2 "BTDeviceIndex2" 1 "BTDeviceIndex1" 0 "Inactive" ;
VAL_ 488 HMI_BTSetActFeatGroup_Rq 15 "Reserved_last" 8 "Reserved" 7 "Office" 6 "Video" 5 "Voice" 4 "MobileCom" 3 "Nav" 2 "MP" 1 "Radio" 0 "ALL" ;
VAL_ 488 HMI_BTSetActFeatDevInd_Rq 15 "BTDeviceIndex15" 14 "BTDeviceIndex14" 13 "BTDeviceIndex13" 12 "BTDeviceIndex12" 11 "BTDeviceIndex11" 10 "BTDeviceIndex10" 9 "BTDeviceIndex9" 8 "BTDeviceIndex8" 7 "BTDeviceIndex7" 6 "BTDeviceIndex6" 5 "BTDeviceIndex5" 4 "BTDeviceIndex4" 3 "BTDeviceIndex3" 2 "BTDeviceIndex2" 1 "BTDeviceIndex1" 0 "Inactive" ;
VAL_ 488 HMI_PhMicrophoneMute_Rq 3 "Reserved" 2 "MicrophoneUnmute" 1 "MicrophoneMute" 0 "Inactive" ;
VAL_ 488 HMI_SubscribeStInfo_Rq 0 "Inactive" 1 "Subscribe" 2 "Unsubscribe" ;
VAL_ 488 HMI_SetBlutoothMode_Rq 0 "Inactive" 1 "On" 2 "Off" ;
VAL_ 488 HMI_SetIncCallOption_Rq 0 "Inactive" 1 "RejectAll" 2 "AcceptIncomingCall" 3 "Silent" ;
VAL_ 488 HMI_PhonesSts_Rq 1 "Getstatus" 0 "Inactive" ;
VAL_ 488 HMI_BTIncomingCall_Rq 2 "DeclineIncomingCall" 1 "AcceptIncomingCall" 0 "Inactive" ;
VAL_ 488 HMI_BTEndTelService_Rq 1 "EndOngoingTelephonyCall" 0 "Inactive" ;
VAL_ 488 HMI_BTSendDTMFTone_Rq 0 "Inactive" 1 "Dtmf0" 2 "Dtmf1" 3 "Dtmf2" 4 "Dtmf3" 5 "Dtmf4" 6 "Dtmf5" 7 "Dtmf6" 8 "Dtmf7" 9 "Dtmf8" 10 "Dtmf9" 11 "Dtmfstar" 12 "Dtmfcross" ;
VAL_ 486 ACU_ARAudioSource_Rsp 15 "iPod" 14 "USB" 13 "BTAudio" 0 "AmfmRadio" 1 "FrontDisc" 2 "SDARS_DAB" 3 "InDashCdChanger" 4 "VoiceRecogniser" 5 "TelematicUnit" 6 "BluetoothPhone" 7 "RearDisc" 8 "APIM" 9 "FrontAuxInput" 10 "Navigation" 11 "RearAux" 12 "NotReq" ;
VAL_ 486 ACU_AROperationType_Rsp 0 "Inactive" 1 "Requestaudioresource" 2 "Releaseaudioresource" 3 "Releaseallaudioresouces" 4 "Getresourceupdate" 5 "Getallresourceupdates" ;
VAL_ 486 ACU_ARRequesterSystem_Rsp 0 "FrontRequester" 1 "RearRequester" ;
VAL_ 486 ACU_ARResponse_Rsp 0 "Inactive" 1 "RequestAccepted" 2 "RequestAcceptedWoCtrl" 3 "RequestDenied" 4 "RessourceUpdateStatus" ;
VAL_ 486 ACU_ARRquesterPriority_Rp 0 "EmergencyServ" 1 "TelService" 2 "AutoAnswer" 3 "Ta" 4 "PttMutevoice" 5 "NavUserVoiceCmd" 6 "NavSysVoiceCmd" 7 "Radio" 8 "Disc" 9 "Alarm" 10 "Ptynews" 11 "Aux_ExtSource" 12 "BT_BTNavAndTelMute" 13 "ManualAudioMute" 14 "NotReq" ;
VAL_ 486 ACU_RUAudioSource_St 15 "iPod" 14 "USB" 13 "BTAudio" 0 "AmfmRadio" 1 "FrontDisc" 2 "SDARS_DAB" 3 "InDashCdChanger" 4 "VoiceRecogniser" 5 "TelematicUnit" 6 "BluetoothPhone" 7 "RearDisc" 8 "APIM" 9 "FrontAuxInput" 10 "Navigation" 11 "RearAux" 12 "NotReq" ;
VAL_ 486 ACU_RURequesterSystem_St 0 "FrontRequester" 1 "RearRequester" ;
VAL_ 486 ACU_RUResRequestStatus_St 0 "NoResourceupdate" 1 "Deallocated" 2 "Allocated" 3 "Stacked" 4 "Granted" 5 "GrantedNoControlOfAudioSrc" ;
VAL_ 486 ACU_RURquesterPriority_St 0 "EmergencyServ" 1 "TelService" 2 "AutoAnswer" 3 "Ta" 4 "PttMutevoice" 5 "NavUserVoiceCmd" 6 "NavSysVoiceCmd" 7 "Radio" 8 "Disc" 9 "Alarm" 10 "Ptynews" 11 "Aux_ExtSource" 12 "BT_BTNavAndTelMute" 13 "ManualAudioMute" 14 "NotReq" ;
VAL_ 469 VRM_ARRquesterPriority_Rq 0 "EmergencyServ" 1 "TelService" 2 "AutoAnswer" 3 "Ta" 4 "PttMutevoice" 5 "NavUserVoiceCmd" 6 "NavSysVoiceCmd" 7 "Radio" 8 "Disc" 9 "Alarm" 10 "Ptynews" 11 "Aux_ExtSource" 12 "BT_BTNavAndTelMute" 13 "ManualAudioMute" 14 "NotReq" ;
VAL_ 469 VRM_AROperationType_Rq 0 "Inactive" 1 "Requestaudioresource" 2 "Releaseaudioresource" 3 "Releaseallaudioresouces" 4 "Getresourceupdate" 5 "Getallresourceupdates" ;
VAL_ 469 VRM_ARRequesterSystem_Rq 0 "FrontRequester" 1 "RearRequester" ;
VAL_ 469 VRM_ARAudioSource_Rq 15 "iPod" 14 "USB" 13 "BTAudio" 0 "AmfmRadio" 1 "FrontDisc" 2 "SDARS_DAB" 3 "InDashCdChanger" 4 "VoiceRecogniser" 5 "TelematicUnit" 6 "BluetoothPhone" 7 "RearDisc" 8 "APIM" 9 "FrontAuxInput" 10 "Navigation" 11 "RearAux" 12 "NotReq" ;
VAL_ 144 SetTimeFormat 2 "24h_mode" 1 "12h_mode" 0 "Inactive" ;
VAL_ 144 TimeAdjustRequest 0 "NoTimeAdjustRequest" 1 "TimeAdjustRequest" ;
VAL_ 144 DateAdjustRequest 0 "NoDateAdjustRequest" 1 "DateAdjustRequest" ;
VAL_ 128 HEC_Minute 255 "Invalid" ;
VAL_ 128 HEC_Hour 255 "Invalid" ;
VAL_ 128 HEC_Day 255 "Invalid" ;
VAL_ 128 HEC_Month 255 "invalid" ;
VAL_ 128 HEC_Year 255 "invalid" ;
VAL_ 403 Mc_RepeatGuidance_Rq 1 "Active" 0 "Inactive" ;
VAL_ 403 Mc_CancelRoute_Rq 1 "Cancel" 0 "Inactive" ;
VAL_ 403 Mc_CancelCurrWaypt_Rq 1 "Cancel" 0 "Inactive" ;
VAL_ 403 Mc_TextMessage_Rq 3 "Cancel" 2 "Ignore" 1 "Listen" 0 "Invalid" ;
VAL_ 403 Mc_BTInCallOptions_Rq 6 "EndHoldCall" 5 "HoldCall" 4 "GotoHandsfreeMode" 3 "GotoPrivacyMode" 2 "JoinCalls" 1 "SwitchCalls" 0 "Inactive" ;
VAL_ 403 Mc_PhMicrophoneMute_Rq 3 "Reserved" 2 "MicrophoneUnmute" 1 "MicrophoneMute" 0 "Inactive" ;
VAL_ 403 Mc_LangSel_Rq 30 "Slovak" 29 "Arabic" 28 "Taiwanese" 27 "Mandarin_Chinese" 26 "Korean" 25 "AU_English" 24 "Japanese" 23 "Braz_Portuguese" 22 "EU_Portuguese" 21 "Finish" 20 "Norwegian" 19 "Danish" 18 "Swedish" 17 "Hungarian" 16 "Greek" 15 "Czech" 14 "Polish" 13 "Flemish" 12 "Dutch" 11 "Russian" 10 "Turkish" 9 "Mex_Spanish" 8 "EU_Spanish" 7 "Cana_French" 6 "EU_French" 5 "Italian" 4 "German" 3 "NA_English" 2 "UK_English" 1 "Unknown" 0 "Invalid" ;
VAL_ 547 Audio_Amp_St 3 "On" 2 "Partial_Amp" 1 "Off" 0 "NoDataExists" ;
VAL_ 547 Chime_Alert_Chan2 2 "Reserved" 1 "Mute" 0 "Inactive" ;
VAL_ 547 AHU_Chime2_Active 63 "Chime_62" 4 "Chime_3" 3 "Chime_2" 2 "Chime_1" 1 "NoChime" 0 "Inactive" ;
VAL_ 547 AHU_Chime2_Not_Recognized 0 "Inactive" 1 "Chime_Not_Recognized" ;
VAL_ 547 Chime_Alert_Chan 2 "Reserved" 1 "Mute" 0 "Inactive" ;
VAL_ 547 AHU_Alert_Channel1 3 "Reserved" 2 "Muted" 1 "Initialize_for_prompt" 0 "Inactive" ;
VAL_ 547 AHU_Chime_Supported 2 "Not_Supported" 1 "Supported" 0 "Inactive" ;
VAL_ 547 AHU_Chime_Active 63 "Chime_62" 4 "Chime_3" 3 "Chime_2" 2 "Chime_1" 1 "NoChime" 0 "Inactive" ;
VAL_ 547 AHU_Chime_Not_Recognized 0 "Inactive" 1 "Chime_Not_Recognized" ;
VAL_ 765 BttOn_B_Rq 1 "On" 0 "Off" ;
VAL_ 765 Btt_L_Actl 127 "Faulty" 126 "NoDataExists" ;
VAL_ 765 AirSusp_D_RqDrv 3 "NotUsed" 2 "On" 1 "Off" 0 "NoModeSelected" ;
VAL_ 765 AwdRnge_D_ActlIpc 7 "Unknown" 6 "High_Range_2wd" 5 "High_Range_Auto" 4 "High_Range_Locked" 3 "Neutral" 2 "Low_Range_2wd" 1 "Low_Range_Auto" 0 "Low_Range_Locked" ;
VAL_ 765 EngExhMdeQuiet_D_Rq 3 "Faulty" 2 "QuietExhaust" 1 "LoudExhaust" 0 "Null" ;
VAL_ 765 BrkLineLck_D_Rq 3 "Off" 2 "Engage" 1 "Initiate" 0 "NoRequest" ;
VAL_ 765 Mc_VehUnitTripCoUsrSel_St 0 "TripComputer_metric" 1 "TripComputer_imperial" ;
VAL_ 765 Mc_VehUnitTempUsrSel_St 0 "Temperature_deg_c" 1 "Temperature_deg_f" ;
VAL_ 765 Running_Board_Cmd 3 "Unused" 2 "Manually_Deployed" 1 "All_Enabled" 0 "All_Disabled" ;
VAL_ 765 Mc_VehDayNightUsrSel_St 2 "Night" 1 "Day" 0 "Invalid" ;
VAL_ 765 Mc_VehTimeFormatUsrSel_St 2 "24h_mode" 1 "12h_mode" 0 "Invalid" ;
VAL_ 765 Mc_VehThemeUsrSel_St 2 "Theme_2" 1 "Theme_1" 0 "Invalid" ;
VAL_ 765 Mc_VehLangUsrSel_St 30 "Slovak" 29 "Arabic" 28 "Taiwanese" 27 "Mandarin_Chinese" 26 "Korean" 25 "AU_English" 24 "Japanese" 23 "Braz_Portuguese" 22 "EU_Portuguese" 21 "Finish" 20 "Norwegian" 19 "Danish" 18 "Swedish" 17 "Hungarian" 16 "Greek" 15 "Czech" 14 "Polish" 13 "Flemish" 12 "Dutch" 11 "Russian" 10 "Turkish" 9 "Mex_Spanish" 8 "EU_Spanish" 7 "Cana_French" 6 "EU_French" 5 "Italian" 4 "German" 3 "NA_English" 2 "UK_English" 1 "Unknown" 0 "Invalid" ;
VAL_ 648 DimmingMode_St 3 "DisplayMaxBrightSet" 2 "AutoDimmingModeSet" 1 "ManualDimmingModeSet" 0 "NoDataExist" ;
VAL_ 648 Ill_Disp_HLA 0 "Off" ;
VAL_ 648 Ill_Disp_NAV 0 "Off" ;
VAL_ 648 Ill_Disp_ACU 0 "Off" ;
VAL_ 648 IntIllumDimOvrrd 3 "Off" 2 "SearchMode" 1 "StealthMode" 0 "Invalid" ;
VAL_ 774 Pa_RSensorDist_St 1 "SensorDistDataValid" 0 "Invalid" ;
VAL_ 673 ICI_Coding_BtnID_D 15 "Idle" 5 "Stuck" 4 "LongEvent" 3 "ShortElapsed" 2 "ShortEvent" 1 "Active" 0 "Inactive" ;
VAL_ 673 ICI_Coding_BtnID_C 15 "Idle" 5 "Stuck" 4 "LongEvent" 3 "ShortElapsed" 2 "ShortEvent" 1 "Active" 0 "Inactive" ;
VAL_ 673 ICI_Coding_BtnID_B 15 "Idle" 5 "Stuck" 4 "LongEvent" 3 "ShortElapsed" 2 "ShortEvent" 1 "Active" 0 "Inactive" ;
VAL_ 673 ICI_Coding_BtnID_A 15 "Idle" 5 "Stuck" 4 "LongEvent" 3 "ShortElapsed" 2 "ShortEvent" 1 "Active" 0 "Inactive" ;
VAL_ 483 Dsp_PACCamSelect_Rq 15 "Reserved_last" 6 "Reserved4" 5 "RearViewCam" 4 "Reserved3" 3 "Reserved2" 2 "Reserved1" 1 "Reserved" 0 "Inactive" ;
VAL_ 483 Dsp_PACDistanceBars_Rq 2 "On" 1 "Off" 0 "Inactive" ;
VAL_ 483 Dsp_PACGuidelines_Rq 4 "Reserved" 3 "Towbar" 2 "Standard" 1 "Off" 0 "Inactive" ;
VAL_ 483 Dsp_PACTowBarZoom_Rq 2 "On" 1 "Off" 0 "Inactive" ;
VAL_ 483 Dsp_PACSystemAct_Rq 2 "On" 1 "Off" 0 "Inactive" ;
VAL_ 777 TrailerConnection_St 2 "TrailerConnected" 1 "NoTrailerConnected" 0 "Invalid" ;
VAL_ 773 Pa_FSSensorDist_St 1 "SensorDistDataValid" 0 "Invalid" ;
VAL_ 448 Gw_MainVolAtt_Rq 3 "Reserved" 2 "Stop" 1 "Start" 0 "Inactive" ;
VAL_ 448 Gw_ChimeMode_Rq 1 "ChimesOnly" 0 "ChimesMixMode" ;
VAL_ 448 Gw_ChimeType_Rq 1 "Sample" 0 "Sine" ;
VAL_ 448 Gw_ChimeOccur_Rq 7 "Reserved1" 6 "Quadruple" 5 "Periodic" 4 "Triple" 3 "Double" 2 "Single" 1 "Off" 0 "Inactive" ;
VAL_ 511 Dsp_TUPresetArea_Rq 13 "reserved" 12 "GetSAT3PresetData" 11 "GetSAT2PresetData" 15 "reserved_last" 10 "GetSAT1PresetData" 9 "GetDAB2PresetData" 8 "GetDAB1PresetData" 7 "GetDAB3PresetData" 6 "GetAmPresetData" 5 "GetAmAstPresetData" 4 "GetFmAstPresetData" 3 "GetFm3PresetData" 2 "GetFm2PresetData" 1 "GetFm1PresetData" 0 "Inactive" ;
VAL_ 511 Dsp_SetCurrTUBand_Rq 13 "reserved1" 12 "DAB3" 11 "SAT3" 10 "SAT2" 15 "reserved_last" 9 "SAT1" 8 "DAB2" 7 "DAB1" 6 "AmAst" 5 "Am" 4 "FmAst" 3 "Fm3" 2 "Fm2" 1 "Fm1" 0 "Inactive" ;
VAL_ 771 TrlrLampCnnct_B_Actl 1 "Yes" 0 "No" ;
VAL_ 771 ApaMde_D_Stat 7 "NotUsed3" 6 "NotUsed2" 5 "NotUsed1" 4 "POA" 3 "PPA" 2 "SAPP" 1 "Off" 0 "Null" ;
VAL_ 771 ApaMde_D_Avail 15 "NotUsed7" 14 "NotUsed6" 13 "NotUsed5" 12 "NotUsed4" 11 "NotUsed3" 10 "NotUsed2" 9 "NotUsed1" 8 "PPA_POA" 7 "SAPP_POA" 6 "POA" 5 "PPA" 4 "SAPP" 3 "SAPP_PPA_POA" 2 "SAPP_PPA" 1 "None" 0 "Null" ;
VAL_ 771 ApaActvSd_D_Actl 0 "Null" 1 "No_Side" 2 "Passenger_Side" 3 "Dirver_Side" ;
VAL_ 771 RearDiffLckLamp_D_Rq 3 "Not_Used" 2 "Flash" 1 "On" 0 "Off" ;
VAL_ 771 CamraFrntStat_D_Stat 3 "No Data Present" 2 "Undefined" 1 "On" 0 "Off" ;
VAL_ 771 AwdRnge_D_Actl 7 "Unknown" 6 "High_Range_2wd" 5 "High_Range_Auto" 4 "High_Range_Locked" 3 "Neutral" 2 "Low_Range_2wd" 1 "Low_Range_Auto" 0 "Low_Range_Locked" ;
VAL_ 771 AwdOffRoadMode_D_Stats 3 "Invalid" 2 "Extreme_Off_Road" 1 "Off_Road" 0 "Normal_Mode" ;
VAL_ 771 CamPDCGuidStat 3 "Not_Used" 2 "Inactive" 1 "Active" 0 "Invalid" ;
VAL_ 771 PAC_CamLensObs_St 21 "Reserved_last" 6 "Reserved4" 5 "RearViewCamObs" 4 "Reserved3" 3 "Reserved2" 2 "Reserved1" 1 "NoObscuration" 0 "Invalid" ;
VAL_ 771 PAC_CamSysFail_St 7 "Reserved5" 6 "Reserved4" 5 "RearViewCamFail" 4 "Reserved3" 3 "Reserved2" 2 "Reserved1" 1 "NoFailure" 0 "Invalid" ;
VAL_ 771 PAC_TowBarZoom_St 0 "Invalid" 1 "Off" 2 "On" ;
VAL_ 771 PAC_Guidelines_St 4 "Reserved" 3 "Towbar" 2 "Standard" 1 "Off" 0 "Invalid" ;
VAL_ 771 PAC_DistanceBars_St 0 "Invalid" 1 "Off" 2 "On" ;
VAL_ 771 PAC_Activation_St 7 "Reserved_last" 6 "Reserved2" 5 "Reserved1" 4 "Off_Failure" 3 "Off_SAPP" 2 "On" 1 "Off" 0 "Invalid" ;
VAL_ 771 CamraOvrlTow_D_Actl 3 "Unused" 2 "Inactive" 1 "Active" 0 "Invalid" ;
VAL_ 771 CamraOvrlStat_D_Actl 3 "Not_Used" 2 "Inactive" 1 "Active" 0 "Invalid" ;
VAL_ 771 CamZoomActiveState 3 "Not_Used" 2 "Inactive" 1 "Active" 0 "Invalid" ;
VAL_ 771 CamraZoomMan_D_Actl 7 "Unknown" 6 "Invalid" 5 "Zoom_Level_V" 4 "Zoom_Level_IV" 3 "Zoom_Level_III" 2 "Zoom_Level_II" 1 "Zoom_Level_I" 0 "Off" ;
VAL_ 771 CamraOvrlDyn_D_Actl 3 "Not_Used" 2 "Inactive" 1 "Active" 0 "Invalid" ;
VAL_ 494 AudioDrvMde_D_Rq 7 "Faulty" 6 "Setting6" 5 "Setting5" 4 "Setting4" 3 "Setting3" 2 "Setting2" 1 "Setting1" 0 "Inactive" ;
VAL_ 494 HEC_TUPresetArea_Rq 13 "reserved" 12 "GetSAT3PresetData" 11 "GetSAT2PresetData" 15 "reserved_last" 10 "GetSAT1PresetData" 9 "GetDAB2PresetData" 8 "GetDAB1PresetData" 7 "GetDAB3PresetData" 6 "GetAmPresetData" 5 "GetAmAstPresetData" 4 "GetFmAstPresetData" 3 "GetFm3PresetData" 2 "GetFm2PresetData" 1 "GetFm1PresetData" 0 "Inactive" ;
VAL_ 494 HEC_SetCurrTUBand_Rq 13 "reserved" 12 "DAB3" 11 "SAT3" 10 "SAT2" 15 "reserved_last" 9 "SAT1" 8 "DAB2" 7 "DAB1" 6 "AmAst" 5 "Am" 4 "FmAst" 3 "Fm3" 2 "Fm2" 1 "Fm1" 0 "Inactive" ;
VAL_ 734 ACU_ActServiceLink_St 3 "reserved" 2 "FM2DAB" 1 "DAB2FM" 0 "Invalid" ;
VAL_ 734 ACU_CurrTUDRService2_St 7 "last_reserved" 5 "reserved" 4 "DabNotAvailable" 3 "ServiceAvailable" 2 "ServiceNotAvailable" 1 "SyncEnsemble" 0 "Invalid" ;
VAL_ 734 ACU_ComTUSIDValid_St 1 "Validation" 0 "Invalid" ;
VAL_ 734 ACU_CurrTUDRService_St 3 "ServiceAvailable" 2 "ServiceNotAvailable" 1 "SyncEnsemble" 0 "Invalid" ;
VAL_ 734 ACU_CurrTURadioBand_St 12 "reserved" 11 "SAT3" 10 "SAT2" 15 "reserved_last" 9 "SAT1" 8 "DAB2" 7 "DAB1" 6 "Fm3" 5 "AmAst" 4 "Am" 3 "FmAst" 2 "Fm2" 1 "Fm1" 0 "Invalid" ;
VAL_ 734 ACU_CurrTUServiceLink_St 3 "reserved" 2 "Inactive" 1 "Active" 0 "Invalid" ;
VAL_ 492 Dsp_MPType_Rq 7 "Reserved3" 6 "Reserved2" 5 "Reserved1" 4 "USB" 3 "iPod" 2 "BTAudio" 1 "SDCard" 0 "Inactive" ;
VAL_ 492 Dsp_SkipFolder_Rq 2 "Decrement" 1 "Increment" 0 "Inactive" ;
VAL_ 492 Dsp_SkipTrack_Rq 2 "Decrement" 1 "Increment" 0 "Inactive" ;
VAL_ 492 Dsp_SetRepeat_Rq 7 "Reserved4" 6 "Reserved3" 5 "Reserved2" 4 "RepeatOnDevice" 3 "RepeatOnFolderSelGroup" 2 "RepeatOnTrack" 1 "Off" 0 "Inactive" ;
VAL_ 492 Dsp_SetIntroScan_Rq 7 "Reserved4" 6 "Reserved3" 5 "Reserved2" 4 "Reserved1" 3 "OnTheFolderSelGroup" 2 "OnTheDevice" 1 "Off" 0 "Inactive" ;
VAL_ 492 Dsp_SetShuffle_Rq 7 "Reserved4" 6 "Reserved3" 5 "Reserved2" 4 "Reserved1" 3 "OnTheFolderSelGroup" 2 "OnTheDevice" 1 "Off" 0 "Inactive" ;
VAL_ 495 HEC_BTIncomingCall2_Rq 2 "DeclineIncomingCall" 1 "AcceptIncomingCall" 0 "Inactive" ;
VAL_ 495 HEC_BTEndTelService2_Rq 1 "EndOngoingTelephonyCall" 0 "Inactive" ;
VAL_ 495 HEC_BTGetActDevActFeat_Rq 1 "Getstatus" 0 "Inactive" ;
VAL_ 509 Dsp_DB1SetTrkSetConf_Rq 31 "UnknownActive" 30 "Reserved_last" 9 "Reserved" 8 "Podcast" 7 "Audiobook" 6 "Composer" 5 "Track" 4 "Genre" 3 "Album" 2 "Artist" 1 "Playlist" 0 "Root" ;
VAL_ 509 Dsp_DB1SetTrkSetFilt3_Rq 1023 "All" 1022 "SIIndex_1022" 1 "SIIndex_1" 0 "NotEngaged" ;
VAL_ 509 Dsp_DB1SetTrkSetFilt2_Rq 65535 "All" 65534 "SIIndex_65534" 1 "SIIndex_1" 0 "NotEngaged" ;
VAL_ 509 Dsp_DB1SetTrkSetFilt1_Rq 65535 "All" 65534 "SIIndex_65534" 1 "SIIndex_1" 0 "NotEngaged" ;
VAL_ 72 PowerMode_UB 1 "Active" 0 "Inactive" ;
VAL_ 72 CarMode 5 "Crash" 3 "Transport" 1 "Factory" 0 "Normal" ;
VAL_ 72 PowerModeQF 3 "PowerModeOK" 2 "NotDefined" 1 "PwrModeEvaluatInProgress" 0 "PowerModeUndefined" ;
VAL_ 72 PowerMode 10 "Not_Used1" 8 "Not_Used" 3 "PostAccessory_0" 2 "KeyApproved_0" 9 "Crank_3" 7 "Running_2" 6 "IgnitionOn_2" 5 "PostIgnition_1" 4 "Accessory_1" 1 "KeyRecentlyOut" 0 "KeyOut" ;
VAL_ 466 Dsp_BTAud_SetOpMode_Rq 7 "FastRewind20" 6 "FastRewind10" 5 "FastForward20" 4 "FastForward10" 3 "Pause" 2 "Play" 1 "Stop" 0 "Inactive" ;
VAL_ 466 Dsp_iPod_SetOpMode_Rq 7 "FastRewind20" 6 "FastRewind10" 5 "FastForward20" 4 "FastForward10" 3 "Pause" 2 "Play" 1 "Stop" 0 "Inactive" ;
VAL_ 466 Dsp_USB_SetOpMode_Rq 7 "FastRewind20" 6 "FastRewind10" 5 "FastForward20" 4 "FastForward10" 3 "Pause" 2 "Play" 1 "Stop" 0 "Inactive" ;
VAL_ 1235 MFD_CutItem_St 3 "ThreeQuarterFromTheBeginningOneQ" 2 "End" 1 "Beginning" 0 "Invalid" ;
VAL_ 1235 MFD_ConICPConfiguration 8 "Reserved4" 7 "ICP_Level4" 6 "Reserved3" 5 "ICP_Level3" 4 "Reserved2" 3 "ICP_Level2" 2 "ICP_LowNavMFD" 1 "ICP_Level1" 0 "Invalid" ;
VAL_ 1235 MFD_InfotainmentVer_St 1 "B299" 0 "Invalid" ;
VAL_ 1235 MFD_Configuration 8 "Reserved4" 7 "PremiumMFD" 6 "Reserved3" 5 "HighMFD" 4 "Reserved2" 3 "MidMFD" 2 "LowNavMFD" 1 "LowMFD" 0 "Invalid" ;
VAL_ 502 Dsp_AudioSourceSel2_Rq 4 "Reserved" 3 "USB" 2 "BTAudio" 1 "CD" 0 "Inactive" ;
VAL_ 502 Dsp_CutItem2_Rq 3 "Inactive" 2 "ThreeQuarterFromTheBeginningOneQ" 1 "End" 0 "Beginning" ;
VAL_ 502 Dsp_FolderContent_Rq 2 "Inactive" 1 "RequestContentFromParentFolderOf" 0 "RequestContentFromParameterFolde" ;
